VERSION ""

NS_ :

BS_:
BU_: Turbocharger OnBoardDataLogger OffBoardDiagnosticTool2 OffBoardDiagnosticTool1 FileServer ParkingBrakeController SeatControl2 FanDriveController SteeringColumnUnit CommunicationUnitRadio CommunicationUnitSatellite CommunicationUnitCellular PropulsionBatteryCharger ChassisController2 ChassisController1 EngineValveControl AuxiliaryHeater2 AuxiliaryHeater1 ClutchUnit RampControl InformationSystem1 SuspensionSystemController2 OilSensor VehicleDynamicStability ExhaustEmissionController TransmissionDisplay2 TransmissionDisplay1 ClimateControl2 WaterPumpController RearAxleSteeringController LightingOperatorControl SeatController1 IgnitionController2 IgnitionController1 TirePressureController CabController2 CabController1 PneumaticSystemController SuspensionSystemController1 HydraulicPumpController EnduranceBrakingSystem RetarderExhaustEngine2 OnBoardDiagnosticUnit HeadwayController RetarderExhaustEngine1 CabDisplay1 ManagementComputer VirtualTerminal OffVehicleGateway PowerTakeOffFront HitchControl AuxiliaryValveControl BodyController TractorTrailerBridge1 StarterSystem ElectricalSystem VehicleSecurity VehicleNavigation AerodynamicControl ElectricalChargingSystem ClimateControl1 TripRecorder InstrumentCluster SuspensionDriveAxle2 SuspensionDriveAxle1 SuspensionSteerAxle SteeringController FuelSystem CruiseControl RetarderDriveline RetarderEngine BrakesDriveAxle2 BrakesDriveAxle1 BrakesSystemController BrakesSteerAxle AxleDrive2 AxleDrive1 AxleSteering PowerTakeOff ShiftConsoleSecondary ShiftConsolePrimary Transmission2 Transmission1 Engine2 Engine1 Guidance Unnamed9933

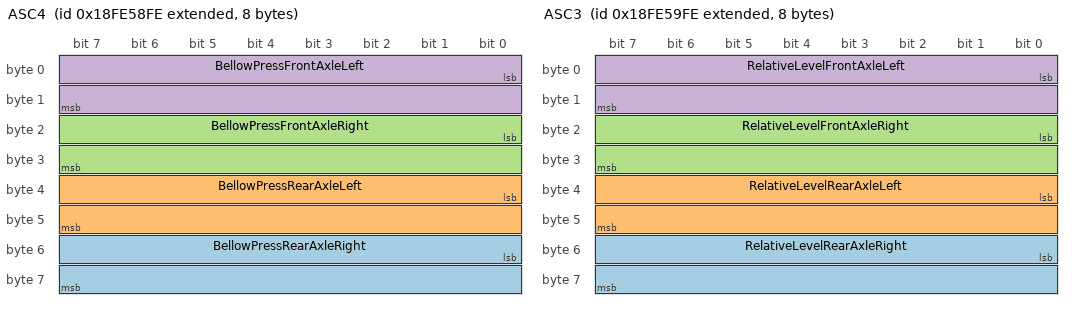
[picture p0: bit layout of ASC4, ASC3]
BO_ 2566805758 ASC4: 8 Vector__XXX
   SG_ BellowPressRearAxleRight : 48|16@1+ (0.1,0) [0|6425.5] "kPa" Vector__XXX
   SG_ BellowPressRearAxleLeft : 32|16@1+ (0.1,0) [0|6425.5] "kPa" Vector__XXX
   SG_ BellowPressFrontAxleRight : 16|16@1+ (0.1,0) [0|6425.5] "kPa" Vector__XXX
   SG_ BellowPressFrontAxleLeft : 0|16@1+ (0.1,0) [0|6425.5] "kPa" Vector__XXX

BO_ 2566806014 ASC3: 8 Vector__XXX
   SG_ RelativeLevelRearAxleRight : 48|16@1+ (0.1,-3200) [-3200|3225.5] "mm" Vector__XXX
   SG_ RelativeLevelRearAxleLeft : 32|16@1+ (0.1,-3200) [-3200|3225.5] "mm" Vector__XXX
   SG_ RelativeLevelFrontAxleRight : 16|16@1+ (0.1,-3200) [-3200|3225.5] "mm" Vector__XXX
   SG_ RelativeLevelFrontAxleLeft : 0|16@1+ (0.1,-3200) [-3200|3225.5] "mm" Vector__XXX

BO_ 2362638078 ASC2: 8 Vector__XXX
   SG_ SpeedDependentLevelCtrlRq : 56|2@1+ (1,0) [0|3] "" Vector__XXX
   SG_ PrhbtAutomaticAirSuspensionCtrl : 58|2@1+ (1,0) [0|3] "" Vector__XXX
   SG_ MemoryLevelRq : 60|4@1+ (1,0) [0|15] "" Vector__XXX
   SG_ AllowLevelCtrlDuringBrakingCmd : 54|2@1+ (1,0) [0|3] "" Vector__XXX
   SG_ ProhibitAirSuspensionCtrl : 52|2@1+ (1,0) [0|3] "" Vector__XXX
   SG_ KneelingCmdRearAxle : 50|2@1+ (1,0) [0|3] "" Vector__XXX
   SG_ KneelingCmdFrontAxle : 48|2@1+ (1,0) [0|3] "" Vector__XXX
   SG_ DamperStiffnessRqLift_TagAxle : 40|8@1+ (0.4,0) [0|100] "%" Vector__XXX
   SG_ DamperStiffnessRqRearAxle : 32|8@1+ (0.4,0) [0|100] "%" Vector__XXX
   SG_ DamperStiffnessRqFrontAxle : 24|8@1+ (0.4,0) [0|100] "%" Vector__XXX
   SG_ LevelCtrlModeRq : 16|4@1+ (1,0) [0|15] "" Vector__XXX
   SG_ NominalLevelRqRearAxle : 12|4@1+ (1,0) [0|15] "" Vector__XXX
   SG_ NominalLevelRqFrontAxle : 8|4@1+ (1,0) [0|15] "" Vector__XXX
   SG_ KneelingCtrlModeRq : 6|2@1+ (1,0) [0|3] "" Vector__XXX
   SG_ KneelingRqRightSide : 4|2@1+ (1,0) [0|3] "" Vector__XXX
   SG_ KneelingRqLeftSide : 2|2@1+ (1,0) [0|3] "" Vector__XXX
   SG_ AutomaticTractionHelp : 0|2@1+ (1,0) [0|3] "" Vector__XXX
   SG_ LiftAxle2PosCmd : 22|2@1+ (1,0) [0|3] "" Vector__XXX
   SG_ LiftAxle1PosCmd : 20|2@1+ (1,0) [0|3] "" Vector__XXX

BO_ 2365479678 ASC1: 8 Vector__XXX
   SG_ SpeedDependantLevelCtrlStatus : 54|2@1+ (1,0) [0|3] "" Vector__XXX
   SG_ MemoryLevel : 60|4@1+ (1,0) [0|15] "" Vector__XXX
   SG_ AllwLvelCtrlDuringBrakingStatus : 52|2@1+ (1,0) [0|3] "" Vector__XXX
   SG_ SspensionCtrlRefusalInformation : 56|4@1+ (1,0) [0|15] "" Vector__XXX
   SG_ SuspensionRemoteCtrl2 : 50|2@1+ (1,0) [0|3] "" Vector__XXX
   SG_ SuspensionRemoteCtrl1 : 48|2@1+ (1,0) [0|3] "" Vector__XXX
   SG_ RearAxleInBumperRange : 42|2@1+ (1,0) [0|3] "" Vector__XXX
   SG_ FrontAxleInBumperRange : 40|2@1+ (1,0) [0|3] "" Vector__XXX
   SG_ DoorRelease : 36|2@1+ (1,0) [0|3] "" Vector__XXX
   SG_ VehicleMotionInhibit : 34|2@1+ (1,0) [0|3] "" Vector__XXX
   SG_ SecurityDevice : 32|2@1+ (1,0) [0|3] "" Vector__XXX
   SG_ LevelCtrlMode : 28|4@1+ (1,0) [0|15] "" Vector__XXX
   SG_ KneelingInformation : 24|4@1+ (1,0) [0|15] "" Vector__XXX
   SG_ LiftingCtrlModeRearAxle : 22|2@1+ (1,0) [0|3] "" Vector__XXX
   SG_ LiftingCtrlModeFrontAxle : 20|2@1+ (1,0) [0|3] "" Vector__XXX
   SG_ LoweringCtrlModeRearAxle : 18|2@1+ (1,0) [0|3] "" Vector__XXX
   SG_ LoweringCtrlModeFrontAxle : 16|2@1+ (1,0) [0|3] "" Vector__XXX
   SG_ AboveNominalLevelRearAxle : 14|2@1+ (1,0) [0|3] "" Vector__XXX
   SG_ AboveNominalLevelFrontAxle : 12|2@1+ (1,0) [0|3] "" Vector__XXX
   SG_ BelowNominalLevelRearAxle : 10|2@1+ (1,0) [0|3] "" Vector__XXX
   SG_ BelowNominalLevelFrontAxle : 8|2@1+ (1,0) [0|3] "" Vector__XXX
   SG_ NominalLevelRearAxle : 4|4@1+ (1,0) [0|15] "" Vector__XXX
   SG_ NominalLevelFrontAxle : 0|4@1+ (1,0) [0|15] "" Vector__XXX
   SG_ LiftAxle2Pos : 46|2@1+ (1,0) [0|3] "" Vector__XXX
   SG_ LiftAxle1Pos : 38|2@1+ (1,0) [0|3] "" Vector__XXX

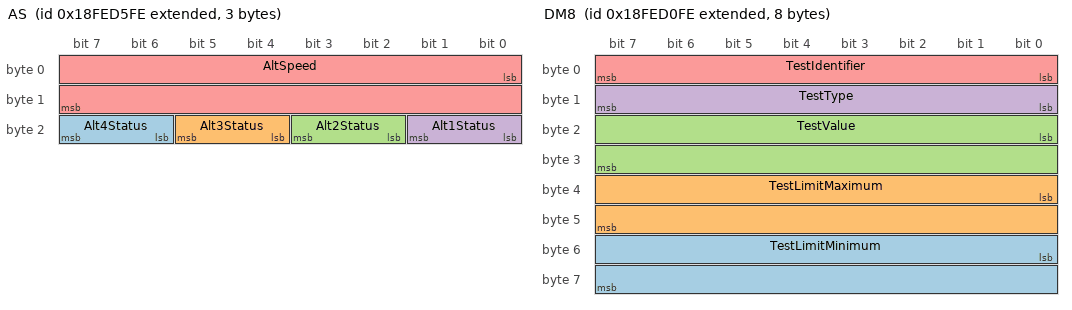
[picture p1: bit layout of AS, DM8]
BO_ 2566837758 AS: 3 Vector__XXX
   SG_ Alt4Status : 22|2@1+ (1,0) [0|3] "" Vector__XXX
   SG_ Alt3Status : 20|2@1+ (1,0) [0|3] "" Vector__XXX
   SG_ Alt2Status : 18|2@1+ (1,0) [0|3] "" Vector__XXX
   SG_ Alt1Status : 16|2@1+ (1,0) [0|3] "" Vector__XXX
   SG_ AltSpeed : 0|16@1+ (0.5,0) [0|32127.5] "rpm" Vector__XXX

BO_ 2633922558 AP: 8 Vector__XXX
   SG_ AuxAbsPressReading : 32|16@1+ (0.5,0) [0|32127.5] "kPa" Vector__XXX
   SG_ AuxGagePressReading1 : 16|16@1+ (0.5,0) [0|32127.5] "kPa" Vector__XXX
   SG_ AuxVacuumPressReading : 0|16@1+ (0.5,0) [0|32127.5] "kPa" Vector__XXX

BO_ 2566775038 AMB2: 8 Vector__XXX
   SG_ SpecificHumidity : 16|16@1+ (0.01,0) [0|642.55] "g/kg" Vector__XXX
   SG_ SolarSensorMax : 8|8@1+ (0.4,0) [0|100] "mW/cm/cm" Vector__XXX
   SG_ SolarIntensityPercent : 0|8@1+ (0.4,0) [0|100] "%" Vector__XXX

BO_ 2566836478 DM8: 8 Vector__XXX
   SG_ TestLimitMinimum : 48|16@1+ (1,0) [0|64255] "" Vector__XXX
   SG_ TestLimitMaximum : 32|16@1+ (1,0) [0|64255] "" Vector__XXX
   SG_ TestValue : 16|16@1+ (1,0) [0|64255] "" Vector__XXX
   SG_ TestType : 8|8@1+ (1,0) [1|64] "" Vector__XXX
   SG_ TestIdentifier : 0|8@1+ (1,0) [1|64] "" Vector__XXX

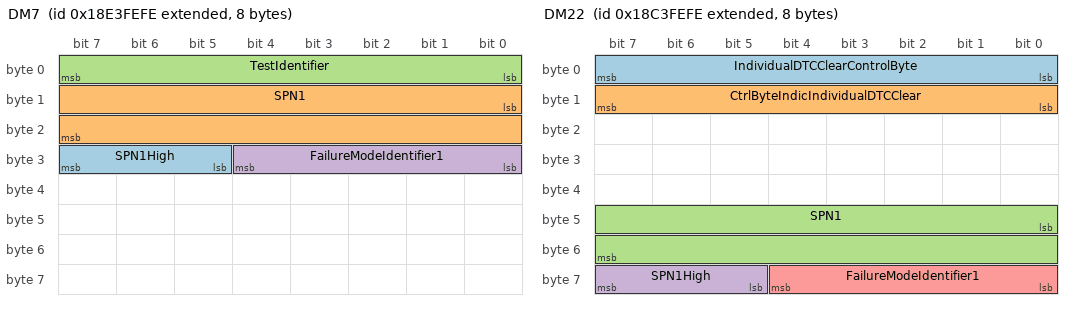
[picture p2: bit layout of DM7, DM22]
BO_ 2565078782 DM7: 8 Vector__XXX
   SG_ SPN1High : 29|3@1+ (1,0) [0|7] "" Vector__XXX
   SG_ SPN1 : 8|16@1+ (1,0) [0|65536] "" Vector__XXX
   SG_ TestIdentifier : 0|8@1+ (1,0) [1|64] "" Vector__XXX
   SG_ FailureModeIdentifier1 : 24|5@1+ (1,0) [0|0] "" Vector__XXX

BO_ 2566836222 DM6: 22 Vector__XXX
   SG_ FlashRedStopLamp : 12|2@1+ (1,0) [0|3] "" Vector__XXX
   SG_ FlashProtectLamp : 8|2@1+ (1,0) [0|3] "" Vector__XXX
   SG_ FlashMalfuncIndicatorLamp : 14|2@1+ (1,0) [0|3] "" Vector__XXX
   SG_ FlashAmberWarningLamp : 10|2@1+ (1,0) [0|3] "" Vector__XXX
   SG_ MalfunctionIndicatorLampStatus : 6|2@1+ (1,0) [0|3] "" Vector__XXX
   SG_ RedStopLampState : 4|2@1+ (1,0) [0|3] "" Vector__XXX
   SG_ AmberWarningLampStatus : 2|2@1+ (1,0) [0|3] "" Vector__XXX
   SG_ ProtectLampStatus : 0|2@1+ (1,0) [0|3] "" Vector__XXX
   SG_ DTC5 : 144|32@1+ (1,0) [0|4.29497e+09] "" Vector__XXX
   SG_ DTC4 : 112|32@1+ (1,0) [0|4.29497e+09] "" Vector__XXX
   SG_ DTC3 : 80|32@1+ (1,0) [0|4.29497e+09] "" Vector__XXX
   SG_ DTC2 : 48|32@1+ (1,0) [0|4.29497e+09] "" Vector__XXX
   SG_ DTC1 : 16|32@1+ (1,0) [0|4.29497e+09] "" Vector__XXX

BO_ 2566835966 DM5: 8 Vector__XXX
   SG_ BoostPressureControlSystemStatus : 57|1@1- (1,0) [0|0] "" Vector__XXX
   SG_ DieselParticulateFilterStatus : 58|1@1- (1,0) [0|0] "" Vector__XXX
   SG_ NOxConvertingCatalystAdsorberSta : 59|1@1- (1,0) [0|0] "" Vector__XXX
   SG_ NMHCConvertingCatalystStatus : 60|1@1- (1,0) [0|0] "" Vector__XXX
   SG_ BoostPressureControlSystemSuppor : 41|1@1- (1,0) [0|0] "" Vector__XXX
   SG_ DieselParticulateFilterSupport : 42|1@1- (1,0) [0|0] "" Vector__XXX
   SG_ NOxConvertingCatalystAdsorberSup : 43|1@1- (1,0) [0|0] "" Vector__XXX
   SG_ NMHCConvertingCatalystSupport : 44|1@1- (1,0) [0|0] "" Vector__XXX
   SG_ MisfireMonitoringSupport : 24|1@1+ (1,0) [0|0] "" Vector__XXX
   SG_ OBDCompliance : 16|8@1+ (1,0) [0|240] "" Vector__XXX
   SG_ PreviouslyActiveTroubleCodes : 8|8@1+ (1,0) [0|240] "" Vector__XXX
   SG_ ActiveTroubleCodes : 0|8@1+ (1,0) [0|240] "" Vector__XXX
   SG_ SecondAirSystemMonStatus : 51|1@1+ (1,0) [0|1] "" Vector__XXX
   SG_ EvaporativeSystemMonStatus : 50|1@1+ (1,0) [0|1] "" Vector__XXX
   SG_ ACSystemRefrigerantMonStatus : 52|1@1+ (1,0) [0|1] "" Vector__XXX
   SG_ OxygenSensorHeaterMonStatus : 54|1@1+ (1,0) [0|1] "" Vector__XXX
   SG_ OxygenSensorMonStatus : 53|1@1+ (1,0) [0|1] "" Vector__XXX
   SG_ EGRSystemMonitoringStatus : 55|1@1+ (1,0) [0|1] "" Vector__XXX
   SG_ CatalystMonStatus : 48|1@1+ (1,0) [0|1] "" Vector__XXX
   SG_ ColdStartAidSystemMonStatus : 56|1@1+ (1,0) [0|1] "" Vector__XXX
   SG_ HeatedCatalystMonStatus : 49|1@1+ (1,0) [0|0] "" Vector__XXX
   SG_ CatalystMonSupp : 32|1@1+ (1,0) [0|1] "" Vector__XXX
   SG_ ColdStartAidSystemMonSupp : 40|1@1+ (1,0) [0|1] "" Vector__XXX
   SG_ HeatedCatalystMonSupp : 33|1@1+ (1,0) [0|0] "" Vector__XXX
   SG_ EvaporativeSystemMonSupp : 34|1@1+ (1,0) [0|1] "" Vector__XXX
   SG_ SecondAirSystemMonSupp : 35|1@1+ (1,0) [0|1] "" Vector__XXX
   SG_ ACSystemRefrigerantMonSupp : 36|1@1+ (1,0) [0|1] "" Vector__XXX
   SG_ OxygenSensorMonSupp : 37|1@1+ (1,0) [0|1] "" Vector__XXX
   SG_ OxygenSensorHeaterMonSupp : 38|1@1+ (1,0) [0|1] "" Vector__XXX
   SG_ EGRSystemMonitoringSupp : 39|1@1+ (1,0) [0|1] "" Vector__XXX
   SG_ MisfireMonitoringStatus : 28|1@1+ (1,0) [0|0] "" Vector__XXX
   SG_ ComprehensiveCompMonStatus : 30|1@1+ (1,0) [0|1] "" Vector__XXX
   SG_ FuelSystemMonitoringStatus : 29|1@1+ (1,0) [0|1] "" Vector__XXX
   SG_ ComprehensiveComponentMonSupp : 26|1@1+ (1,0) [0|0] "" Vector__XXX
   SG_ FuelSystemMonitoringSupport : 25|1@1+ (1,0) [0|1] "" Vector__XXX

BO_ 2566835710 DM4: 13 Vector__XXX
   SG_ EngIntakeManifold1Press : 48|8@1+ (2,0) [0|500] "kPa" Vector__XXX
   SG_ FreezeFrameLength : 0|8@1+ (1,0) [0|255] "Byte" Vector__XXX
   SG_ EngSpeed : 56|16@1+ (0.125,0) [0|8031.88] "rpm" Vector__XXX
   SG_ EngTorqueMode : 40|4@1+ (1,0) [0|15] "" Vector__XXX
   SG_ WheelBasedVehicleSpeed : 88|16@1+ (0.00390625,0) [0|250.996] "km/h" Vector__XXX
   SG_ EngPercentLoadAtCurrentSpeed : 72|8@1+ (1,0) [0|250] "%" Vector__XXX
   SG_ EngineCoolantTemperature : 80|8@1+ (1,-40) [-40|210] "deg C" Vector__XXX
   SG_ DTC1 : 8|32@1+ (1,0) [0|4.29497e+09] "" Vector__XXX

BO_ 2566835454 DM3: 0 Vector__XXX

BO_ 2566764542 DM25: 13 Vector__XXX
   SG_ ExpandedFreezeFrameLength : 0|8@1+ (1,0) [0|255] "Byte" Vector__XXX
   SG_ DTC1 : 8|32@1+ (1,0) [0|4.29497e+09] "" Vector__XXX

BO_ 2566764286 DM24: 12 Vector__XXX
   SG_ SPNSupported1High : 21|3@1+ (1,0) [0|7] "" Vector__XXX
   SG_ SPNSupportTypeSTR3 : 82|1@1+ (1,0) [0|1] "" Vector__XXX
   SG_ SPNSupportTypeSTR2 : 81|1@1+ (1,0) [0|1] "" Vector__XXX
   SG_ SPNSupportTypeEFF3 : 80|1@1+ (1,0) [0|1] "" Vector__XXX
   SG_ SPNSupportTypeEFF2 : 48|1@1+ (1,0) [0|1] "" Vector__XXX
   SG_ SPNSupportTypeDS3 : 50|1@1+ (1,0) [0|1] "" Vector__XXX
   SG_ SPNSupportTypeDS2 : 49|1@1+ (1,0) [0|1] "" Vector__XXX
   SG_ SPNSupported3High : 85|3@1+ (1,0) [0|7] "" Vector__XXX
   SG_ SPNSupported2High : 53|3@1+ (1,0) [0|7] "" Vector__XXX
   SG_ SPNSupported3 : 64|16@1+ (1,0) [0|65535] "" Vector__XXX
   SG_ SPNSupported2 : 32|16@1+ (1,0) [0|65535] "" Vector__XXX
   SG_ SPNDataLength3 : 88|8@1+ (1,0) [0|240] "" Vector__XXX
   SG_ SPNSupportTypeSTR1 : 18|1@1+ (1,0) [0|1] "" Vector__XXX
   SG_ SPNSupportTypeDS1 : 17|1@1+ (1,0) [0|1] "" Vector__XXX
   SG_ SPNSupportTypeEFF1 : 16|1@1+ (1,0) [0|1] "" Vector__XXX
   SG_ SPNDataLength2 : 56|8@1+ (1,0) [0|240] "" Vector__XXX
   SG_ SPNDataLength1 : 24|8@1+ (1,0) [0|240] "" Vector__XXX
   SG_ SPNSupported1 : 0|16@1+ (1,0) [0|65535] "" Vector__XXX

BO_ 2566764030 DM23: 22 Vector__XXX
   SG_ FlashRedStopLamp : 12|2@1+ (1,0) [0|3] "" Vector__XXX
   SG_ FlashProtectLamp : 8|2@1+ (1,0) [0|3] "" Vector__XXX
   SG_ FlashMalfuncIndicatorLamp : 14|2@1+ (1,0) [0|3] "" Vector__XXX
   SG_ FlashAmberWarningLamp : 10|2@1+ (1,0) [0|3] "" Vector__XXX
   SG_ MalfunctionIndicatorLampStatus : 6|2@1+ (1,0) [0|3] "" Vector__XXX
   SG_ RedStopLampState : 4|2@1+ (1,0) [0|3] "" Vector__XXX
   SG_ AmberWarningLampStatus : 2|2@1+ (1,0) [0|3] "" Vector__XXX
   SG_ ProtectLampStatus : 0|2@1+ (1,0) [0|3] "" Vector__XXX
   SG_ DTC5 : 144|32@1+ (1,0) [0|4.29497e+09] "" Vector__XXX
   SG_ DTC4 : 112|32@1+ (1,0) [0|4.29497e+09] "" Vector__XXX
   SG_ DTC3 : 80|32@1+ (1,0) [0|4.29497e+09] "" Vector__XXX
   SG_ DTC2 : 48|32@1+ (1,0) [0|4.29497e+09] "" Vector__XXX
   SG_ DTC1 : 16|32@1+ (1,0) [0|4.29497e+09] "" Vector__XXX

BO_ 2562981630 DM22: 8 Vector__XXX
   SG_ IndividualDTCClearControlByte : 0|8@1+ (1,0) [0|255] "" Vector__XXX
   SG_ CtrlByteIndicIndividualDTCClear : 8|8@1+ (1,0) [0|255] "" Vector__XXX
   SG_ SPN1 : 40|16@1+ (1,0) [0|65536] "" Vector__XXX
   SG_ SPN1High : 61|3@1+ (1,0) [0|7] "" Vector__XXX
   SG_ FailureModeIdentifier1 : 56|5@1+ (1,0) [0|0] "" Vector__XXX

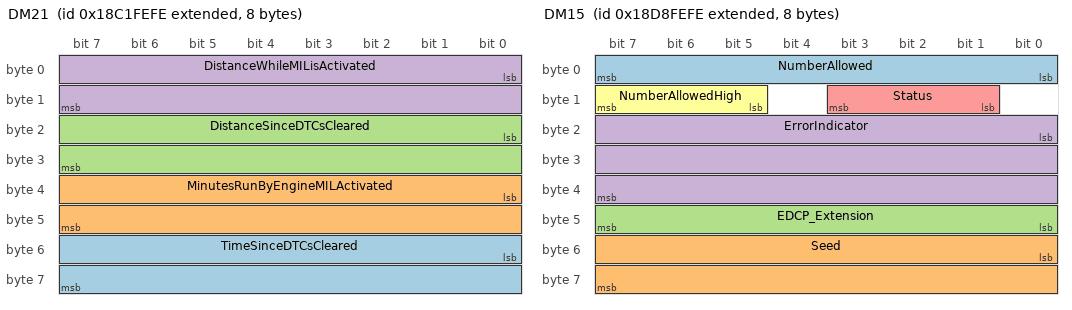
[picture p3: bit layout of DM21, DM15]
BO_ 2562850558 DM21: 8 Vector__XXX
   SG_ TimeSinceDTCsCleared : 48|16@1+ (1,0) [0|64255] "mins" Vector__XXX
   SG_ MinutesRunByEngineMILActivated : 32|16@1+ (1,0) [0|64255] "mins" Vector__XXX
   SG_ DistanceSinceDTCsCleared : 16|16@1+ (1,0) [0|64255] "km" Vector__XXX
   SG_ DistanceWhileMILisActivated : 0|16@1+ (1,0) [0|64255] "km" Vector__XXX

BO_ 2562916094 DM20: 11 Vector__XXX
   SG_ ApplSysMonitorDenominator : 72|16@1+ (1,0) [0|65535] "" Vector__XXX
   SG_ ApplSysMonitorNumerator : 56|16@1+ (1,0) [0|65535] "" Vector__XXX
   SG_ SPNofApplSysMonitor : 32|24@1+ (1,0) [0|524287] "" Vector__XXX
   SG_ OBDMonitoringCondEncountered : 16|16@1+ (1,0) [0|65535] "" Vector__XXX
   SG_ IgnitionCycleCounter : 0|16@1+ (1,0) [0|65535] "" Vector__XXX

BO_ 2566835198 DM2: 22 Vector__XXX
   SG_ MalfunctionIndicatorLampStatus : 6|2@1+ (1,0) [0|3] "" Vector__XXX
   SG_ RedStopLampState : 4|2@1+ (1,0) [0|3] "" Vector__XXX
   SG_ AmberWarningLampStatus : 2|2@1+ (1,0) [0|3] "" Vector__XXX
   SG_ ProtectLampStatus : 0|2@1+ (1,0) [0|3] "" Vector__XXX
   SG_ FlashRedStopLamp : 12|2@1+ (1,0) [0|3] "" Vector__XXX
   SG_ FlashProtectLamp : 8|2@1+ (1,0) [0|3] "" Vector__XXX
   SG_ FlashMalfuncIndicatorLamp : 14|2@1+ (1,0) [0|3] "" Vector__XXX
   SG_ FlashAmberWarningLamp : 10|2@1+ (1,0) [0|3] "" Vector__XXX
   SG_ DTC5 : 144|32@1+ (1,0) [0|4.29497e+09] "" Vector__XXX
   SG_ DTC4 : 112|32@1+ (1,0) [0|4.29497e+09] "" Vector__XXX
   SG_ DTC3 : 80|32@1+ (1,0) [0|4.29497e+09] "" Vector__XXX
   SG_ DTC2 : 48|32@1+ (1,0) [0|4.29497e+09] "" Vector__XXX
   SG_ DTC1 : 16|32@1+ (1,0) [0|4.29497e+09] "" Vector__XXX

BO_ 2564030206 DM19: 20 Vector__XXX
   SG_ CalibrationID4 : 128|32@1+ (1,0) [0|4.29497e+09] "" Vector__XXX
   SG_ CalibrationID3 : 96|32@1+ (1,0) [0|4.29497e+09] "" Vector__XXX
   SG_ CalibrationID2 : 64|32@1+ (1,0) [0|4.29497e+09] "" Vector__XXX
   SG_ CalibrationID1 : 32|32@1+ (1,0) [0|4.29497e+09] "" Vector__XXX
   SG_ CalibrationVerificationNumber : 0|32@1+ (1,0) [0|4.29497e+09] "" Vector__XXX

BO_ 2564226814 DM17: 1 Vector__XXX
   SG_ BootLoadData : 0|8@1- (1,0) [0|0] "" Vector__XXX

BO_ 2564292350 DM16: 2 Vector__XXX
   SG_ RawBinaryData : 8|8@1- (1,0) [0|0] "" Vector__XXX
   SG_ NumberOfOccurance : 0|8@1+ (1,0) [0|0] "" Vector__XXX

BO_ 2564357886 DM15: 8 Vector__XXX
   SG_ NumberAllowed : 0|8@1+ (1,0) [0|2047] "" Vector__XXX
   SG_ Seed : 48|16@1+ (1,0) [0|65535] "" Vector__XXX
   SG_ EDCP_Extension : 40|8@1+ (1,0) [0|255] "" Vector__XXX
   SG_ ErrorIndicator : 16|24@1+ (1,0) [0|1.67772e+07] "" Vector__XXX
   SG_ Status : 9|3@1+ (1,0) [0|7] "" Vector__XXX
   SG_ NumberAllowedHigh : 13|3@1+ (1,0) [0|7] "" Vector__XXX

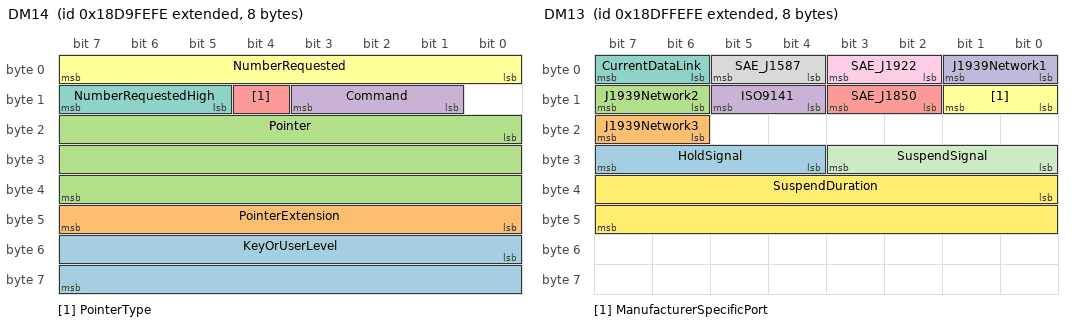
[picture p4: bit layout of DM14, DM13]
BO_ 2564423422 DM14: 8 Vector__XXX
   SG_ KeyOrUserLevel : 48|16@1+ (1,0) [0|65535] "" Vector__XXX
   SG_ PointerExtension : 40|8@1+ (1,0) [0|255] "" Vector__XXX
   SG_ Pointer : 16|24@1+ (1,0) [0|1.67772e+07] "" Vector__XXX
   SG_ Command : 9|3@1+ (1,0) [0|7] "" Vector__XXX
   SG_ PointerType : 12|1@1+ (1,0) [0|1] "" Vector__XXX
   SG_ NumberRequested : 0|8@1+ (1,0) [0|2047] "" Vector__XXX
   SG_ NumberRequestedHigh : 13|3@1+ (1,0) [0|7] "" Vector__XXX

BO_ 2564816638 DM13: 8 Vector__XXX
   SG_ HoldSignal : 28|4@1+ (1,0) [0|15] "" Vector__XXX
   SG_ J1939Network3 : 22|2@1+ (1,0) [0|3] "" Vector__XXX
   SG_ J1939Network2 : 14|2@1+ (1,0) [0|3] "" Vector__XXX
   SG_ ISO9141 : 12|2@1+ (1,0) [0|3] "" Vector__XXX
   SG_ SAE_J1850 : 10|2@1+ (1,0) [0|3] "" Vector__XXX
   SG_ ManufacturerSpecificPort : 8|2@1+ (1,0) [0|3] "" Vector__XXX
   SG_ CurrentDataLink : 6|2@1+ (1,0) [0|3] "" Vector__XXX
   SG_ SAE_J1587 : 4|2@1+ (1,0) [0|3] "" Vector__XXX
   SG_ SAE_J1922 : 2|2@1+ (1,0) [0|3] "" Vector__XXX
   SG_ J1939Network1 : 0|2@1+ (1,0) [0|3] "" Vector__XXX
   SG_ SuspendSignal : 24|4@1+ (1,0) [0|15] "" Vector__XXX
   SG_ SuspendDuration : 32|16@1+ (1,0) [0|64255] "sec" Vector__XXX

BO_ 2566837502 DM12: 22 Vector__XXX
   SG_ FlashRedStopLamp : 12|2@1+ (1,0) [0|3] "" Vector__XXX
   SG_ FlashProtectLamp : 8|2@1+ (1,0) [0|3] "" Vector__XXX
   SG_ MalfunctionIndicatorLampStatus : 6|2@1+ (1,0) [0|3] "" Vector__XXX
   SG_ RedStopLampState : 4|2@1+ (1,0) [0|3] "" Vector__XXX
   SG_ AmberWarningLampStatus : 2|2@1+ (1,0) [0|3] "" Vector__XXX
   SG_ ProtectLampStatus : 0|2@1+ (1,0) [0|3] "" Vector__XXX
   SG_ FlashMalfuncIndicatorLamp : 14|2@1+ (1,0) [0|3] "" Vector__XXX
   SG_ FlashAmberWarningLamp : 10|2@1+ (1,0) [0|3] "" Vector__XXX
   SG_ DTC5 : 144|32@1+ (1,0) [0|4.29497e+09] "" Vector__XXX
   SG_ DTC4 : 112|32@1+ (1,0) [0|4.29497e+09] "" Vector__XXX
   SG_ DTC3 : 80|32@1+ (1,0) [0|4.29497e+09] "" Vector__XXX
   SG_ DTC2 : 48|32@1+ (1,0) [0|4.29497e+09] "" Vector__XXX
   SG_ DTC1 : 16|32@1+ (1,0) [0|4.29497e+09] "" Vector__XXX

BO_ 2566837246 DM11: 0 Vector__XXX

BO_ 2566836990 DM10: 8 Vector__XXX
   SG_ TestIdentifierSupported : 0|64@1+ (1,0) [1|1.84467e+19] "" Vector__XXX

BO_ 2566834942 DM1: 22 Vector__XXX
   SG_ FlashRedStopLamp : 12|2@1+ (1,0) [0|3] "" Vector__XXX
   SG_ FlashProtectLamp : 8|2@1+ (1,0) [0|3] "" Vector__XXX
   SG_ FlashMalfuncIndicatorLamp : 14|2@1+ (1,0) [0|3] "" Vector__XXX
   SG_ FlashAmberWarningLamp : 10|2@1+ (1,0) [0|3] "" Vector__XXX
   SG_ MalfunctionIndicatorLampStatus : 6|2@1+ (1,0) [0|3] "" Vector__XXX
   SG_ AmberWarningLampStatus : 2|2@1+ (1,0) [0|3] "" Vector__XXX
   SG_ RedStopLampState : 4|2@1+ (1,0) [0|3] "" Vector__XXX
   SG_ ProtectLampStatus : 0|2@1+ (1,0) [0|3] "" Vector__XXX
   SG_ DTC5 : 144|32@1+ (1,0) [0|4.29497e+09] "" Vector__XXX
   SG_ DTC4 : 112|32@1+ (1,0) [0|4.29497e+09] "" Vector__XXX
   SG_ DTC3 : 80|32@1+ (1,0) [0|4.29497e+09] "" Vector__XXX
   SG_ DTC2 : 48|32@1+ (1,0) [0|4.29497e+09] "" Vector__XXX
   SG_ DTC1 : 16|32@1+ (1,0) [0|4.29497e+09] "" Vector__XXX

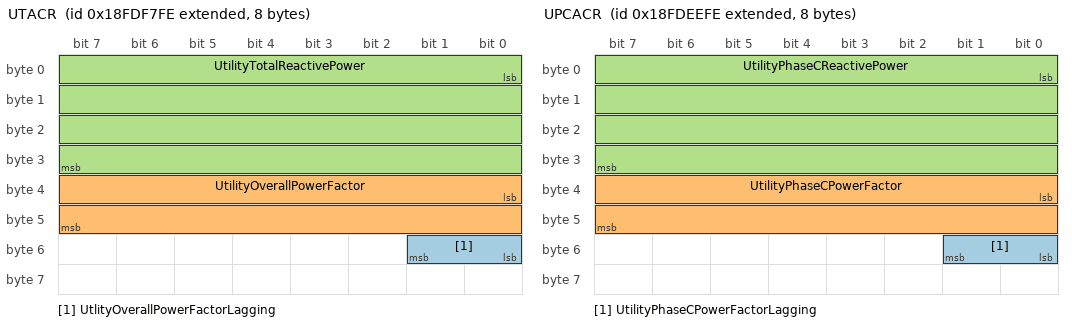
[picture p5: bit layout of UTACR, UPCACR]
BO_ 2566780926 UTACR: 8 Vector__XXX
   SG_ UtlityOverallPowerFactorLagging : 48|2@1+ (1,0) [0|3] "" Vector__XXX
   SG_ UtilityOverallPowerFactor : 32|16@1+ (1,-1) [-1|2.92181] "" Vector__XXX
   SG_ UtilityTotalReactivePower : 0|32@1+ (1,-2e+09) [-2e+09|2.21108e+09] "VAr" Vector__XXX

BO_ 2566781182 UTACP: 8 Vector__XXX
   SG_ UtilityTotalApparentPower : 32|32@1+ (1,-2e+09) [-2e+09|2.21108e+09] "VA" Vector__XXX
   SG_ UtilityTotalRealPower : 0|32@1+ (1,-2e+09) [-2e+09|2.21108e+09] "W" Vector__XXX

BO_ 2566778366 UTACE: 8 Vector__XXX
   SG_ UtilityTotalKWHoursImport : 32|32@1+ (1,0) [0|4.21108e+09] "kWh" Vector__XXX
   SG_ UtilityTotalKWHoursExport : 0|32@1+ (1,0) [0|4.21108e+09] "kWh" Vector__XXX

BO_ 2566778622 UPCACR: 8 Vector__XXX
   SG_ UtilityPhaseCPowerFactorLagging : 48|2@1+ (1,0) [0|3] "" Vector__XXX
   SG_ UtilityPhaseCPowerFactor : 32|16@1+ (1,-1) [-1|2.92181] "" Vector__XXX
   SG_ UtilityPhaseCReactivePower : 0|32@1+ (1,-2e+09) [-2e+09|2.21108e+09] "VAr" Vector__XXX

BO_ 2566778878 UPCACP: 8 Vector__XXX
   SG_ UtilityPhaseCApparentPower : 32|32@1+ (1,-2e+09) [-2e+09|2.21108e+09] "VA" Vector__XXX
   SG_ UtilityPhaseCRealPower : 0|32@1+ (1,-2e+09) [-2e+09|2.21108e+09] "W" Vector__XXX

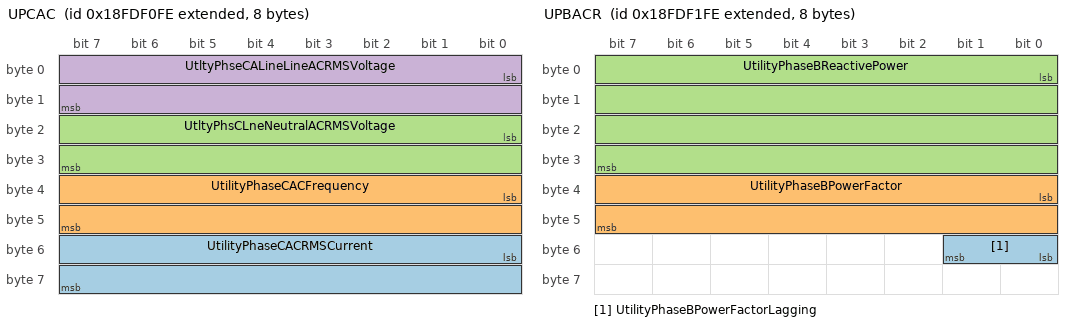
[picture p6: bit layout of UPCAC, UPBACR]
BO_ 2566779134 UPCAC: 8 Vector__XXX
   SG_ UtilityPhaseCACRMSCurrent : 48|16@1+ (1,0) [0|64255] "A" Vector__XXX
   SG_ UtilityPhaseCACFrequency : 32|16@1+ (1,0) [0|501.992] "Hz" Vector__XXX
   SG_ UtltyPhsCLneNeutralACRMSVoltage : 16|16@1+ (1,0) [0|64255] "V" Vector__XXX
   SG_ UtltyPhseCALineLineACRMSVoltage : 0|16@1+ (1,0) [0|64255] "V" Vector__XXX

BO_ 2566779390 UPBACR: 8 Vector__XXX
   SG_ UtilityPhaseBPowerFactorLagging : 48|2@1+ (1,0) [0|3] "" Vector__XXX
   SG_ UtilityPhaseBPowerFactor : 32|16@1+ (1,-1) [-1|2.92181] "" Vector__XXX
   SG_ UtilityPhaseBReactivePower : 0|32@1+ (1,-2e+09) [-2e+09|2.21108e+09] "VAr" Vector__XXX

BO_ 2566779646 UPBACP: 8 Vector__XXX
   SG_ UtilityPhaseBApparentPower : 32|32@1+ (1,-2e+09) [-2e+09|2.21108e+09] "VA" Vector__XXX
   SG_ UtilityPhaseBRealPower : 0|32@1+ (1,-2e+09) [-2e+09|2.21108e+09] "W" Vector__XXX

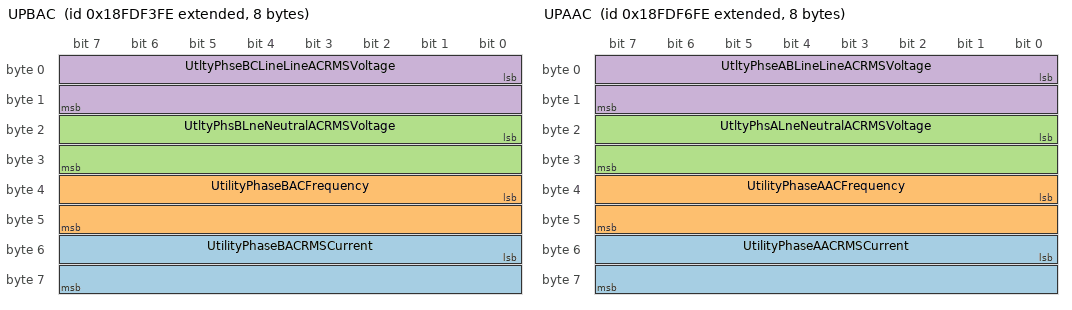
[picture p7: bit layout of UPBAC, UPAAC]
BO_ 2566779902 UPBAC: 8 Vector__XXX
   SG_ UtilityPhaseBACRMSCurrent : 48|16@1+ (1,0) [0|64255] "A" Vector__XXX
   SG_ UtilityPhaseBACFrequency : 32|16@1+ (1,0) [0|501.992] "Hz" Vector__XXX
   SG_ UtltyPhsBLneNeutralACRMSVoltage : 16|16@1+ (1,0) [0|64255] "V" Vector__XXX
   SG_ UtltyPhseBCLineLineACRMSVoltage : 0|16@1+ (1,0) [0|64255] "V" Vector__XXX

BO_ 2566780158 UPACCR: 8 Vector__XXX
   SG_ UtilityPhaseAPowerFactorLagging : 48|2@1+ (1,0) [0|3] "" Vector__XXX
   SG_ UtilityPhaseAPowerFactor : 32|16@1+ (1,-1) [-1|2.92181] "" Vector__XXX
   SG_ UtilityPhaseAReactivePower : 0|32@1+ (1,-2e+09) [-2e+09|2.21108e+09] "VAr" Vector__XXX

BO_ 2566780414 UPAACP: 8 Vector__XXX
   SG_ UtilityPhaseAApparentPower : 32|32@1+ (1,-2e+09) [-2e+09|2.21108e+09] "VA" Vector__XXX
   SG_ UtilityPhaseARealPower : 0|32@1+ (1,-2e+09) [-2e+09|2.21108e+09] "W" Vector__XXX

BO_ 2566780670 UPAAC: 8 Vector__XXX
   SG_ UtilityPhaseAACRMSCurrent : 48|16@1+ (1,0) [0|64255] "A" Vector__XXX
   SG_ UtilityPhaseAACFrequency : 32|16@1+ (1,0) [0|501.992] "Hz" Vector__XXX
   SG_ UtltyPhsALneNeutralACRMSVoltage : 16|16@1+ (1,0) [0|64255] "V" Vector__XXX
   SG_ UtltyPhseABLineLineACRMSVoltage : 0|16@1+ (1,0) [0|64255] "V" Vector__XXX

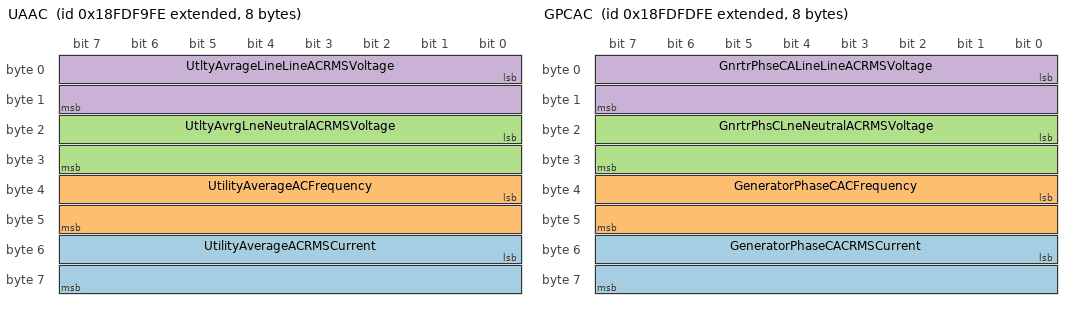
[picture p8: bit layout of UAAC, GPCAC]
BO_ 2566781438 UAAC: 8 Vector__XXX
   SG_ UtilityAverageACRMSCurrent : 48|16@1+ (1,0) [0|64255] "A" Vector__XXX
   SG_ UtilityAverageACFrequency : 32|16@1+ (1,0) [0|501.992] "Hz" Vector__XXX
   SG_ UtltyAvrgLneNeutralACRMSVoltage : 16|16@1+ (1,0) [0|64255] "V" Vector__XXX
   SG_ UtltyAvrageLineLineACRMSVoltage : 0|16@1+ (1,0) [0|64255] "V" Vector__XXX

BO_ 2566784254 GTACR: 8 Vector__XXX
   SG_ GnrtorOverallPowerFactorLagging : 48|2@1+ (1,0) [0|3] "" Vector__XXX
   SG_ GeneratorOverallPowerFactor : 32|16@1+ (1,-1) [-1|2.92181] "" Vector__XXX
   SG_ GeneratorTotalReactivePower : 0|32@1+ (1,-2e+09) [-2e+09|2.21108e+09] "VAr" Vector__XXX

BO_ 2566784510 GTACP: 8 Vector__XXX
   SG_ GeneratorTotalApparentPower : 32|32@1+ (1,-2e+09) [-2e+09|2.21108e+09] "VA" Vector__XXX
   SG_ GeneratorTotalRealPower : 0|32@1+ (1,-2e+09) [-2e+09|2.21108e+09] "W" Vector__XXX

BO_ 2566781694 GTACE: 8 Vector__XXX
   SG_ GeneratorTotalKWHoursImport : 32|32@1+ (1,0) [0|4.21108e+09] "kWh" Vector__XXX
   SG_ GeneratorTotalKWHoursExport : 0|32@1+ (1,0) [0|4.21108e+09] "kWh" Vector__XXX

BO_ 2566781950 GPCACR: 8 Vector__XXX
   SG_ GnratorPhaseCPowerFactorLagging : 48|2@1+ (1,0) [0|3] "" Vector__XXX
   SG_ GeneratorPhaseCPowerFactor : 32|16@1+ (1,-1) [-1|2.92181] "" Vector__XXX
   SG_ GeneratorPhaseCReactivePower : 0|32@1+ (1,-2e+09) [-2e+09|2.21108e+09] "VAr" Vector__XXX

BO_ 2566782206 GPCACP: 8 Vector__XXX
   SG_ GeneratorPhaseCApparentPower : 32|32@1+ (1,-2e+09) [-2e+09|2.21108e+09] "VA" Vector__XXX
   SG_ GeneratorPhaseCRealPower : 0|32@1+ (1,-2e+09) [-2e+09|2.21108e+09] "W" Vector__XXX

BO_ 2566782462 GPCAC: 8 Vector__XXX
   SG_ GeneratorPhaseCACRMSCurrent : 48|16@1+ (1,0) [0|64255] "A" Vector__XXX
   SG_ GeneratorPhaseCACFrequency : 32|16@1+ (1,0) [0|501.992] "Hz" Vector__XXX
   SG_ GnrtrPhsCLneNeutralACRMSVoltage : 16|16@1+ (1,0) [0|64255] "V" Vector__XXX
   SG_ GnrtrPhseCALineLineACRMSVoltage : 0|16@1+ (1,0) [0|64255] "V" Vector__XXX

BO_ 2566782718 GPBACRP: 8 Vector__XXX
   SG_ GnratorPhaseBPowerFactorLagging : 48|2@1+ (1,0) [0|3] "" Vector__XXX
   SG_ GeneratorPhaseBPowerFactor : 32|16@1+ (1,-1) [-1|2.92181] "" Vector__XXX
   SG_ GeneratorPhaseBReactivePower : 0|32@1+ (1,-2e+09) [-2e+09|2.21108e+09] "VAr" Vector__XXX

BO_ 2566782974 GPBACP: 8 Vector__XXX
   SG_ GeneratorPhaseBApparentPower : 32|32@1+ (1,-2e+09) [-2e+09|2.21108e+09] "VA" Vector__XXX
   SG_ GeneratorPhaseBRealPower : 0|32@1+ (1,-2e+09) [-2e+09|2.21108e+09] "W" Vector__XXX

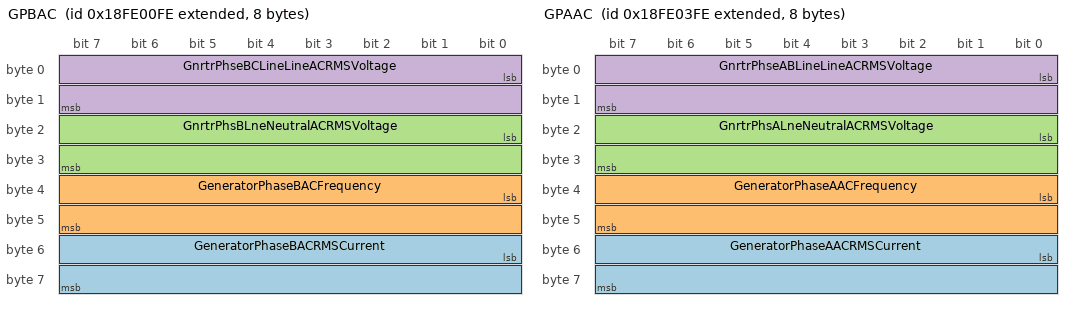
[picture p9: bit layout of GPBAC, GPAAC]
BO_ 2566783230 GPBAC: 8 Vector__XXX
   SG_ GeneratorPhaseBACRMSCurrent : 48|16@1+ (1,0) [0|64255] "A" Vector__XXX
   SG_ GeneratorPhaseBACFrequency : 32|16@1+ (1,0) [0|501.992] "Hz" Vector__XXX
   SG_ GnrtrPhsBLneNeutralACRMSVoltage : 16|16@1+ (1,0) [0|64255] "V" Vector__XXX
   SG_ GnrtrPhseBCLineLineACRMSVoltage : 0|16@1+ (1,0) [0|64255] "V" Vector__XXX

BO_ 2566783486 GPAACR: 8 Vector__XXX
   SG_ GnratorPhaseAPowerFactorLagging : 48|2@1+ (1,0) [0|3] "" Vector__XXX
   SG_ GeneratorPhaseAPowerFactor : 32|16@1+ (1,-1) [-1|2.92181] "" Vector__XXX
   SG_ GeneratorPhaseAReactivePower : 0|32@1+ (1,-2e+09) [-2e+09|2.21108e+09] "VAr" Vector__XXX

BO_ 2566783742 GPAACP: 8 Vector__XXX
   SG_ GeneratorPhaseAApparentPower : 32|32@1+ (1,-2e+09) [-2e+09|2.21108e+09] "VA" Vector__XXX
   SG_ GeneratorPhaseARealPower : 0|32@1+ (1,-2e+09) [-2e+09|2.21108e+09] "W" Vector__XXX

BO_ 2566783998 GPAAC: 8 Vector__XXX
   SG_ GeneratorPhaseAACRMSCurrent : 48|16@1+ (1,0) [0|64255] "A" Vector__XXX
   SG_ GeneratorPhaseAACFrequency : 32|16@1+ (1,0) [0|501.992] "Hz" Vector__XXX
   SG_ GnrtrPhsALneNeutralACRMSVoltage : 16|16@1+ (1,0) [0|64255] "V" Vector__XXX
   SG_ GnrtrPhseABLineLineACRMSVoltage : 0|16@1+ (1,0) [0|64255] "V" Vector__XXX

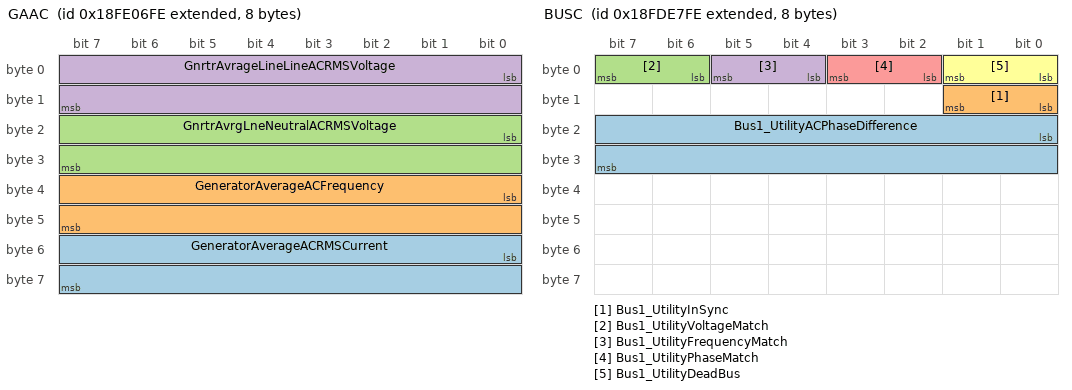
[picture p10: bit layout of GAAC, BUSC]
BO_ 2566784766 GAAC: 8 Vector__XXX
   SG_ GeneratorAverageACRMSCurrent : 48|16@1+ (1,0) [0|64255] "A" Vector__XXX
   SG_ GeneratorAverageACFrequency : 32|16@1+ (1,0) [0|501.992] "Hz" Vector__XXX
   SG_ GnrtrAvrgLneNeutralACRMSVoltage : 16|16@1+ (1,0) [0|64255] "V" Vector__XXX
   SG_ GnrtrAvrageLineLineACRMSVoltage : 0|16@1+ (1,0) [0|64255] "V" Vector__XXX

BO_ 2566776830 BUSC: 8 Vector__XXX
   SG_ Bus1_UtilityACPhaseDifference : 16|16@1+ (1,-200) [-200|301.99] "deg" Vector__XXX
   SG_ Bus1_UtilityInSync : 8|2@1+ (1,0) [0|3] "" Vector__XXX
   SG_ Bus1_UtilityVoltageMatch : 6|2@1+ (1,0) [0|3] "" Vector__XXX
   SG_ Bus1_UtilityFrequencyMatch : 4|2@1+ (1,0) [0|3] "" Vector__XXX
   SG_ Bus1_UtilityPhaseMatch : 2|2@1+ (1,0) [0|3] "" Vector__XXX
   SG_ Bus1_UtilityDeadBus : 0|2@1+ (1,0) [0|3] "" Vector__XXX

BO_ 2566777342 BPCAC: 8 Vector__XXX
   SG_ Bus1PhaseCACFrequency : 32|16@1+ (1,0) [0|501.992] "Hz" Vector__XXX
   SG_ Bs1PhseCLineNeutralACRMSVoltage : 16|16@1+ (1,0) [0|64255] "V" Vector__XXX
   SG_ Bus1PhaseCALineLineACRMSVoltage : 0|16@1+ (1,0) [0|64255] "V" Vector__XXX

BO_ 2566777598 BPBAC: 8 Vector__XXX
   SG_ Bus1PhaseBACFrequency : 32|16@1+ (1,0) [0|501.992] "Hz" Vector__XXX
   SG_ Bs1PhseBLineNeutralACRMSVoltage : 16|16@1+ (1,0) [0|64255] "V" Vector__XXX
   SG_ Bus1PhaseBCLineLineACRMSVoltage : 0|16@1+ (1,0) [0|64255] "V" Vector__XXX

BO_ 2566777854 BPAAC: 8 Vector__XXX
   SG_ Bus1PhaseAACFrequency : 32|16@1+ (1,0) [0|501.992] "Hz" Vector__XXX
   SG_ Bs1PhseALineNeutralACRMSVoltage : 16|16@1+ (1,0) [0|64255] "V" Vector__XXX
   SG_ Bus1PhaseABLineLineACRMSVoltage : 0|16@1+ (1,0) [0|64255] "V" Vector__XXX

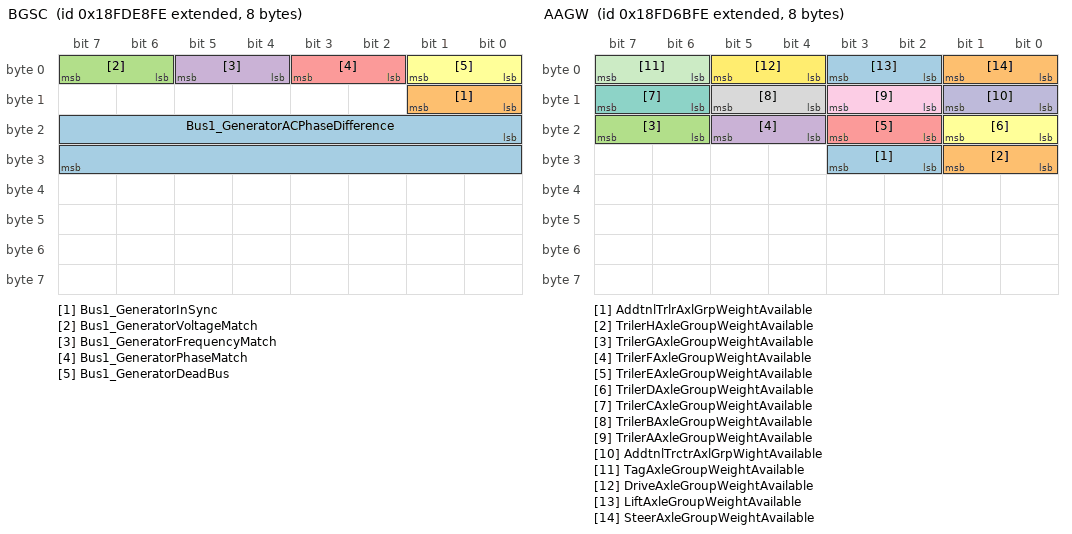
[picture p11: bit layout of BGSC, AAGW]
BO_ 2566777086 BGSC: 8 Vector__XXX
   SG_ Bus1_GeneratorACPhaseDifference : 16|16@1+ (1,-200) [-200|301.99] "deg" Vector__XXX
   SG_ Bus1_GeneratorInSync : 8|2@1+ (1,0) [0|3] "" Vector__XXX
   SG_ Bus1_GeneratorVoltageMatch : 6|2@1+ (1,0) [0|3] "" Vector__XXX
   SG_ Bus1_GeneratorFrequencyMatch : 4|2@1+ (1,0) [0|3] "" Vector__XXX
   SG_ Bus1_GeneratorPhaseMatch : 2|2@1+ (1,0) [0|3] "" Vector__XXX
   SG_ Bus1_GeneratorDeadBus : 0|2@1+ (1,0) [0|3] "" Vector__XXX

BO_ 2566778110 BAAC: 8 Vector__XXX
   SG_ Bus1AverageACFrequency : 32|16@1+ (1,0) [0|501.992] "Hz" Vector__XXX
   SG_ Bs1AvrgeLineNeutralACRMSVoltage : 16|16@1+ (1,0) [0|64255] "V" Vector__XXX
   SG_ Bus1AverageLineLineACRMSVoltage : 0|16@1+ (1,0) [0|64255] "V" Vector__XXX

BO_ 2633895422 WSMSTR: 8 Vector__XXX
   SG_ NumberOfMembers : 0|8@1+ (1,0) [0|0] "" Vector__XXX

BO_ 2566838526 CA: 9 Vector__XXX
   SG_ AddressAssignment : 64|8@1+ (1,0) [0|255] "" Vector__XXX
   SG_ ArbitraryAddressCapable : 63|1@1+ (1,0) [0|1] "" Vector__XXX
   SG_ IndustryGroup M : 60|3@1+ (1,0) [0|7] "" Vector__XXX
   SG_ VehicleSystemInstance : 56|4@1+ (1,0) [0|15] "" Vector__XXX
   SG_ Function : 40|8@1+ (1,0) [0|255] "" Vector__XXX
   SG_ VehicleSystem m0 : 49|7@1+ (1,0) [0|127] "" Vector__XXX
   SG_ FunctionInstance : 35|5@1+ (1,0) [0|31] "" Vector__XXX
   SG_ ECUInstance : 32|3@1+ (1,0) [0|7] "" Vector__XXX
   SG_ ManufacturerCode : 21|11@1+ (1,0) [0|2047] "" Vector__XXX
   SG_ IdentityNumber : 0|21@1+ (1,0) [0|2.09715e+06] "" Vector__XXX
   SG_ VehicleSystem5 m5 : 49|7@1+ (1,0) [0|127] "" Vector__XXX
   SG_ VehicleSystem4 m4 : 49|7@1+ (1,0) [0|127] "" Vector__XXX
   SG_ VehicleSystem3 m3 : 49|7@1+ (1,0) [0|127] "" Vector__XXX
   SG_ VehicleSystem2 m2 : 49|7@1+ (1,0) [0|127] "" Vector__XXX
   SG_ VehicleSystem1 m1 : 49|7@1+ (1,0) [0|127] "" Vector__XXX

BO_ 2565799678 ACL: 8 Vector__XXX
   SG_ ArbitraryAddressCapable : 63|1@1+ (1,0) [0|1] "" Vector__XXX
   SG_ IndustryGroup M : 60|3@1+ (1,0) [0|7] "" Vector__XXX
   SG_ VehicleSystemInstance : 56|4@1+ (1,0) [0|15] "" Vector__XXX
   SG_ Function : 40|8@1+ (1,0) [0|255] "" Vector__XXX
   SG_ FunctionInstance : 35|5@1+ (1,0) [0|31] "" Vector__XXX
   SG_ ECUInstance : 32|3@1+ (1,0) [0|7] "" Vector__XXX
   SG_ ManufacturerCode : 21|11@1+ (1,0) [0|2047] "" Vector__XXX
   SG_ IdentityNumber : 0|21@1+ (1,0) [0|2.09715e+06] "" Vector__XXX
   SG_ VehicleSystem m0 : 49|7@1+ (1,0) [0|127] "" Vector__XXX
   SG_ VehicleSystem5 m5 : 49|7@1+ (1,0) [0|127] "" Vector__XXX
   SG_ VehicleSystem4 m4 : 49|7@1+ (1,0) [0|127] "" Vector__XXX
   SG_ VehicleSystem3 m3 : 49|7@1+ (1,0) [0|127] "" Vector__XXX
   SG_ VehicleSystem2 m2 : 49|7@1+ (1,0) [0|127] "" Vector__XXX
   SG_ VehicleSystem1 m1 : 49|7@1+ (1,0) [0|127] "" Vector__XXX

BO_ 2563440382 XFER: 8 Vector__XXX
   SG_ ShrtNameOfActualReportingDevice : 32|32@1+ (1,0) [0|0] "(2^32 - 1)" Vector__XXX
   SG_ LengthOfDataForTheReportedPGN : 24|8@1+ (1,0) [0|255] "" Vector__XXX
   SG_ PGNofRequstedInformation : 0|24@1+ (1,0) [0|1.67772e+07] "" Vector__XXX

BO_ 2632711934 TPDT: 8 Vector__XXX
   SG_ SequenceNumber : 0|8@1+ (1,0) [0|255] "" Vector__XXX

BO_ 2632777470 TPCM: 8 Vector__XXX
   SG_ TotalNumberOfPacketsEoMA m19 : 24|8@1+ (1,0) [0|255] "" Vector__XXX
   SG_ TotalMessageSizeEoMA m19 : 8|16@1+ (1,0) [0|64255] "counts" Vector__XXX
   SG_ TotalMessageSizeBAM m32 : 8|16@1+ (1,0) [0|64255] "counts" Vector__XXX
   SG_ TotalNumberOfPacketsBAM m32 : 24|8@1+ (1,0) [0|255] "" Vector__XXX
   SG_ ConnectionAbortReason m255 : 8|8@1+ (1,0) [0|255] "" Vector__XXX
   SG_ NextPacketNumberToBeSent m17 : 16|8@1+ (1,0) [0|255] "" Vector__XXX
   SG_ NumberOfPacketsThatCanBeSent m17 : 8|8@1+ (1,0) [0|255] "" Vector__XXX
   SG_ PGNumber : 40|24@1+ (1,0) [0|1.67772e+07] "" Vector__XXX
   SG_ MaximumNumberOfPackets m16 : 32|8@1+ (1,0) [0|255] "" Vector__XXX
   SG_ TotalNumberOfPackets m16 : 24|8@1+ (1,0) [0|255] "" Vector__XXX
   SG_ TotalMessageSize m16 : 8|16@1+ (1,0) [0|64255] "counts" Vector__XXX
   SG_ ControlByte M : 0|8@1+ (1,0) [0|255] "" Vector__XXX

BO_ 2563374846 RQST2: 8 Vector__XXX
   SG_ UseTransferMode : 24|2@1+ (1,0) [0|3] "" Vector__XXX
   SG_ ParameterGroupNumber : 0|24@1+ (1,0) [0|1.67772e+07] "" Vector__XXX

BO_ 2565537534 RQST: 3 Vector__XXX
   SG_ ParameterGroupNumber : 0|24@1+ (1,0) [0|1.67772e+07] "" Vector__XXX

BO_ 2499635966 AGW: 8 Vector__XXX
   SG_ AxleGroupWeight : 8|16@1+ (2,0) [0|128510] "kg" Vector__XXX
   SG_ AxleGroupLocation : 0|4@1+ (1,0) [0|15] "" Vector__XXX

BO_ 2633853438 AGCW: 8 Vector__XXX
   SG_ AxleGroupLocation : 4|4@1+ (1,0) [0|15] "" Vector__XXX
   SG_ AxleGroupFullWeightCalib : 24|16@1+ (2,0) [0|128510] "kg" Vector__XXX
   SG_ AxleGroupEmptyWeightCalib : 8|16@1+ (2,0) [0|128510] "kg" Vector__XXX

BO_ 2432520702 ACCVC: 8 Vector__XXX
   SG_ DsrdAftrcoolerCoolantIntakeTemp : 8|8@1+ (1,-40) [-40|210] "deg C" Vector__XXX
   SG_ DsrdAftrclrClntThrmostatOpening : 16|8@1+ (0.4,0) [0|100] "%" Vector__XXX
   SG_ AftrcoolerCoolantThermostatMode : 0|2@1+ (1,0) [0|3] "" Vector__XXX

BO_ 2566745086 AAGW: 8 Vector__XXX
   SG_ AddtnlTrlrAxlGrpWeightAvailable : 26|2@1+ (1,0) [0|3] "" Vector__XXX
   SG_ TrilerHAxleGroupWeightAvailable : 24|2@1+ (1,0) [0|3] "" Vector__XXX
   SG_ TrilerGAxleGroupWeightAvailable : 22|2@1+ (1,0) [0|3] "" Vector__XXX
   SG_ TrilerFAxleGroupWeightAvailable : 20|2@1+ (1,0) [0|3] "" Vector__XXX
   SG_ TrilerEAxleGroupWeightAvailable : 18|2@1+ (1,0) [0|3] "" Vector__XXX
   SG_ TrilerDAxleGroupWeightAvailable : 16|2@1+ (1,0) [0|3] "" Vector__XXX
   SG_ TrilerCAxleGroupWeightAvailable : 14|2@1+ (1,0) [0|3] "" Vector__XXX
   SG_ TrilerBAxleGroupWeightAvailable : 12|2@1+ (1,0) [0|3] "" Vector__XXX
   SG_ TrilerAAxleGroupWeightAvailable : 10|2@1+ (1,0) [0|3] "" Vector__XXX
   SG_ AddtnlTrctrAxlGrpWightAvailable : 8|2@1+ (1,0) [0|3] "" Vector__XXX
   SG_ TagAxleGroupWeightAvailable : 6|2@1+ (1,0) [0|3] "" Vector__XXX
   SG_ DriveAxleGroupWeightAvailable : 4|2@1+ (1,0) [0|3] "" Vector__XXX
   SG_ LiftAxleGroupWeightAvailable : 2|2@1+ (1,0) [0|3] "" Vector__XXX
   SG_ SteerAxleGroupWeightAvailable : 0|2@1+ (1,0) [0|3] "" Vector__XXX

BO_ 2566739198 DM52: 22 Vector__XXX
   SG_ FlashRedStopLamp : 12|2@1+ (1,0) [0|3] "" Vector__XXX
   SG_ FlashProtectLamp : 8|2@1+ (1,0) [0|3] "" Vector__XXX
   SG_ FlashMalfuncIndicatorLamp : 14|2@1+ (1,0) [0|3] "" Vector__XXX
   SG_ FlashAmberWarningLamp : 10|2@1+ (1,0) [0|3] "" Vector__XXX
   SG_ MalfunctionIndicatorLampStatus : 6|2@1+ (1,0) [0|3] "" Vector__XXX
   SG_ AmberWarningLampStatus : 2|2@1+ (1,0) [0|3] "" Vector__XXX
   SG_ RedStopLampState : 4|2@1+ (1,0) [0|3] "" Vector__XXX
   SG_ ProtectLampStatus : 0|2@1+ (1,0) [0|3] "" Vector__XXX
   SG_ DTC5 : 144|32@1+ (1,0) [0|4.29497e+09] "" Vector__XXX
   SG_ DTC4 : 112|32@1+ (1,0) [0|4.29497e+09] "" Vector__XXX
   SG_ DTC3 : 80|32@1+ (1,0) [0|4.29497e+09] "" Vector__XXX
   SG_ DTC2 : 48|32@1+ (1,0) [0|4.29497e+09] "" Vector__XXX
   SG_ DTC1 : 16|32@1+ (1,0) [0|4.29497e+09] "" Vector__XXX

BO_ 2566739454 DM51: 22 Vector__XXX
   SG_ FlashRedStopLamp : 12|2@1+ (1,0) [0|3] "" Vector__XXX
   SG_ FlashProtectLamp : 8|2@1+ (1,0) [0|3] "" Vector__XXX
   SG_ FlashMalfuncIndicatorLamp : 14|2@1+ (1,0) [0|3] "" Vector__XXX
   SG_ FlashAmberWarningLamp : 10|2@1+ (1,0) [0|3] "" Vector__XXX
   SG_ MalfunctionIndicatorLampStatus : 6|2@1+ (1,0) [0|3] "" Vector__XXX
   SG_ AmberWarningLampStatus : 2|2@1+ (1,0) [0|3] "" Vector__XXX
   SG_ RedStopLampState : 4|2@1+ (1,0) [0|3] "" Vector__XXX
   SG_ ProtectLampStatus : 0|2@1+ (1,0) [0|3] "" Vector__XXX
   SG_ DTC5 : 144|32@1+ (1,0) [0|4.29497e+09] "" Vector__XXX
   SG_ DTC4 : 112|32@1+ (1,0) [0|4.29497e+09] "" Vector__XXX
   SG_ DTC3 : 80|32@1+ (1,0) [0|4.29497e+09] "" Vector__XXX
   SG_ DTC2 : 48|32@1+ (1,0) [0|4.29497e+09] "" Vector__XXX
   SG_ DTC1 : 16|32@1+ (1,0) [0|4.29497e+09] "" Vector__XXX

BO_ 2566739710 DM50: 22 Vector__XXX
   SG_ FlashRedStopLamp : 12|2@1+ (1,0) [0|3] "" Vector__XXX
   SG_ FlashProtectLamp : 8|2@1+ (1,0) [0|3] "" Vector__XXX
   SG_ FlashMalfuncIndicatorLamp : 14|2@1+ (1,0) [0|3] "" Vector__XXX
   SG_ FlashAmberWarningLamp : 10|2@1+ (1,0) [0|3] "" Vector__XXX
   SG_ MalfunctionIndicatorLampStatus : 6|2@1+ (1,0) [0|3] "" Vector__XXX
   SG_ AmberWarningLampStatus : 2|2@1+ (1,0) [0|3] "" Vector__XXX
   SG_ RedStopLampState : 4|2@1+ (1,0) [0|3] "" Vector__XXX
   SG_ ProtectLampStatus : 0|2@1+ (1,0) [0|3] "" Vector__XXX
   SG_ DTC5 : 144|32@1+ (1,0) [0|4.29497e+09] "" Vector__XXX
   SG_ DTC4 : 112|32@1+ (1,0) [0|4.29497e+09] "" Vector__XXX
   SG_ DTC3 : 80|32@1+ (1,0) [0|4.29497e+09] "" Vector__XXX
   SG_ DTC2 : 48|32@1+ (1,0) [0|4.29497e+09] "" Vector__XXX
   SG_ DTC1 : 16|32@1+ (1,0) [0|4.29497e+09] "" Vector__XXX

BO_ 2566739966 DM49: 22 Vector__XXX
   SG_ FlashRedStopLamp : 12|2@1+ (1,0) [0|3] "" Vector__XXX
   SG_ FlashProtectLamp : 8|2@1+ (1,0) [0|3] "" Vector__XXX
   SG_ FlashMalfuncIndicatorLamp : 14|2@1+ (1,0) [0|3] "" Vector__XXX
   SG_ FlashAmberWarningLamp : 10|2@1+ (1,0) [0|3] "" Vector__XXX
   SG_ MalfunctionIndicatorLampStatus : 6|2@1+ (1,0) [0|3] "" Vector__XXX
   SG_ AmberWarningLampStatus : 2|2@1+ (1,0) [0|3] "" Vector__XXX
   SG_ RedStopLampState : 4|2@1+ (1,0) [0|3] "" Vector__XXX
   SG_ ProtectLampStatus : 0|2@1+ (1,0) [0|3] "" Vector__XXX
   SG_ DTC5 : 144|32@1+ (1,0) [0|4.29497e+09] "" Vector__XXX
   SG_ DTC4 : 112|32@1+ (1,0) [0|4.29497e+09] "" Vector__XXX
   SG_ DTC3 : 80|32@1+ (1,0) [0|4.29497e+09] "" Vector__XXX
   SG_ DTC2 : 48|32@1+ (1,0) [0|4.29497e+09] "" Vector__XXX
   SG_ DTC1 : 16|32@1+ (1,0) [0|4.29497e+09] "" Vector__XXX

BO_ 2566740222 DM48: 22 Vector__XXX
   SG_ FlashRedStopLamp : 12|2@1+ (1,0) [0|3] "" Vector__XXX
   SG_ FlashProtectLamp : 8|2@1+ (1,0) [0|3] "" Vector__XXX
   SG_ FlashMalfuncIndicatorLamp : 14|2@1+ (1,0) [0|3] "" Vector__XXX
   SG_ FlashAmberWarningLamp : 10|2@1+ (1,0) [0|3] "" Vector__XXX
   SG_ MalfunctionIndicatorLampStatus : 6|2@1+ (1,0) [0|3] "" Vector__XXX
   SG_ AmberWarningLampStatus : 2|2@1+ (1,0) [0|3] "" Vector__XXX
   SG_ RedStopLampState : 4|2@1+ (1,0) [0|3] "" Vector__XXX
   SG_ ProtectLampStatus : 0|2@1+ (1,0) [0|3] "" Vector__XXX
   SG_ DTC5 : 144|32@1+ (1,0) [0|4.29497e+09] "" Vector__XXX
   SG_ DTC4 : 112|32@1+ (1,0) [0|4.29497e+09] "" Vector__XXX
   SG_ DTC3 : 80|32@1+ (1,0) [0|4.29497e+09] "" Vector__XXX
   SG_ DTC2 : 48|32@1+ (1,0) [0|4.29497e+09] "" Vector__XXX
   SG_ DTC1 : 16|32@1+ (1,0) [0|4.29497e+09] "" Vector__XXX

BO_ 2566740478 DM47: 22 Vector__XXX
   SG_ FlashRedStopLamp : 12|2@1+ (1,0) [0|3] "" Vector__XXX
   SG_ FlashProtectLamp : 8|2@1+ (1,0) [0|3] "" Vector__XXX
   SG_ FlashMalfuncIndicatorLamp : 14|2@1+ (1,0) [0|3] "" Vector__XXX
   SG_ FlashAmberWarningLamp : 10|2@1+ (1,0) [0|3] "" Vector__XXX
   SG_ MalfunctionIndicatorLampStatus : 6|2@1+ (1,0) [0|3] "" Vector__XXX
   SG_ AmberWarningLampStatus : 2|2@1+ (1,0) [0|3] "" Vector__XXX
   SG_ RedStopLampState : 4|2@1+ (1,0) [0|3] "" Vector__XXX
   SG_ ProtectLampStatus : 0|2@1+ (1,0) [0|3] "" Vector__XXX
   SG_ DTC5 : 144|32@1+ (1,0) [0|4.29497e+09] "" Vector__XXX
   SG_ DTC4 : 112|32@1+ (1,0) [0|4.29497e+09] "" Vector__XXX
   SG_ DTC3 : 80|32@1+ (1,0) [0|4.29497e+09] "" Vector__XXX
   SG_ DTC2 : 48|32@1+ (1,0) [0|4.29497e+09] "" Vector__XXX
   SG_ DTC1 : 16|32@1+ (1,0) [0|4.29497e+09] "" Vector__XXX

BO_ 2566740734 DM46: 22 Vector__XXX
   SG_ FlashRedStopLamp : 12|2@1+ (1,0) [0|3] "" Vector__XXX
   SG_ FlashProtectLamp : 8|2@1+ (1,0) [0|3] "" Vector__XXX
   SG_ FlashMalfuncIndicatorLamp : 14|2@1+ (1,0) [0|3] "" Vector__XXX
   SG_ FlashAmberWarningLamp : 10|2@1+ (1,0) [0|3] "" Vector__XXX
   SG_ MalfunctionIndicatorLampStatus : 6|2@1+ (1,0) [0|3] "" Vector__XXX
   SG_ AmberWarningLampStatus : 2|2@1+ (1,0) [0|3] "" Vector__XXX
   SG_ RedStopLampState : 4|2@1+ (1,0) [0|3] "" Vector__XXX
   SG_ ProtectLampStatus : 0|2@1+ (1,0) [0|3] "" Vector__XXX
   SG_ DTC5 : 144|32@1+ (1,0) [0|4.29497e+09] "" Vector__XXX
   SG_ DTC4 : 112|32@1+ (1,0) [0|4.29497e+09] "" Vector__XXX
   SG_ DTC3 : 80|32@1+ (1,0) [0|4.29497e+09] "" Vector__XXX
   SG_ DTC2 : 48|32@1+ (1,0) [0|4.29497e+09] "" Vector__XXX
   SG_ DTC1 : 16|32@1+ (1,0) [0|4.29497e+09] "" Vector__XXX

BO_ 2566740990 DM45: 22 Vector__XXX
   SG_ FlashRedStopLamp : 12|2@1+ (1,0) [0|3] "" Vector__XXX
   SG_ FlashProtectLamp : 8|2@1+ (1,0) [0|3] "" Vector__XXX
   SG_ FlashMalfuncIndicatorLamp : 14|2@1+ (1,0) [0|3] "" Vector__XXX
   SG_ FlashAmberWarningLamp : 10|2@1+ (1,0) [0|3] "" Vector__XXX
   SG_ MalfunctionIndicatorLampStatus : 6|2@1+ (1,0) [0|3] "" Vector__XXX
   SG_ AmberWarningLampStatus : 2|2@1+ (1,0) [0|3] "" Vector__XXX
   SG_ RedStopLampState : 4|2@1+ (1,0) [0|3] "" Vector__XXX
   SG_ ProtectLampStatus : 0|2@1+ (1,0) [0|3] "" Vector__XXX
   SG_ DTC5 : 144|32@1+ (1,0) [0|4.29497e+09] "" Vector__XXX
   SG_ DTC4 : 112|32@1+ (1,0) [0|4.29497e+09] "" Vector__XXX
   SG_ DTC3 : 80|32@1+ (1,0) [0|4.29497e+09] "" Vector__XXX
   SG_ DTC2 : 48|32@1+ (1,0) [0|4.29497e+09] "" Vector__XXX
   SG_ DTC1 : 16|32@1+ (1,0) [0|4.29497e+09] "" Vector__XXX

BO_ 2566741246 DM44: 22 Vector__XXX
   SG_ FlashRedStopLamp : 12|2@1+ (1,0) [0|3] "" Vector__XXX
   SG_ FlashProtectLamp : 8|2@1+ (1,0) [0|3] "" Vector__XXX
   SG_ FlashMalfuncIndicatorLamp : 14|2@1+ (1,0) [0|3] "" Vector__XXX
   SG_ FlashAmberWarningLamp : 10|2@1+ (1,0) [0|3] "" Vector__XXX
   SG_ MalfunctionIndicatorLampStatus : 6|2@1+ (1,0) [0|3] "" Vector__XXX
   SG_ AmberWarningLampStatus : 2|2@1+ (1,0) [0|3] "" Vector__XXX
   SG_ RedStopLampState : 4|2@1+ (1,0) [0|3] "" Vector__XXX
   SG_ ProtectLampStatus : 0|2@1+ (1,0) [0|3] "" Vector__XXX
   SG_ DTC5 : 144|32@1+ (1,0) [0|4.29497e+09] "" Vector__XXX
   SG_ DTC4 : 112|32@1+ (1,0) [0|4.29497e+09] "" Vector__XXX
   SG_ DTC3 : 80|32@1+ (1,0) [0|4.29497e+09] "" Vector__XXX
   SG_ DTC2 : 48|32@1+ (1,0) [0|4.29497e+09] "" Vector__XXX
   SG_ DTC1 : 16|32@1+ (1,0) [0|4.29497e+09] "" Vector__XXX

BO_ 2566741502 DM43: 22 Vector__XXX
   SG_ FlashRedStopLamp : 12|2@1+ (1,0) [0|3] "" Vector__XXX
   SG_ FlashProtectLamp : 8|2@1+ (1,0) [0|3] "" Vector__XXX
   SG_ FlashMalfuncIndicatorLamp : 14|2@1+ (1,0) [0|3] "" Vector__XXX
   SG_ FlashAmberWarningLamp : 10|2@1+ (1,0) [0|3] "" Vector__XXX
   SG_ MalfunctionIndicatorLampStatus : 6|2@1+ (1,0) [0|3] "" Vector__XXX
   SG_ AmberWarningLampStatus : 2|2@1+ (1,0) [0|3] "" Vector__XXX
   SG_ RedStopLampState : 4|2@1+ (1,0) [0|3] "" Vector__XXX
   SG_ ProtectLampStatus : 0|2@1+ (1,0) [0|3] "" Vector__XXX
   SG_ DTC5 : 144|32@1+ (1,0) [0|4.29497e+09] "" Vector__XXX
   SG_ DTC4 : 112|32@1+ (1,0) [0|4.29497e+09] "" Vector__XXX
   SG_ DTC3 : 80|32@1+ (1,0) [0|4.29497e+09] "" Vector__XXX
   SG_ DTC2 : 48|32@1+ (1,0) [0|4.29497e+09] "" Vector__XXX
   SG_ DTC1 : 16|32@1+ (1,0) [0|4.29497e+09] "" Vector__XXX

BO_ 2566741758 DM42: 22 Vector__XXX
   SG_ FlashRedStopLamp : 12|2@1+ (1,0) [0|3] "" Vector__XXX
   SG_ FlashProtectLamp : 8|2@1+ (1,0) [0|3] "" Vector__XXX
   SG_ FlashMalfuncIndicatorLamp : 14|2@1+ (1,0) [0|3] "" Vector__XXX
   SG_ FlashAmberWarningLamp : 10|2@1+ (1,0) [0|3] "" Vector__XXX
   SG_ MalfunctionIndicatorLampStatus : 6|2@1+ (1,0) [0|3] "" Vector__XXX
   SG_ AmberWarningLampStatus : 2|2@1+ (1,0) [0|3] "" Vector__XXX
   SG_ RedStopLampState : 4|2@1+ (1,0) [0|3] "" Vector__XXX
   SG_ ProtectLampStatus : 0|2@1+ (1,0) [0|3] "" Vector__XXX
   SG_ DTC5 : 144|32@1+ (1,0) [0|4.29497e+09] "" Vector__XXX
   SG_ DTC4 : 112|32@1+ (1,0) [0|4.29497e+09] "" Vector__XXX
   SG_ DTC3 : 80|32@1+ (1,0) [0|4.29497e+09] "" Vector__XXX
   SG_ DTC2 : 48|32@1+ (1,0) [0|4.29497e+09] "" Vector__XXX
   SG_ DTC1 : 16|32@1+ (1,0) [0|4.29497e+09] "" Vector__XXX

BO_ 2566742014 DM41: 22 Vector__XXX
   SG_ FlashRedStopLamp : 12|2@1+ (1,0) [0|3] "" Vector__XXX
   SG_ FlashProtectLamp : 8|2@1+ (1,0) [0|3] "" Vector__XXX
   SG_ FlashMalfuncIndicatorLamp : 14|2@1+ (1,0) [0|3] "" Vector__XXX
   SG_ FlashAmberWarningLamp : 10|2@1+ (1,0) [0|3] "" Vector__XXX
   SG_ MalfunctionIndicatorLampStatus : 6|2@1+ (1,0) [0|3] "" Vector__XXX
   SG_ AmberWarningLampStatus : 2|2@1+ (1,0) [0|3] "" Vector__XXX
   SG_ RedStopLampState : 4|2@1+ (1,0) [0|3] "" Vector__XXX
   SG_ ProtectLampStatus : 0|2@1+ (1,0) [0|3] "" Vector__XXX
   SG_ DTC5 : 144|32@1+ (1,0) [0|4.29497e+09] "" Vector__XXX
   SG_ DTC4 : 112|32@1+ (1,0) [0|4.29497e+09] "" Vector__XXX
   SG_ DTC3 : 80|32@1+ (1,0) [0|4.29497e+09] "" Vector__XXX
   SG_ DTC2 : 48|32@1+ (1,0) [0|4.29497e+09] "" Vector__XXX
   SG_ DTC1 : 16|32@1+ (1,0) [0|4.29497e+09] "" Vector__XXX

BO_ 2560622334 DM35: 22 Vector__XXX
   SG_ FlashRedStopLamp : 12|2@1+ (1,0) [0|3] "" Vector__XXX
   SG_ FlashProtectLamp : 8|2@1+ (1,0) [0|3] "" Vector__XXX
   SG_ FlashMalfuncIndicatorLamp : 14|2@1+ (1,0) [0|3] "" Vector__XXX
   SG_ FlashAmberWarningLamp : 10|2@1+ (1,0) [0|3] "" Vector__XXX
   SG_ MalfunctionIndicatorLampStatus : 6|2@1+ (1,0) [0|3] "" Vector__XXX
   SG_ AmberWarningLampStatus : 2|2@1+ (1,0) [0|3] "" Vector__XXX
   SG_ RedStopLampState : 4|2@1+ (1,0) [0|3] "" Vector__XXX
   SG_ ProtectLampStatus : 0|2@1+ (1,0) [0|3] "" Vector__XXX
   SG_ DTC5 : 144|32@1+ (1,0) [0|4.29497e+09] "" Vector__XXX
   SG_ DTC4 : 112|32@1+ (1,0) [0|4.29497e+09] "" Vector__XXX
   SG_ DTC3 : 80|32@1+ (1,0) [0|4.29497e+09] "" Vector__XXX
   SG_ DTC2 : 48|32@1+ (1,0) [0|4.29497e+09] "" Vector__XXX
   SG_ DTC1 : 16|32@1+ (1,0) [0|4.29497e+09] "" Vector__XXX

BO_ 2566744062 ZNVW: 8 Vector__XXX
   SG_ ZeroNetVehicleWeightChange : 0|2@1+ (1,0) [0|3] "" Vector__XXX

BO_ 2499630078 EAI: 8 Vector__XXX
   SG_ EngExhaustGasTempAverageBank2 : 32|16@1+ (0.03125,-273) [-273|1734.97] "deg C" Vector__XXX
   SG_ EngExhaustGasTempAverageBank1 : 16|16@1+ (0.03125,-273) [-273|1734.97] "deg C" Vector__XXX
   SG_ EngExhaustGasTempAverage : 0|16@1+ (0.03125,-273) [-273|1734.97] "deg C" Vector__XXX

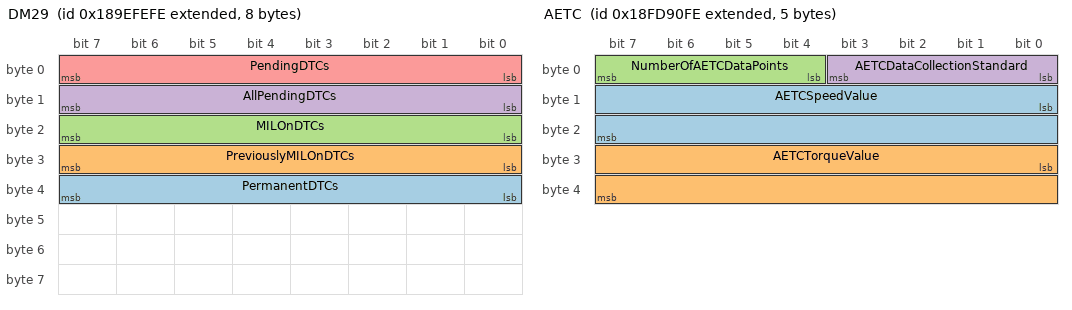
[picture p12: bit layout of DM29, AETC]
BO_ 2560556798 DM29: 8 Vector__XXX
   SG_ PermanentDTCs : 32|8@1+ (1,0) [0|255] "" Vector__XXX
   SG_ PreviouslyMILOnDTCs : 24|8@1+ (1,0) [0|255] "" Vector__XXX
   SG_ MILOnDTCs : 16|8@1+ (1,0) [0|255] "" Vector__XXX
   SG_ AllPendingDTCs : 8|8@1+ (1,0) [0|255] "" Vector__XXX
   SG_ PendingDTCs : 0|8@1+ (1,0) [0|255] "" Vector__XXX

BO_ 2566750462 DM28: 22 Vector__XXX
   SG_ FlashRedStopLamp : 12|2@1+ (1,0) [0|3] "" Vector__XXX
   SG_ FlashProtectLamp : 8|2@1+ (1,0) [0|3] "" Vector__XXX
   SG_ FlashMalfuncIndicatorLamp : 14|2@1+ (1,0) [0|3] "" Vector__XXX
   SG_ FlashAmberWarningLamp : 10|2@1+ (1,0) [0|3] "" Vector__XXX
   SG_ MalfunctionIndicatorLampStatus : 6|2@1+ (1,0) [0|3] "" Vector__XXX
   SG_ AmberWarningLampStatus : 2|2@1+ (1,0) [0|3] "" Vector__XXX
   SG_ RedStopLampState : 4|2@1+ (1,0) [0|3] "" Vector__XXX
   SG_ ProtectLampStatus : 0|2@1+ (1,0) [0|3] "" Vector__XXX
   SG_ DTC5 : 144|32@1+ (1,0) [0|4.29497e+09] "" Vector__XXX
   SG_ DTC4 : 112|32@1+ (1,0) [0|4.29497e+09] "" Vector__XXX
   SG_ DTC3 : 80|32@1+ (1,0) [0|4.29497e+09] "" Vector__XXX
   SG_ DTC2 : 48|32@1+ (1,0) [0|4.29497e+09] "" Vector__XXX
   SG_ DTC1 : 16|32@1+ (1,0) [0|4.29497e+09] "" Vector__XXX

BO_ 2566750974 DM27: 22 Vector__XXX
   SG_ FlashRedStopLamp : 12|2@1+ (1,0) [0|3] "" Vector__XXX
   SG_ FlashProtectLamp : 8|2@1+ (1,0) [0|3] "" Vector__XXX
   SG_ FlashMalfuncIndicatorLamp : 14|2@1+ (1,0) [0|3] "" Vector__XXX
   SG_ FlashAmberWarningLamp : 10|2@1+ (1,0) [0|3] "" Vector__XXX
   SG_ MalfunctionIndicatorLampStatus : 6|2@1+ (1,0) [0|3] "" Vector__XXX
   SG_ AmberWarningLampStatus : 2|2@1+ (1,0) [0|3] "" Vector__XXX
   SG_ RedStopLampState : 4|2@1+ (1,0) [0|3] "" Vector__XXX
   SG_ ProtectLampStatus : 0|2@1+ (1,0) [0|3] "" Vector__XXX
   SG_ DTC5 : 144|32@1+ (1,0) [0|4.29497e+09] "" Vector__XXX
   SG_ DTC4 : 112|32@1+ (1,0) [0|4.29497e+09] "" Vector__XXX
   SG_ DTC3 : 80|32@1+ (1,0) [0|4.29497e+09] "" Vector__XXX
   SG_ DTC2 : 48|32@1+ (1,0) [0|4.29497e+09] "" Vector__XXX
   SG_ DTC1 : 16|32@1+ (1,0) [0|4.29497e+09] "" Vector__XXX

BO_ 2566754558 AETC: 5 Vector__XXX
   SG_ AETCSpeedValue : 8|16@1- (1,0) [0|8031.88] "rpm" Vector__XXX
   SG_ AETCTorqueValue : 24|16@1+ (1,0) [0|64255] "Nm" Vector__XXX
   SG_ NumberOfAETCDataPoints : 4|4@1+ (1,0) [0|15] "" Vector__XXX
   SG_ AETCDataCollectionStandard : 0|4@1+ (1,0) [0|15] "" Vector__XXX

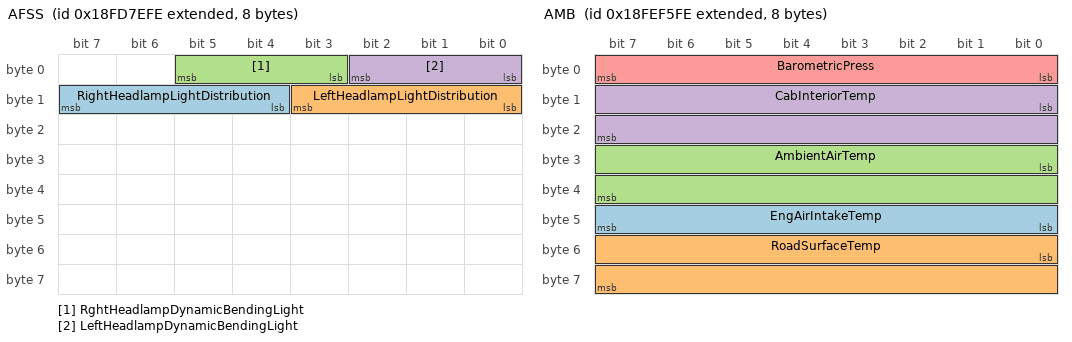
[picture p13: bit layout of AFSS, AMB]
BO_ 2566749950 AFSS: 8 Vector__XXX
   SG_ RightHeadlampLightDistribution : 12|4@1+ (1,0) [0|15] "" Vector__XXX
   SG_ LeftHeadlampLightDistribution : 8|4@1+ (1,0) [0|15] "" Vector__XXX
   SG_ RghtHeadlampDynamicBendingLight : 3|3@1+ (1,0) [0|7] "" Vector__XXX
   SG_ LeftHeadlampDynamicBendingLight : 0|3@1+ (1,0) [0|7] "" Vector__XXX

BO_ 2566838782 AUXIO1: 8 Vector__XXX
   SG_ AuxI_O16 : 24|2@1+ (1,0) [0|3] "" Vector__XXX
   SG_ AuxI_O15 : 26|2@1+ (1,0) [0|3] "" Vector__XXX
   SG_ AuxI_O14 : 28|2@1+ (1,0) [0|3] "" Vector__XXX
   SG_ AuxI_O13 : 30|2@1+ (1,0) [0|3] "" Vector__XXX
   SG_ AuxI_O12 : 16|2@1+ (1,0) [0|3] "" Vector__XXX
   SG_ AuxI_O11 : 18|2@1+ (1,0) [0|3] "" Vector__XXX
   SG_ AuxI_O10 : 20|2@1+ (1,0) [0|3] "" Vector__XXX
   SG_ AuxI_O09 : 22|2@1+ (1,0) [0|3] "" Vector__XXX
   SG_ AuxI_O08 : 8|2@1+ (1,0) [0|3] "" Vector__XXX
   SG_ AuxI_O07 : 10|2@1+ (1,0) [0|3] "" Vector__XXX
   SG_ AuxI_O06 : 12|2@1+ (1,0) [0|3] "" Vector__XXX
   SG_ AuxI_O05 : 14|2@1+ (1,0) [0|3] "" Vector__XXX
   SG_ AuxI_O04 : 0|2@1+ (1,0) [0|3] "" Vector__XXX
   SG_ AuxI_O03 : 2|2@1+ (1,0) [0|3] "" Vector__XXX
   SG_ AuxI_O02 : 4|2@1+ (1,0) [0|3] "" Vector__XXX
   SG_ AuxI_O01 : 6|2@1+ (1,0) [0|3] "" Vector__XXX
   SG_ AuxI_OChannel2 : 48|16@1+ (1,0) [0|64255] "counts" Vector__XXX
   SG_ AuxI_OChannel1 : 32|16@1+ (1,0) [0|64255] "counts" Vector__XXX

BO_ 2561146622 AUXIO2: 8 Vector__XXX
   SG_ AuxI_O45 : 62|2@1+ (1,0) [0|3] "" Vector__XXX
   SG_ AuxI_O46 : 60|2@1+ (1,0) [0|3] "" Vector__XXX
   SG_ AuxI_O47 : 58|2@1+ (1,0) [0|3] "" Vector__XXX
   SG_ AuxI_O48 : 56|2@1+ (1,0) [0|3] "" Vector__XXX
   SG_ AuxI_O41 : 54|2@1+ (1,0) [0|3] "" Vector__XXX
   SG_ AuxI_O42 : 52|2@1+ (1,0) [0|3] "" Vector__XXX
   SG_ AuxI_O43 : 50|2@1+ (1,0) [0|3] "" Vector__XXX
   SG_ AuxI_O44 : 48|2@1+ (1,0) [0|3] "" Vector__XXX
   SG_ AuxI_O37 : 46|2@1+ (1,0) [0|3] "" Vector__XXX
   SG_ AuxI_O38 : 44|2@1+ (1,0) [0|3] "" Vector__XXX
   SG_ AuxI_O39 : 42|2@1+ (1,0) [0|3] "" Vector__XXX
   SG_ AuxI_O40 : 40|2@1+ (1,0) [0|3] "" Vector__XXX
   SG_ AuxI_O33 : 38|2@1+ (1,0) [0|3] "" Vector__XXX
   SG_ AuxI_O34 : 36|2@1+ (1,0) [0|3] "" Vector__XXX
   SG_ AuxI_O35 : 34|2@1+ (1,0) [0|3] "" Vector__XXX
   SG_ AuxI_O36 : 32|2@1+ (1,0) [0|3] "" Vector__XXX
   SG_ AuxI_O29 : 30|2@1+ (1,0) [0|3] "" Vector__XXX
   SG_ AuxI_O30 : 28|2@1+ (1,0) [0|3] "" Vector__XXX
   SG_ AuxI_O31 : 26|2@1+ (1,0) [0|3] "" Vector__XXX
   SG_ AuxI_O32 : 24|2@1+ (1,0) [0|3] "" Vector__XXX
   SG_ AuxI_O25 : 22|2@1+ (1,0) [0|3] "" Vector__XXX
   SG_ AuxI_O26 : 20|2@1+ (1,0) [0|3] "" Vector__XXX
   SG_ AuxI_O27 : 18|2@1+ (1,0) [0|3] "" Vector__XXX
   SG_ AuxI_O28 : 16|2@1+ (1,0) [0|3] "" Vector__XXX
   SG_ AuxI_O21 : 14|2@1+ (1,0) [0|3] "" Vector__XXX
   SG_ AuxI_O22 : 12|2@1+ (1,0) [0|3] "" Vector__XXX
   SG_ AuxI_O23 : 10|2@1+ (1,0) [0|3] "" Vector__XXX
   SG_ AuxI_O24 : 8|2@1+ (1,0) [0|3] "" Vector__XXX
   SG_ AuxI_O17 : 6|2@1+ (1,0) [0|3] "" Vector__XXX
   SG_ AuxI_O18 : 4|2@1+ (1,0) [0|3] "" Vector__XXX
   SG_ AuxI_O19 : 2|2@1+ (1,0) [0|3] "" Vector__XXX
   SG_ AuxI_O20 : 0|2@1+ (1,0) [0|3] "" Vector__XXX

BO_ 2561081086 AUXIO3: 8 Vector__XXX
   SG_ AuxI_O77 : 62|2@1+ (1,0) [0|3] "" Vector__XXX
   SG_ AuxI_O78 : 60|2@1+ (1,0) [0|3] "" Vector__XXX
   SG_ AuxI_O79 : 58|2@1+ (1,0) [0|3] "" Vector__XXX
   SG_ AuxI_O80 : 56|2@1+ (1,0) [0|3] "" Vector__XXX
   SG_ AuxI_O73 : 54|2@1+ (1,0) [0|3] "" Vector__XXX
   SG_ AuxI_O74 : 52|2@1+ (1,0) [0|3] "" Vector__XXX
   SG_ AuxI_O75 : 50|2@1+ (1,0) [0|3] "" Vector__XXX
   SG_ AuxI_O76 : 48|2@1+ (1,0) [0|3] "" Vector__XXX
   SG_ AuxI_O69 : 46|2@1+ (1,0) [0|3] "" Vector__XXX
   SG_ AuxI_O70 : 44|2@1+ (1,0) [0|3] "" Vector__XXX
   SG_ AuxI_O71 : 42|2@1+ (1,0) [0|3] "" Vector__XXX
   SG_ AuxI_O72 : 40|2@1+ (1,0) [0|3] "" Vector__XXX
   SG_ AuxI_O65 : 38|2@1+ (1,0) [0|3] "" Vector__XXX
   SG_ AuxI_O66 : 36|2@1+ (1,0) [0|3] "" Vector__XXX
   SG_ AuxI_O67 : 34|2@1+ (1,0) [0|3] "" Vector__XXX
   SG_ AuxI_O68 : 32|2@1+ (1,0) [0|3] "" Vector__XXX
   SG_ AuxI_O61 : 30|2@1+ (1,0) [0|3] "" Vector__XXX
   SG_ AuxI_O62 : 28|2@1+ (1,0) [0|3] "" Vector__XXX
   SG_ AuxI_O63 : 26|2@1+ (1,0) [0|3] "" Vector__XXX
   SG_ AuxI_O64 : 24|2@1+ (1,0) [0|3] "" Vector__XXX
   SG_ AuxI_O57 : 22|2@1+ (1,0) [0|3] "" Vector__XXX
   SG_ AuxI_O58 : 20|2@1+ (1,0) [0|3] "" Vector__XXX
   SG_ AuxI_O59 : 18|2@1+ (1,0) [0|3] "" Vector__XXX
   SG_ AuxI_O60 : 16|2@1+ (1,0) [0|3] "" Vector__XXX
   SG_ AuxI_O53 : 14|2@1+ (1,0) [0|3] "" Vector__XXX
   SG_ AuxI_O54 : 12|2@1+ (1,0) [0|3] "" Vector__XXX
   SG_ AuxI_O55 : 10|2@1+ (1,0) [0|3] "" Vector__XXX
   SG_ AuxI_O56 : 8|2@1+ (1,0) [0|3] "" Vector__XXX
   SG_ AuxI_O49 : 6|2@1+ (1,0) [0|3] "" Vector__XXX
   SG_ AuxI_O50 : 4|2@1+ (1,0) [0|3] "" Vector__XXX
   SG_ AuxI_O51 : 2|2@1+ (1,0) [0|3] "" Vector__XXX
   SG_ AuxI_O52 : 0|2@1+ (1,0) [0|3] "" Vector__XXX

BO_ 2561015550 AUXIO4: 8 Vector__XXX
   SG_ AuxI_O92 : 16|2@1+ (1,0) [0|3] "" Vector__XXX
   SG_ AuxI_O85 : 14|2@1+ (1,0) [0|3] "" Vector__XXX
   SG_ AuxI_O86 : 12|2@1+ (1,0) [0|3] "" Vector__XXX
   SG_ AuxI_O87 : 10|2@1+ (1,0) [0|3] "" Vector__XXX
   SG_ AuxI_O88 : 8|2@1+ (1,0) [0|3] "" Vector__XXX
   SG_ AuxI_O81 : 6|2@1+ (1,0) [0|3] "" Vector__XXX
   SG_ AuxI_O82 : 4|2@1+ (1,0) [0|3] "" Vector__XXX
   SG_ AuxI_O83 : 2|2@1+ (1,0) [0|3] "" Vector__XXX
   SG_ AuxI_O84 : 0|2@1+ (1,0) [0|3] "" Vector__XXX
   SG_ AuxI_O109 : 62|2@1+ (1,0) [0|3] "" Vector__XXX
   SG_ AuxI_O110 : 60|2@1+ (1,0) [0|3] "" Vector__XXX
   SG_ AuxI_O111 : 58|2@1+ (1,0) [0|3] "" Vector__XXX
   SG_ AuxI_O112 : 56|2@1+ (1,0) [0|3] "" Vector__XXX
   SG_ AuxI_O105 : 54|2@1+ (1,0) [0|3] "" Vector__XXX
   SG_ AuxI_O106 : 52|2@1+ (1,0) [0|3] "" Vector__XXX
   SG_ AuxI_O107 : 50|2@1+ (1,0) [0|3] "" Vector__XXX
   SG_ AuxI_O108 : 48|2@1+ (1,0) [0|3] "" Vector__XXX
   SG_ AuxI_O101 : 46|2@1+ (1,0) [0|3] "" Vector__XXX
   SG_ AuxI_O102 : 44|2@1+ (1,0) [0|3] "" Vector__XXX
   SG_ AuxI_O103 : 42|2@1+ (1,0) [0|3] "" Vector__XXX
   SG_ AuxI_O104 : 40|2@1+ (1,0) [0|3] "" Vector__XXX
   SG_ AuxI_O97 : 38|2@1+ (1,0) [0|3] "" Vector__XXX
   SG_ AuxI_O98 : 36|2@1+ (1,0) [0|3] "" Vector__XXX
   SG_ AuxI_O99 : 34|2@1+ (1,0) [0|3] "" Vector__XXX
   SG_ AuxI_O100 : 32|2@1+ (1,0) [0|3] "" Vector__XXX
   SG_ AuxI_O93 : 30|2@1+ (1,0) [0|3] "" Vector__XXX
   SG_ AuxI_O94 : 28|2@1+ (1,0) [0|3] "" Vector__XXX
   SG_ AuxI_O95 : 26|2@1+ (1,0) [0|3] "" Vector__XXX
   SG_ AuxI_O96 : 24|2@1+ (1,0) [0|3] "" Vector__XXX
   SG_ AuxI_O89 : 22|2@1+ (1,0) [0|3] "" Vector__XXX
   SG_ AuxI_O90 : 20|2@1+ (1,0) [0|3] "" Vector__XXX
   SG_ AuxI_O91 : 18|2@1+ (1,0) [0|3] "" Vector__XXX

BO_ 2566746622 BSA: 8 Vector__XXX
   SG_ TrailerBrakeStrokeAxle5Right : 57|3@1+ (1,0) [0|7] "" Vector__XXX
   SG_ TrailerBrakeStrokeAxle5Left : 54|3@1+ (1,0) [0|7] "" Vector__XXX
   SG_ TrailerBrakeStrokeAxle4Right : 51|3@1+ (1,0) [0|7] "" Vector__XXX
   SG_ TrailerBrakeStrokeAxle4Left : 48|3@1+ (1,0) [0|7] "" Vector__XXX
   SG_ TrailerBrakeStrokeAxle3Right : 45|3@1+ (1,0) [0|7] "" Vector__XXX
   SG_ TrailerBrakeStrokeAxle3Left : 42|3@1+ (1,0) [0|7] "" Vector__XXX
   SG_ TrailerBrakeStrokeAxle2Right : 39|3@1+ (1,0) [0|7] "" Vector__XXX
   SG_ TrailerBrakeStrokeAxle2Left : 36|3@1+ (1,0) [0|7] "" Vector__XXX
   SG_ TrailerBrakeStrokeAxle1Right : 33|3@1+ (1,0) [0|7] "" Vector__XXX
   SG_ TrailerBrakeStrokeAxle1Left : 30|3@1+ (1,0) [0|7] "" Vector__XXX
   SG_ TractorBrakeStrokeAxle5Right : 27|3@1+ (1,0) [0|7] "" Vector__XXX
   SG_ TractorBrakeStrokeAxle5Left : 24|3@1+ (1,0) [0|7] "" Vector__XXX
   SG_ TractorBrakeStrokeAxle4Right : 21|3@1+ (1,0) [0|7] "" Vector__XXX
   SG_ TractorBrakeStrokeAxle4Left : 18|3@1+ (1,0) [0|7] "" Vector__XXX
   SG_ TractorBrakeStrokeAxle3Right : 15|3@1+ (1,0) [0|7] "" Vector__XXX
   SG_ TractorBrakeStrokeAxle3Left : 12|3@1+ (1,0) [0|7] "" Vector__XXX
   SG_ TractorBrakeStrokeAxle2Right : 9|3@1+ (1,0) [0|7] "" Vector__XXX
   SG_ TractorBrakeStrokeAxle2Left : 6|3@1+ (1,0) [0|7] "" Vector__XXX
   SG_ TractorBrakeStrokeAxle1Right : 3|3@1+ (1,0) [0|7] "" Vector__XXX
   SG_ TractorBrakeStrokeAxle1Left : 0|3@1+ (1,0) [0|7] "" Vector__XXX

BO_ 2566845950 AMB: 8 Vector__XXX
   SG_ EngAirIntakeTemp : 40|8@1+ (1,-40) [-40|210] "deg C" Vector__XXX
   SG_ RoadSurfaceTemp : 48|16@1+ (0.03125,-273) [-273|1734.97] "deg C" Vector__XXX
   SG_ AmbientAirTemp : 24|16@1+ (0.03125,-273) [-273|1734.97] "deg C" Vector__XXX
   SG_ CabInteriorTemp : 8|16@1+ (0.03125,-273) [-273|1734.97] "deg C" Vector__XXX
   SG_ BarometricPress : 0|8@1+ (0.5,0) [0|125] "kPa" Vector__XXX

BO_ 2566840062 AIR2: 8 Vector__XXX
   SG_ EngAirStartPress : 0|8@1+ (4,0) [0|1000] "kPa" Vector__XXX

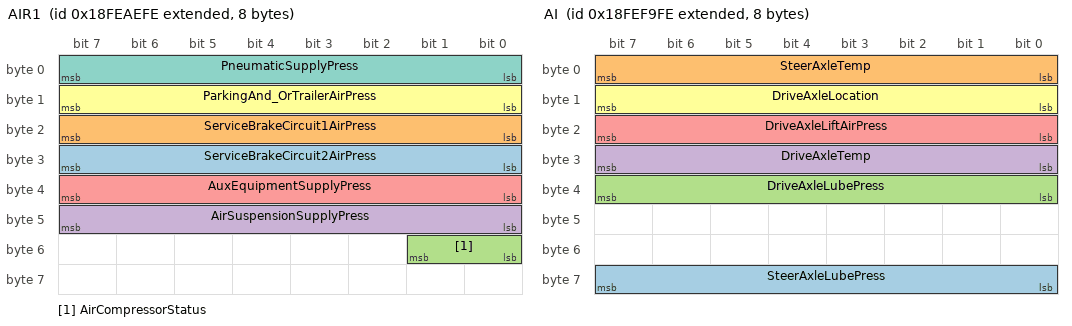
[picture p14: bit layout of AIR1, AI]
BO_ 2566827774 AIR1: 8 Vector__XXX
   SG_ ServiceBrakeCircuit2AirPress : 24|8@1+ (8,0) [0|2000] "kPa" Vector__XXX
   SG_ ServiceBrakeCircuit1AirPress : 16|8@1+ (8,0) [0|2000] "kPa" Vector__XXX
   SG_ AirCompressorStatus : 48|2@1+ (1,0) [0|3] "" Vector__XXX
   SG_ AirSuspensionSupplyPress : 40|8@1+ (8,0) [0|2000] "kPa" Vector__XXX
   SG_ AuxEquipmentSupplyPress : 32|8@1+ (8,0) [0|2000] "kPa" Vector__XXX
   SG_ ParkingAnd_OrTrailerAirPress : 8|8@1+ (8,0) [0|2000] "kPa" Vector__XXX
   SG_ PneumaticSupplyPress : 0|8@1+ (8,0) [0|2000] "kPa" Vector__XXX

BO_ 2566846974 AI: 8 Vector__XXX
   SG_ SteerAxleLubePress : 56|8@1+ (4,0) [0|1000] "kPa" Vector__XXX
   SG_ SteerAxleTemp : 0|8@1+ (1,-40) [-40|210] "deg C" Vector__XXX
   SG_ DriveAxleLubePress : 32|8@1+ (4,0) [0|1000] "kPa" Vector__XXX
   SG_ DriveAxleTemp : 24|8@1+ (1,-40) [-40|210] "deg C" Vector__XXX
   SG_ DriveAxleLiftAirPress : 16|8@1+ (4,0) [0|1000] "kPa" Vector__XXX
   SG_ DriveAxleLocation : 8|8@1+ (1,0) [0|255] "" Vector__XXX

BO_ 2633935614 AF2: 8 Vector__XXX
   SG_ EngTurboWastegateValvePos : 24|8@1+ (0.4,0) [0|100] "%" Vector__XXX
   SG_ EngGsMssFlwSnsrFelingCorrection : 32|8@1+ (1,-125) [-125|125] "%" Vector__XXX
   SG_ EngDsiredAbsIntakeManifoldPress : 8|16@1+ (0.1,0) [0|6425.5] "kPa" Vector__XXX
   SG_ EngGasFuelCorrectionFactor : 0|8@1+ (1,0) [0|250] "%" Vector__XXX

BO_ 2566803966 ACC2: 8 Vector__XXX
   SG_ ACCUsageDemand : 0|2@1+ (1,0) [0|3] "" Vector__XXX
   SG_ RqedACCDistanceMode : 5|3@1+ (1,0) [0|7] "" Vector__XXX

BO_ 2432593918 ACC1: 8 Vector__XXX
   SG_ ForwardCollisionWarning : 54|2@1+ (1,0) [0|3] "" Vector__XXX
   SG_ ACCDistanceAlertSignal : 52|2@1+ (1,0) [0|3] "" Vector__XXX
   SG_ ACCSystemShutoffWarning : 50|2@1+ (1,0) [0|3] "" Vector__XXX
   SG_ ACCTargetDetected : 48|2@1+ (1,0) [0|3] "" Vector__XXX
   SG_ RoadCurvature : 32|16@1+ (0.0078125,-250) [-250|251.992] "1/km" Vector__XXX
   SG_ AdptveCruiseCtrlSetDistanceMode : 27|3@1+ (1,0) [0|7] "" Vector__XXX
   SG_ AdaptiveCruiseCtrlMode : 24|3@1+ (1,0) [0|7] "" Vector__XXX
   SG_ AdaptiveCruiseCtrlSetSpeed : 16|8@1+ (1,0) [0|250] "km/h" Vector__XXX
   SG_ DistanceToForwardVehicle : 8|8@1+ (1,0) [0|250] "m" Vector__XXX
   SG_ SpeedOfForwardVehicle : 0|8@1+ (1,0) [0|250] "km/h" Vector__XXX

BO_ 2633935102 AC: 8 Vector__XXX
   SG_ ArticulationAngle : 0|8@1+ (1,-125) [-125|125] "deg" Vector__XXX

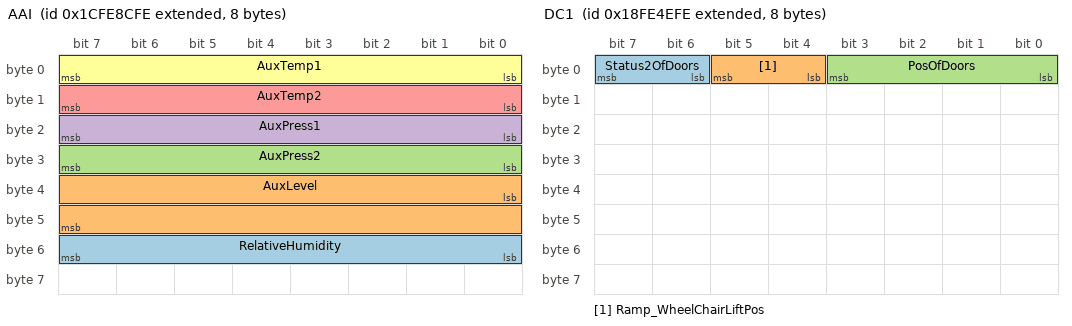
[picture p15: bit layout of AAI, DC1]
BO_ 2633927934 AAI: 8 Vector__XXX
   SG_ RelativeHumidity : 48|8@1+ (0.4,0) [0|100] "%" Vector__XXX
   SG_ AuxLevel : 32|16@1+ (0.1,0) [0|6425.5] "mm" Vector__XXX
   SG_ AuxPress2 : 24|8@1+ (16,0) [0|4000] "kPa" Vector__XXX
   SG_ AuxPress1 : 16|8@1+ (16,0) [0|4000] "kPa" Vector__XXX
   SG_ AuxTemp2 : 8|8@1+ (1,-40) [-40|210] "deg C" Vector__XXX
   SG_ AuxTemp1 : 0|8@1+ (1,-40) [-40|210] "deg C" Vector__XXX

BO_ 2566847998 A1: 8 Vector__XXX
   SG_ EngBlowerBypassValvePos : 0|8@1+ (0.4,0) [0|100] "%" Vector__XXX
   SG_ EngGasSupplyPress : 8|16@1+ (0.5,0) [0|32127.5] "kPa" Vector__XXX

BO_ 2565406462 ACKM: 8 Vector__XXX
   SG_ AddressBusy m3 : 32|8@1+ (1,0) [0|255] "" Vector__XXX
   SG_ ControlByte M : 0|8@1+ (1,0) [0|255] "" Vector__XXX
   SG_ ParameterGroupNumber : 40|24@1+ (1,0) [0|1.67772e+07] "" Vector__XXX
   SG_ GroupFunctionValue : 8|8@1+ (1,0) [0|255] "" Vector__XXX
   SG_ AddressAccessDenied m2 : 32|8@1+ (1,0) [0|255] "" Vector__XXX
   SG_ AddressNegativeAcknowledgement m1 : 32|8@1+ (1,0) [0|255] "" Vector__XXX
   SG_ AddressAcknowledged m0 : 32|8@1+ (1,0) [0|255] "" Vector__XXX

BO_ 2566803198 DC1: 8 Vector__XXX
   SG_ Status2OfDoors : 6|2@1+ (1,0) [0|3] "" Vector__XXX
   SG_ Ramp_WheelChairLiftPos : 4|2@1+ (1,0) [0|3] "" Vector__XXX
   SG_ PosOfDoors : 0|4@1+ (1,0) [0|15] "" Vector__XXX

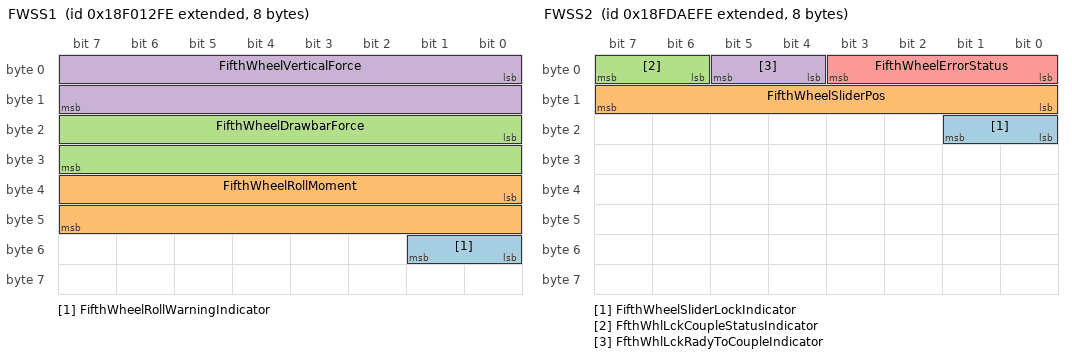
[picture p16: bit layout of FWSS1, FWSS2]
BO_ 2565870334 FWSS1: 8 Vector__XXX
   SG_ FifthWheelRollWarningIndicator : 48|2@1+ (1,0) [0|3] "" Vector__XXX
   SG_ FifthWheelRollMoment : 32|16@1+ (10,-320000) [-320000|322550] "N" Vector__XXX
   SG_ FifthWheelDrawbarForce : 16|16@1+ (10,-320000) [-320000|322550] "N" Vector__XXX
   SG_ FifthWheelVerticalForce : 0|16@1+ (5,0) [0|321275] "N" Vector__XXX

BO_ 2566762238 FWSS2: 8 Vector__XXX
   SG_ FifthWheelSliderLockIndicator : 16|2@1+ (1,0) [0|3] "" Vector__XXX
   SG_ FifthWheelSliderPos : 8|8@1+ (10,0) [0|2500] "mm" Vector__XXX
   SG_ FfthWhlLckCoupleStatusIndicator : 6|2@1+ (1,0) [0|3] "" Vector__XXX
   SG_ FfthWhlLckRadyToCoupleIndicator : 4|2@1+ (1,0) [0|3] "" Vector__XXX
   SG_ FifthWheelErrorStatus : 0|4@1+ (1,0) [0|15] "" Vector__XXX

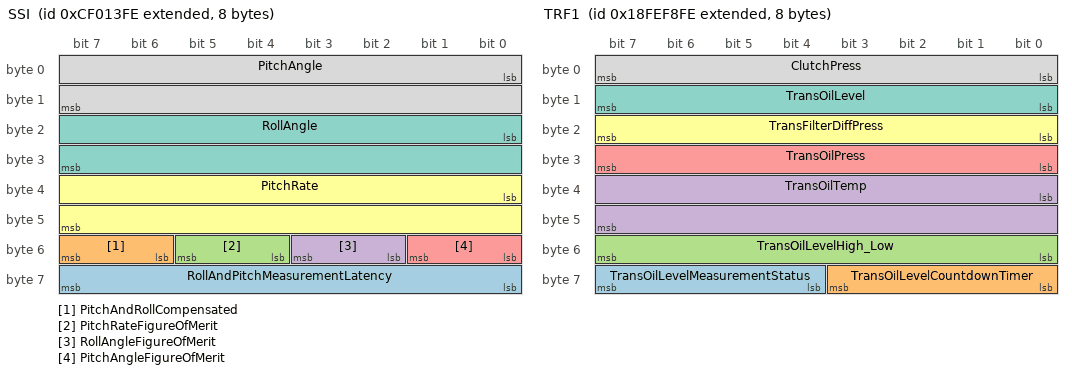
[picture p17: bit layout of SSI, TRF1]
BO_ 2364543998 SSI: 8 Vector__XXX
   SG_ RollAndPitchMeasurementLatency : 56|8@1+ (0.5,0) [0|125] "ms" Vector__XXX
   SG_ PitchAndRollCompensated : 54|2@1+ (1,0) [0|3] "" Vector__XXX
   SG_ PitchRateFigureOfMerit : 52|2@1+ (1,0) [0|3] "" Vector__XXX
   SG_ RollAngleFigureOfMerit : 50|2@1+ (1,0) [0|3] "" Vector__XXX
   SG_ PitchAngleFigureOfMerit : 48|2@1+ (1,0) [0|3] "" Vector__XXX
   SG_ PitchRate : 32|16@1+ (0.002,-64) [-64|64.51] "deg/sec" Vector__XXX
   SG_ RollAngle : 16|16@1+ (0.002,-64) [-64|64.51] "deg" Vector__XXX
   SG_ PitchAngle : 0|16@1+ (0.002,-64) [-64|64.51] "deg" Vector__XXX

BO_ 2566846718 TRF1: 8 Vector__XXX
   SG_ TransOilLevelMeasurementStatus : 60|4@1+ (1,0) [0|15] "" Vector__XXX
   SG_ TransOilLevelCountdownTimer : 56|4@1+ (1,0) [0|15] "" Vector__XXX
   SG_ TransOilLevelHigh_Low : 48|8@1+ (0.5,-62.5) [-62.5|62.5] "L" Vector__XXX
   SG_ TransOilTemp : 32|16@1+ (0.03125,-273) [-273|1734.97] "deg C" Vector__XXX
   SG_ TransOilPress : 24|8@1+ (16,0) [0|4000] "kPa" Vector__XXX
   SG_ TransFilterDiffPress : 16|8@1+ (2,0) [0|500] "kPa" Vector__XXX
   SG_ TransOilLevel : 8|8@1+ (0.4,0) [0|100] "%" Vector__XXX
   SG_ ClutchPress : 0|8@1+ (16,0) [0|4000] "kPa" Vector__XXX

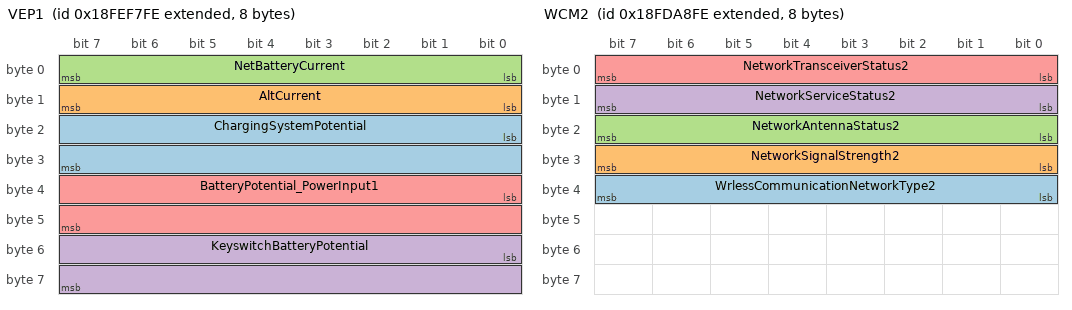
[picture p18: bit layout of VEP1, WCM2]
BO_ 2566846462 VEP1: 8 Vector__XXX
   SG_ ChargingSystemPotential : 16|16@1+ (0.05,0) [0|3212.75] "V" Vector__XXX
   SG_ AltCurrent : 8|8@1+ (1,0) [0|250] "A" Vector__XXX
   SG_ NetBatteryCurrent : 0|8@1+ (1,-125) [-125|125] "A" Vector__XXX
   SG_ KeyswitchBatteryPotential : 48|16@1+ (0.05,0) [0|3212.75] "V" Vector__XXX
   SG_ BatteryPotential_PowerInput1 : 32|16@1+ (0.05,0) [0|3212.75] "V" Vector__XXX

BO_ 2566760702 WCM2: 8 Vector__XXX
   SG_ WrlessCommunicationNetworkType2 : 32|8@1+ (1,0) [0|255] "" Vector__XXX
   SG_ NetworkSignalStrength2 : 24|8@1+ (0.4,0) [0|100] "%" Vector__XXX
   SG_ NetworkAntennaStatus2 : 16|8@1+ (1,0) [0|255] "" Vector__XXX
   SG_ NetworkServiceStatus2 : 8|8@1+ (1,0) [0|255] "" Vector__XXX
   SG_ NetworkTransceiverStatus2 : 0|8@1+ (1,0) [0|255] "" Vector__XXX

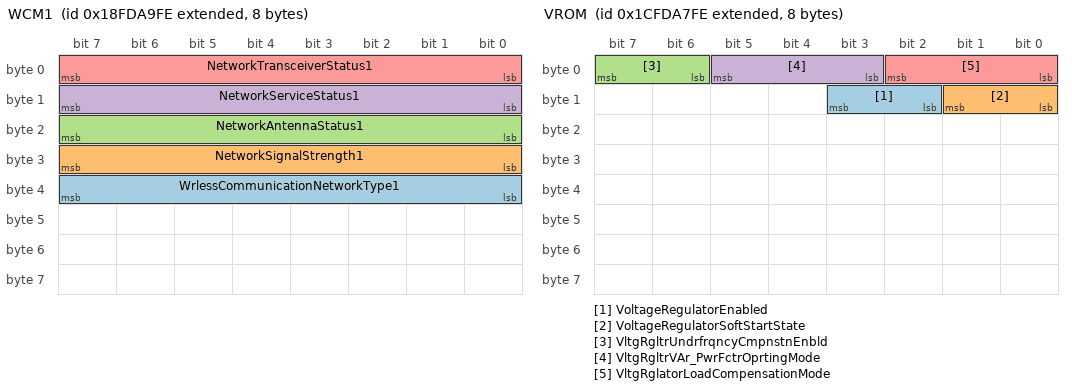
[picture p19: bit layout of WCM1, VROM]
BO_ 2566760958 WCM1: 8 Vector__XXX
   SG_ WrlessCommunicationNetworkType1 : 32|8@1+ (1,0) [0|255] "" Vector__XXX
   SG_ NetworkSignalStrength1 : 24|8@1+ (0.4,0) [0|100] "%" Vector__XXX
   SG_ NetworkAntennaStatus1 : 16|8@1+ (1,0) [0|255] "" Vector__XXX
   SG_ NetworkServiceStatus1 : 8|8@1+ (1,0) [0|255] "" Vector__XXX
   SG_ NetworkTransceiverStatus1 : 0|8@1+ (1,0) [0|255] "" Vector__XXX

BO_ 2633869310 VROM: 8 Vector__XXX
   SG_ VoltageRegulatorEnabled : 10|2@1+ (1,0) [0|3] "" Vector__XXX
   SG_ VoltageRegulatorSoftStartState : 8|2@1+ (1,0) [0|3] "" Vector__XXX
   SG_ VltgRgltrUndrfrqncyCmpnstnEnbld : 6|2@1+ (1,0) [0|3] "" Vector__XXX
   SG_ VltgRgltrVAr_PwrFctrOprtingMode : 3|3@1+ (1,0) [0|7] "" Vector__XXX
   SG_ VltgRglatorLoadCompensationMode : 0|3@1+ (1,0) [0|7] "" Vector__XXX

BO_ 2365433598 VREP: 8 Vector__XXX
   SG_ GnrtrOtputVoltageBiasPercentage : 32|16@1+ (0.1,-100) [-100|100] "%" Vector__XXX
   SG_ GeneratorExcitationFieldCurrent : 16|16@1+ (0.05,0) [0|3217.5] "A" Vector__XXX
   SG_ GeneratorExcitationFieldVoltage : 0|16@1+ (0.05,-1605.63) [-1605.63|1606.38] "V" Vector__XXX

BO_ 2566856106 Wheel_Angle: 0 Guidance
   SG_ Wheel_AngleSig : 0|16@1+ (1,0) [0|1] "" Vector__XXX

BO_ 2360125960 Guidance: 8 Guidance
   SG_ Wheel_Angle : 0|16@1+ (1,0) [0|1] "" Vector__XXX

BA_DEF_ SG_ "SigType" ENUM "Default","Range","RangeSigned","ASCII","Discrete","Control","ReferencePGN","DTC","StringDelimiter","StringLength","StringLengthControl";
BA_DEF_ SG_ "GenSigStartValue" INT 0 10000;
BA_DEF_ SG_ "GenSigSendType" ENUM "Default","Range","RangeSigned","ASCII","Discrete","Control","ReferencePGN","DTC","StringDelimiter","StringLength","StringLengthControl","Default","Range","RangeSigned","ASCII","Discrete","Control","ReferencePGN","DTC","StringDelimiter","StringLength","StringLengthControl","Cyclic","OnWrite","reserved","OnChange","reserved","reserved","reserved","NoSigSendType";
BA_DEF_ SG_ "GenSigILSupport" ENUM "Default","Range","RangeSigned","ASCII","Discrete","Control","ReferencePGN","DTC","StringDelimiter","StringLength","StringLengthControl","Default","Range","RangeSigned","ASCII","Discrete","Control","ReferencePGN","DTC","StringDelimiter","StringLength","StringLengthControl","Cyclic","OnWrite","reserved","OnChange","reserved","reserved","reserved","NoSigSendType","Default","Range","RangeSigned","ASCII","Discrete","Control","ReferencePGN","DTC","StringDelimiter","StringLength","StringLengthControl","Cyclic","OnWrite","reserved","OnChange","reserved","reserved","reserved","NoSigSendType","Yes","No";
BA_DEF_ SG_ "GenSigEVName" STRING ;
BA_DEF_ SG_ "SPN" INT 0 524287;
BA_DEF_ BO_ "GenMsgStartDelayTime" INT 0 100000;
BA_DEF_ BO_ "GenMsgILSupport" ENUM "Default","Range","RangeSigned","ASCII","Discrete","Control","ReferencePGN","DTC","StringDelimiter","StringLength","StringLengthControl","Default","Range","RangeSigned","ASCII","Discrete","Control","ReferencePGN","DTC","StringDelimiter","StringLength","StringLengthControl","Cyclic","OnWrite","reserved","OnChange","reserved","reserved","reserved","NoSigSendType","Default","Range","RangeSigned","ASCII","Discrete","Control","ReferencePGN","DTC","StringDelimiter","StringLength","StringLengthControl","Cyclic","OnWrite","reserved","OnChange","reserved","reserved","reserved","NoSigSendType","Yes","No","Default","Range","RangeSigned","ASCII","Discrete","Control","ReferencePGN","DTC","StringDelimiter","StringLength","StringLengthControl","Cyclic","OnWrite","reserved","OnChange","reserved","reserved","reserved","NoSigSendType","Yes","No","Yes","No";
BA_DEF_ BO_ "GenMsgRequestable" INT 0 1;
BA_DEF_ BO_ "GenMsgSendType" ENUM "Default","Range","RangeSigned","ASCII","Discrete","Control","ReferencePGN","DTC","StringDelimiter","StringLength","StringLengthControl","Default","Range","RangeSigned","ASCII","Discrete","Control","ReferencePGN","DTC","StringDelimiter","StringLength","StringLengthControl","Cyclic","OnWrite","reserved","OnChange","reserved","reserved","reserved","NoSigSendType","Default","Range","RangeSigned","ASCII","Discrete","Control","ReferencePGN","DTC","StringDelimiter","StringLength","StringLengthControl","Cyclic","OnWrite","reserved","OnChange","reserved","reserved","reserved","NoSigSendType","Yes","No","Default","Range","RangeSigned","ASCII","Discrete","Control","ReferencePGN","DTC","StringDelimiter","StringLength","StringLengthControl","Cyclic","OnWrite","reserved","OnChange","reserved","reserved","reserved","NoSigSendType","Yes","No","Yes","No","Default","Range","RangeSigned","ASCII","Discrete","Control","ReferencePGN","DTC","StringDelimiter","StringLength","StringLengthControl","Cyclic","OnWrite","reserved","OnChange","reserved","reserved","reserved","NoSigSendType","Yes","No","Yes","No","cyclic","reserved","cyclicIfActive","reserved","reserved","reserved","reserved","reserved","noMsgSendType";
BA_DEF_ BO_ "VFrameFormat" ENUM "Default","Range","RangeSigned","ASCII","Discrete","Control","ReferencePGN","DTC","StringDelimiter","StringLength","StringLengthControl","Default","Range","RangeSigned","ASCII","Discrete","Control","ReferencePGN","DTC","StringDelimiter","StringLength","StringLengthControl","Cyclic","OnWrite","reserved","OnChange","reserved","reserved","reserved","NoSigSendType","Default","Range","RangeSigned","ASCII","Discrete","Control","ReferencePGN","DTC","StringDelimiter","StringLength","StringLengthControl","Cyclic","OnWrite","reserved","OnChange","reserved","reserved","reserved","NoSigSendType","Yes","No","Default","Range","RangeSigned","ASCII","Discrete","Control","ReferencePGN","DTC","StringDelimiter","StringLength","StringLengthControl","Cyclic","OnWrite","reserved","OnChange","reserved","reserved","reserved","NoSigSendType","Yes","No","Yes","No","Default","Range","RangeSigned","ASCII","Discrete","Control","ReferencePGN","DTC","StringDelimiter","StringLength","StringLengthControl","Cyclic","OnWrite","reserved","OnChange","reserved","reserved","reserved","NoSigSendType","Yes","No","Yes","No","cyclic","reserved","cyclicIfActive","reserved","reserved","reserved","reserved","reserved","noMsgSendType","Default","Range","RangeSigned","ASCII","Discrete","Control","ReferencePGN","DTC","StringDelimiter","StringLength","StringLengthControl","Cyclic","OnWrite","reserved","OnChange","reserved","reserved","reserved","NoSigSendType","Yes","No","Yes","No","cyclic","reserved","cyclicIfActive","reserved","reserved","reserved","reserved","reserved","noMsgSendType","StandardCAN","ExtendedCAN","reserved","J1939PG";
BA_DEF_ BO_ "GenMsgCycleTime" INT 0 3;
BA_DEF_ SG_ "SystemSignalLongSymbol" STRING ;
BA_DEF_ BO_ "GenMsgBackgroundColor" STRING ;
BA_DEF_ BO_ "GenMsgForegroundColor" STRING ;
BA_DEF_ BO_ "matchingcriteria" INT 0 0;
BA_DEF_ BO_ "filterlabeling" INT 0 0;
BA_DEF_ BO_ "matchingcriteria" INT 0 0;
BA_DEF_ BO_ "filterlabeling" INT 0 0;
BA_DEF_DEF_ "SigType" "Default";
BA_DEF_DEF_ "GenSigStartValue" 0;
BA_DEF_DEF_ "GenSigSendType" "NoSigSendType";
BA_DEF_DEF_ "GenSigILSupport" "Yes";
BA_DEF_DEF_ "GenSigEVName" "Env";
BA_DEF_DEF_ "SPN" 0;
BA_DEF_DEF_ "GenMsgStartDelayTime" 0;
BA_DEF_DEF_ "GenMsgILSupport" "Yes";
BA_DEF_DEF_ "GenMsgRequestable" 1;
BA_DEF_DEF_ "GenMsgSendType" "noMsgSendType";
BA_DEF_DEF_ "VFrameFormat" "J1939PG";
BA_DEF_DEF_ "GenMsgCycleTime" 0;
BA_DEF_DEF_ "SystemSignalLongSymbol" "";
BA_DEF_DEF_ "GenMsgBackgroundColor" "#ffffff";
BA_DEF_DEF_ "GenMsgForegroundColor" "#000000";
BA_DEF_DEF_ "matchingcriteria" 1;
BA_DEF_DEF_ "filterlabeling" 0;
BA_DEF_DEF_ "matchingcriteria" 1;
BA_DEF_DEF_ "filterlabeling" 1;
BA_ "GenMsgCycleTime" BO_ 2566805758 100;
BA_ "GenMsgSendType" BO_ 2566805758 0;
BA_ "VFrameFormat" BO_ 2566805758 3;
BA_ "GenMsgCycleTime" BO_ 2566806014 100;
BA_ "GenMsgSendType" BO_ 2566806014 0;
BA_ "VFrameFormat" BO_ 2566806014 3;
BA_ "GenMsgCycleTime" BO_ 2362638078 100;
BA_ "GenMsgSendType" BO_ 2362638078 0;
BA_ "VFrameFormat" BO_ 2362638078 3;
BA_ "GenMsgCycleTime" BO_ 2365479678 100;
BA_ "GenMsgSendType" BO_ 2365479678 0;
BA_ "VFrameFormat" BO_ 2365479678 3;
BA_ "GenMsgCycleTime" BO_ 2566837758 1000;
BA_ "GenMsgSendType" BO_ 2566837758 0;
BA_ "VFrameFormat" BO_ 2566837758 3;
BA_ "GenMsgSendType" BO_ 2633922558 8;
BA_ "VFrameFormat" BO_ 2633922558 3;
BA_ "GenMsgCycleTime" BO_ 2566775038 1000;
BA_ "GenMsgSendType" BO_ 2566775038 0;
BA_ "VFrameFormat" BO_ 2566775038 3;
BA_ "GenMsgSendType" BO_ 2566836478 8;
BA_ "VFrameFormat" BO_ 2566836478 3;
BA_ "GenMsgSendType" BO_ 2565078782 8;
BA_ "VFrameFormat" BO_ 2565078782 3;
BA_ "GenMsgSendType" BO_ 2566836222 8;
BA_ "VFrameFormat" BO_ 2566836222 3;
BA_ "GenMsgSendType" BO_ 2566835966 8;
BA_ "VFrameFormat" BO_ 2566835966 3;
BA_ "SystemSignalLongSymbol" SG_ 2566835966 NOxConvertingCatalystAdsorberSta "NOxConvertingCatalystAdsorberSta";
BA_ "SystemSignalLongSymbol" SG_ 2566835966 BoostPressureControlSystemSuppor "BoostPressureControlSystemSuppor";
BA_ "SystemSignalLongSymbol" SG_ 2566835966 NOxConvertingCatalystAdsorberSup "NOxConvertingCatalystAdsorberSup";
BA_ "GenMsgSendType" BO_ 2566835710 8;
BA_ "VFrameFormat" BO_ 2566835710 3;
BA_ "GenMsgSendType" BO_ 2566835454 8;
BA_ "VFrameFormat" BO_ 2566835454 3;
BA_ "GenMsgSendType" BO_ 2566764542 8;
BA_ "VFrameFormat" BO_ 2566764542 3;
BA_ "GenMsgSendType" BO_ 2566764286 8;
BA_ "VFrameFormat" BO_ 2566764286 3;
BA_ "GenMsgSendType" BO_ 2566764030 8;
BA_ "VFrameFormat" BO_ 2566764030 3;
BA_ "GenMsgSendType" BO_ 2562981630 8;
BA_ "VFrameFormat" BO_ 2562981630 3;
BA_ "GenMsgSendType" BO_ 2562850558 8;
BA_ "VFrameFormat" BO_ 2562850558 3;
BA_ "GenMsgSendType" BO_ 2562916094 8;
BA_ "VFrameFormat" BO_ 2562916094 3;
BA_ "GenMsgSendType" BO_ 2566835198 8;
BA_ "VFrameFormat" BO_ 2566835198 3;
BA_ "GenMsgSendType" BO_ 2564030206 8;
BA_ "VFrameFormat" BO_ 2564030206 3;
BA_ "GenMsgSendType" BO_ 2564226814 8;
BA_ "VFrameFormat" BO_ 2564226814 3;
BA_ "GenMsgSendType" BO_ 2564292350 8;
BA_ "VFrameFormat" BO_ 2564292350 3;
BA_ "GenMsgSendType" BO_ 2564357886 8;
BA_ "VFrameFormat" BO_ 2564357886 3;
BA_ "GenMsgSendType" BO_ 2564423422 8;
BA_ "VFrameFormat" BO_ 2564423422 3;
BA_ "GenMsgSendType" BO_ 2564816638 8;
BA_ "VFrameFormat" BO_ 2564816638 3;
BA_ "GenMsgSendType" BO_ 2566837502 8;
BA_ "VFrameFormat" BO_ 2566837502 3;
BA_ "GenMsgSendType" BO_ 2566837246 8;
BA_ "VFrameFormat" BO_ 2566837246 3;
BA_ "GenMsgSendType" BO_ 2566836990 8;
BA_ "VFrameFormat" BO_ 2566836990 3;
BA_ "GenMsgSendType" BO_ 2566834942 8;
BA_ "VFrameFormat" BO_ 2566834942 3;
BA_ "GenMsgSendType" BO_ 2566780926 8;
BA_ "VFrameFormat" BO_ 2566780926 3;
BA_ "GenMsgSendType" BO_ 2566781182 8;
BA_ "VFrameFormat" BO_ 2566781182 3;
BA_ "GenMsgSendType" BO_ 2566778366 8;
BA_ "VFrameFormat" BO_ 2566778366 3;
BA_ "GenMsgSendType" BO_ 2566778622 8;
BA_ "VFrameFormat" BO_ 2566778622 3;
BA_ "GenMsgSendType" BO_ 2566778878 8;
BA_ "VFrameFormat" BO_ 2566778878 3;
BA_ "GenMsgSendType" BO_ 2566779134 8;
BA_ "VFrameFormat" BO_ 2566779134 3;
BA_ "GenMsgSendType" BO_ 2566779390 8;
BA_ "VFrameFormat" BO_ 2566779390 3;
BA_ "GenMsgSendType" BO_ 2566779646 8;
BA_ "VFrameFormat" BO_ 2566779646 3;
BA_ "GenMsgSendType" BO_ 2566779902 8;
BA_ "VFrameFormat" BO_ 2566779902 3;
BA_ "GenMsgSendType" BO_ 2566780158 8;
BA_ "VFrameFormat" BO_ 2566780158 3;
BA_ "GenMsgSendType" BO_ 2566780414 8;
BA_ "VFrameFormat" BO_ 2566780414 3;
BA_ "GenMsgSendType" BO_ 2566780670 8;
BA_ "VFrameFormat" BO_ 2566780670 3;
BA_ "GenMsgSendType" BO_ 2566781438 8;
BA_ "VFrameFormat" BO_ 2566781438 3;
BA_ "GenMsgSendType" BO_ 2566784254 8;
BA_ "VFrameFormat" BO_ 2566784254 3;
BA_ "GenMsgSendType" BO_ 2566784510 8;
BA_ "VFrameFormat" BO_ 2566784510 3;
BA_ "GenMsgSendType" BO_ 2566781694 8;
BA_ "VFrameFormat" BO_ 2566781694 3;
BA_ "GenMsgSendType" BO_ 2566781950 8;
BA_ "VFrameFormat" BO_ 2566781950 3;
BA_ "GenMsgSendType" BO_ 2566782206 8;
BA_ "VFrameFormat" BO_ 2566782206 3;
BA_ "GenMsgSendType" BO_ 2566782462 8;
BA_ "VFrameFormat" BO_ 2566782462 3;
BA_ "GenMsgSendType" BO_ 2566782718 8;
BA_ "VFrameFormat" BO_ 2566782718 3;
BA_ "GenMsgSendType" BO_ 2566782974 8;
BA_ "VFrameFormat" BO_ 2566782974 3;
BA_ "GenMsgSendType" BO_ 2566783230 8;
BA_ "VFrameFormat" BO_ 2566783230 3;
BA_ "GenMsgSendType" BO_ 2566783486 8;
BA_ "VFrameFormat" BO_ 2566783486 3;
BA_ "GenMsgSendType" BO_ 2566783742 8;
BA_ "VFrameFormat" BO_ 2566783742 3;
BA_ "GenMsgSendType" BO_ 2566783998 8;
BA_ "VFrameFormat" BO_ 2566783998 3;
BA_ "GenMsgSendType" BO_ 2566784766 8;
BA_ "VFrameFormat" BO_ 2566784766 3;
BA_ "GenMsgSendType" BO_ 2566776830 8;
BA_ "VFrameFormat" BO_ 2566776830 3;
BA_ "GenMsgSendType" BO_ 2566777342 8;
BA_ "VFrameFormat" BO_ 2566777342 3;
BA_ "GenMsgSendType" BO_ 2566777598 8;
BA_ "VFrameFormat" BO_ 2566777598 3;
BA_ "GenMsgSendType" BO_ 2566777854 8;
BA_ "VFrameFormat" BO_ 2566777854 3;
BA_ "GenMsgSendType" BO_ 2566777086 8;
BA_ "VFrameFormat" BO_ 2566777086 3;
BA_ "GenMsgSendType" BO_ 2566778110 8;
BA_ "VFrameFormat" BO_ 2566778110 3;
BA_ "GenMsgSendType" BO_ 2633895422 8;
BA_ "VFrameFormat" BO_ 2633895422 3;
BA_ "GenMsgSendType" BO_ 2566838526 8;
BA_ "VFrameFormat" BO_ 2566838526 3;
BA_ "GenMsgSendType" BO_ 2565799678 8;
BA_ "VFrameFormat" BO_ 2565799678 3;
BA_ "GenMsgSendType" BO_ 2563440382 8;
BA_ "VFrameFormat" BO_ 2563440382 3;
BA_ "GenMsgSendType" BO_ 2632711934 8;
BA_ "VFrameFormat" BO_ 2632711934 3;
BA_ "GenMsgSendType" BO_ 2632777470 8;
BA_ "VFrameFormat" BO_ 2632777470 3;
BA_ "GenMsgSendType" BO_ 2563374846 8;
BA_ "VFrameFormat" BO_ 2563374846 3;
BA_ "GenMsgSendType" BO_ 2565537534 8;
BA_ "VFrameFormat" BO_ 2565537534 3;
BA_ "VFrameFormat" BO_ 2499635966 3;
BA_ "VFrameFormat" BO_ 2633853438 3;
BA_ "GenMsgCycleTime" BO_ 2432520702 1000;
BA_ "GenMsgSendType" BO_ 2432520702 0;
BA_ "VFrameFormat" BO_ 2432520702 3;
BA_ "VFrameFormat" BO_ 2566745086 3;
BA_ "GenMsgSendType" BO_ 2566739198 8;
BA_ "VFrameFormat" BO_ 2566739198 3;
BA_ "GenMsgSendType" BO_ 2566739454 8;
BA_ "VFrameFormat" BO_ 2566739454 3;
BA_ "GenMsgSendType" BO_ 2566739710 8;
BA_ "VFrameFormat" BO_ 2566739710 3;
BA_ "GenMsgSendType" BO_ 2566739966 8;
BA_ "VFrameFormat" BO_ 2566739966 3;
BA_ "GenMsgSendType" BO_ 2566740222 8;
BA_ "VFrameFormat" BO_ 2566740222 3;
BA_ "GenMsgSendType" BO_ 2566740478 8;
BA_ "VFrameFormat" BO_ 2566740478 3;
BA_ "GenMsgSendType" BO_ 2566740734 8;
BA_ "VFrameFormat" BO_ 2566740734 3;
BA_ "GenMsgSendType" BO_ 2566740990 8;
BA_ "VFrameFormat" BO_ 2566740990 3;
BA_ "GenMsgSendType" BO_ 2566741246 8;
BA_ "VFrameFormat" BO_ 2566741246 3;
BA_ "GenMsgSendType" BO_ 2566741502 8;
BA_ "VFrameFormat" BO_ 2566741502 3;
BA_ "GenMsgSendType" BO_ 2566741758 8;
BA_ "VFrameFormat" BO_ 2566741758 3;
BA_ "GenMsgSendType" BO_ 2566742014 8;
BA_ "VFrameFormat" BO_ 2566742014 3;
BA_ "GenMsgSendType" BO_ 2560622334 8;
BA_ "VFrameFormat" BO_ 2560622334 3;
BA_ "VFrameFormat" BO_ 2566744062 3;
BA_ "GenMsgCycleTime" BO_ 2499630078 500;
BA_ "GenMsgSendType" BO_ 2499630078 0;
BA_ "VFrameFormat" BO_ 2499630078 3;
BA_ "VFrameFormat" BO_ 2560556798 3;
BA_ "GenMsgSendType" BO_ 2566750462 8;
BA_ "VFrameFormat" BO_ 2566750462 3;
BA_ "GenMsgSendType" BO_ 2566750974 8;
BA_ "VFrameFormat" BO_ 2566750974 3;
BA_ "VFrameFormat" BO_ 2566754558 3;
BA_ "VFrameFormat" BO_ 2566749950 3;
BA_ "VFrameFormat" BO_ 2566838782 3;
BA_ "VFrameFormat" BO_ 2561146622 3;
BA_ "VFrameFormat" BO_ 2561081086 3;
BA_ "VFrameFormat" BO_ 2561015550 3;
BA_ "GenMsgCycleTime" BO_ 2566746622 1000;
BA_ "GenMsgSendType" BO_ 2566746622 0;
BA_ "VFrameFormat" BO_ 2566746622 3;
BA_ "GenMsgCycleTime" BO_ 2566845950 1000;
BA_ "GenMsgSendType" BO_ 2566845950 0;
BA_ "VFrameFormat" BO_ 2566845950 3;
BA_ "GenMsgSendType" BO_ 2566840062 8;
BA_ "VFrameFormat" BO_ 2566840062 3;
BA_ "GenMsgCycleTime" BO_ 2566827774 1000;
BA_ "GenMsgSendType" BO_ 2566827774 0;
BA_ "VFrameFormat" BO_ 2566827774 3;
BA_ "GenMsgCycleTime" BO_ 2566846974 1000;
BA_ "GenMsgSendType" BO_ 2566846974 0;
BA_ "VFrameFormat" BO_ 2566846974 3;
BA_ "GenMsgSendType" BO_ 2633935614 8;
BA_ "VFrameFormat" BO_ 2633935614 3;
BA_ "GenMsgCycleTime" BO_ 2566803966 250;
BA_ "GenMsgSendType" BO_ 2566803966 0;
BA_ "VFrameFormat" BO_ 2566803966 3;
BA_ "GenMsgCycleTime" BO_ 2432593918 100;
BA_ "GenMsgSendType" BO_ 2432593918 0;
BA_ "VFrameFormat" BO_ 2432593918 3;
BA_ "GenMsgSendType" BO_ 2633935102 8;
BA_ "VFrameFormat" BO_ 2633935102 3;
BA_ "GenMsgSendType" BO_ 2633927934 8;
BA_ "VFrameFormat" BO_ 2633927934 3;
BA_ "GenMsgCycleTime" BO_ 2566847998 500;
BA_ "GenMsgSendType" BO_ 2566847998 0;
BA_ "VFrameFormat" BO_ 2566847998 3;
BA_ "GenMsgSendType" BO_ 2565406462 8;
BA_ "VFrameFormat" BO_ 2565406462 3;
BA_ "GenMsgCycleTime" BO_ 2566803198 100;
BA_ "GenMsgSendType" BO_ 2566803198 0;
BA_ "VFrameFormat" BO_ 2566803198 3;
BA_ "GenMsgCycleTime" BO_ 2565870334 50;
BA_ "GenMsgSendType" BO_ 2565870334 0;
BA_ "VFrameFormat" BO_ 2565870334 3;
BA_ "VFrameFormat" BO_ 2566762238 3;
BA_ "GenMsgCycleTime" BO_ 2364543998 10;
BA_ "GenMsgSendType" BO_ 2364543998 0;
BA_ "VFrameFormat" BO_ 2364543998 3;
BA_ "GenMsgCycleTime" BO_ 2566846718 1000;
BA_ "GenMsgSendType" BO_ 2566846718 0;
BA_ "VFrameFormat" BO_ 2566846718 3;
BA_ "GenMsgCycleTime" BO_ 2566846462 1000;
BA_ "GenMsgSendType" BO_ 2566846462 0;
BA_ "VFrameFormat" BO_ 2566846462 3;
BA_ "GenMsgSendType" BO_ 2566760702 8;
BA_ "VFrameFormat" BO_ 2566760702 3;
BA_ "GenMsgSendType" BO_ 2566760958 8;
BA_ "VFrameFormat" BO_ 2566760958 3;
BA_ "GenMsgCycleTime" BO_ 2633869310 1000;
BA_ "GenMsgSendType" BO_ 2633869310 0;
BA_ "VFrameFormat" BO_ 2633869310 3;
BA_ "GenMsgCycleTime" BO_ 2365433598 100;
BA_ "GenMsgSendType" BO_ 2365433598 0;
BA_ "VFrameFormat" BO_ 2365433598 3;
VAL_ 2362638078 SpeedDependentLevelCtrlRq 3 "DonTCare_TakeNoAction" 2 "Reserved" 1 "Activate" 0 "Deactivate";
VAL_ 2362638078 PrhbtAutomaticAirSuspensionCtrl 3 "NotAvailable" 2 "ErrorIndicator" 1 "RqPrhbtAtmaticAirSuspensionCtrl" 0 "NRq01RqstPrhbtdAtmtcArSspnsnCtr";
VAL_ 2362638078 MemoryLevelRq 15 "DontCare" 13 "StoreMemoryLevel5" 12 "StoreMemoryLevel4" 11 "StoreMemoryLevel3" 10 "StoreMemoryLevel2" 9 "StoreMemoryLevel1" 14 "Reserved" 5 "MemoryLevel5Rq" 4 "MemoryLevel4Rq" 3 "MemoryLevel3Rq" 2 "MemoryLevel2Rq" 1 "MemoryLevel1Rq" 0 "NoMemoryLevelRq";
VAL_ 2362638078 AllowLevelCtrlDuringBrakingCmd 3 "DonTCare_TakeNoAction" 2 "Reserved" 1 "AllowLevelCtrlDuringBraking" 0 "DisallowLevelCtrlDuringBraking";
VAL_ 2362638078 ProhibitAirSuspensionCtrl 3 "NotAvailable" 2 "ErrorIndicator" 1 "RqProhibitAirSuspensionCtrl" 0 "NoRq";
VAL_ 2362638078 KneelingCmdRearAxle 3 "DontCare_TakeNoAction" 2 "Reserved" 1 "ActivateKneeling" 0 "DeactivateKneeling";
VAL_ 2362638078 KneelingCmdFrontAxle 3 "DontCare_TakeNoAction" 2 "Reserved" 1 "ActivateKneeling" 0 "DeactivateKneeling";
VAL_ 2362638078 LevelCtrlModeRq 15 "DontCare_TakeNoAction" 14 "Reserved" 9 "1101NotDefined" 8 "ExhaustBellows" 7 "TractionHelpLoadReduce" 6 "OptmmTrctn2IPrssAtThDrvnAxlIsCt" 5 "OptmmTrctn1IPrssAtThDrvnAxlIsCt" 4 "PrssRt2IRtBtwnThPrssrsAtThDrvnA" 3 "PrssRt1IRtBtwnThPrssrsAtThDrvnA" 2 "LdFxngIDrvnAxlIsLddTAVlDfndByTh" 1 "TrctnHlpIDrvnAxlIsLddTAMxVlGvnB" 0 "NrmlOprtnISystmPrfrmsAPrCtrlOfT";
VAL_ 2362638078 NominalLevelRqRearAxle 11 "1101NotDefined" 10 "LowerRq" 15 "DontCare_TakeNoAction" 14 "Reserved" 9 "RaiseRq" 8 "StopLevelChange" 7 "LowerLevel" 6 "UpperLevel" 5 "CustomerLevel" 4 "PresetLevel" 3 "NormalLevel3" 2 "NormalLevel2" 1 "NormalLevel1" 0 "NoLevelRq";
VAL_ 2362638078 NominalLevelRqFrontAxle 11 "1101NotDefined" 10 "LowerRq" 15 "DontCare_TakeNoAction" 14 "Reserved" 9 "RaiseRq" 8 "StopLevelChange" 7 "LowerLevel" 6 "UpperLevel" 5 "CustomerLevel" 4 "PresetLevel" 3 "NormalLevel3" 2 "NormalLevel2" 1 "NormalLevel1" 0 "NoLevelRq";
VAL_ 2362638078 KneelingCtrlModeRq 3 "DontCare_TakeNoAction" 2 "Reserved" 1 "ManuallyActuated" 0 "AutomaticallyActuated";
VAL_ 2362638078 KneelingRqRightSide 3 "DontCare_TakeNoAction" 2 "Reserved" 1 "KneelingRq" 0 "NoKneelingRq";
VAL_ 2362638078 KneelingRqLeftSide 3 "DontCare_TakeNoAction" 2 "Reserved" 1 "KneelingRq" 0 "NoKneelingRq";
VAL_ 2362638078 AutomaticTractionHelp 3 "DontCare" 2 "Reserved" 1 "EnableAutomaticTractionHelp" 0 "DisableAutomaticTractionHelp";
VAL_ 2362638078 LiftAxle2PosCmd 3 "DontCare_TakeNoAction" 2 "Reserved" 1 "LiftAxlePosUp_TagAxleUnladen" 0 "LiftAxlePosDown_TagAxleLaden";
VAL_ 2362638078 LiftAxle1PosCmd 3 "DontCare_TakeNoAction" 2 "Reserved" 1 "LiftAxlePosUp_TagAxleUnladen" 0 "LiftAxlePosDown_TagAxleLaden";
VAL_ 2365479678 SpeedDependantLevelCtrlStatus 3 "DonTCare_TakeNoAction" 2 "Reserved" 1 "Active" 0 "Inactive";
VAL_ 2365479678 MemoryLevel 15 "NotAvailable" 14 "ErrorIndicator" 13 "MemoryLevel5Stored" 12 "MemoryLevel4Stored" 11 "MemoryLevel3Stored" 10 "MemoryLevel2Stored" 9 "MemoryLevel1Stored" 8 "Reserved" 5 "MemoryLevel5Selected" 4 "MemoryLevel4Selected" 3 "MemoryLevel3Selected" 2 "MemoryLevel2Selected" 1 "MemoryLevel1Selected" 0 "NoMemoryLevel";
VAL_ 2365479678 AllwLvelCtrlDuringBrakingStatus 3 "DonTCare_TakeNoAction" 2 "Reserved" 1 "Activate" 0 "Deactivate";
VAL_ 2365479678 SspensionCtrlRefusalInformation 15 "NotAvailable" 14 "Error" 8 "1101NotDefined" 7 "RqedLevelNotAvailable" 6 "GnrlRjctINSpcifiedReasonApplies" 5 "BelowSpeedLimit" 4 "AboveSpeedLimit" 3 "BogieDiffNotLocked" 2 "WouldExceedAxleLoadLimit" 1 "AxleLoadLimitReached" 0 "ActualRqNotRefused";
VAL_ 2365479678 SuspensionRemoteCtrl2 3 "NotAvailable" 2 "Error" 1 "Active" 0 "NotActive";
VAL_ 2365479678 SuspensionRemoteCtrl1 3 "NotAvailable" 2 "Error" 1 "Active" 0 "NotActive";
VAL_ 2365479678 RearAxleInBumperRange 3 "NotAvailable" 2 "Error" 1 "ActualLevelWithinBumperRange" 0 "ActualLevelOutOfBumperRange";
VAL_ 2365479678 FrontAxleInBumperRange 3 "NotAvailable" 2 "Error" 1 "ActualLevelWithinBumperRange" 0 "ActualLevelOutOfBumperRange";
VAL_ 2365479678 DoorRelease 3 "NotAvailable" 2 "Error" 1 "DoorsMayBeOpened" 0 "DoorsMayNotBeOpened";
VAL_ 2365479678 VehicleMotionInhibit 3 "NotAvailable" 2 "Error" 1 "VehicleMotionIsInhibited" 0 "VehicleMayBeMoved";
VAL_ 2365479678 SecurityDevice 3 "NotAvailable" 2 "Error" 1 "Active" 0 "NotActive";
VAL_ 2365479678 LevelCtrlMode 11 "1101NotDefined" 10 "AtmtcArSuspensionCtrlProhibited" 15 "NotAvailable" 14 "Error" 9 "AirSuspensionCtrlProhibited" 8 "ExhstngBllwFnctnIBllwsArExhstdT" 7 "TractionHelpLoadReduce" 6 "OptmmTrctn2IPrssAtThDrvnAxlIsCt" 5 "OptmmTrctn1IPrssAtThDrvnAxlIsCt" 4 "PrssRt2IRtBtwnThPrssrsAtThDrvnA" 3 "PrssRt1IRtBtwnThPrssrsAtThDrvnA" 2 "LdFxngIDrvnAxlnIsLddTAVlDfndByT" 1 "TrctnHlpIDrvnAxlIsLddTAMxVlGvnB" 0 "NrmlOprtnISystmPrfrmsAPrCtrlOfT";
VAL_ 2365479678 KneelingInformation 15 "NotAvailable" 14 "Error" 5 "1101NotDefined" 4 "KneelingAborted" 3 "LiftingActive" 2 "KneelingLevelReached" 0 "NotActive";
VAL_ 2365479678 LiftingCtrlModeRearAxle 3 "NotAvailable" 2 "Error" 1 "LiftingActive" 0 "LiftingNotActive";
VAL_ 2365479678 LiftingCtrlModeFrontAxle 3 "NotAvailable" 2 "Error" 1 "LiftingActive" 0 "LiftingNotActive";
VAL_ 2365479678 LoweringCtrlModeRearAxle 3 "NotAvailable" 2 "Error" 1 "LoweringActive" 0 "LoweringNotActive";
VAL_ 2365479678 LoweringCtrlModeFrontAxle 3 "NotAvailable" 2 "Error" 1 "LoweringActive" 0 "LoweringNotActive";
VAL_ 2365479678 AboveNominalLevelRearAxle 3 "NotAvailable" 2 "Error" 1 "Above" 0 "NotAbove";
VAL_ 2365479678 AboveNominalLevelFrontAxle 3 "NotAvailable" 2 "Error" 1 "Above" 0 "NotAbove";
VAL_ 2365479678 BelowNominalLevelRearAxle 3 "NotAvailable" 2 "Error" 1 "Below" 0 "NotBelow";
VAL_ 2365479678 BelowNominalLevelFrontAxle 3 "NotAvailable" 2 "Error" 1 "Below" 0 "NotBelow";
VAL_ 2365479678 NominalLevelRearAxle 9 "Raising" 11 "1101NotDefined" 10 "Lowering" 15 "NotAvailable" 14 "Error" 8 "NotDefined" 7 "LowerLevel" 6 "UpperLevel" 5 "CustomerLevel" 4 "PresetLevel" 3 "NormalLevel3" 2 "NormalLevel2" 1 "NormalLevel1" 0 "LevelNotSpecified";
VAL_ 2365479678 NominalLevelFrontAxle 9 "Raising" 11 "1101NotDefined" 10 "Lowering" 15 "NotAvailable" 14 "Error" 8 "NotDefined" 7 "LowerLevel" 6 "UpperLevel" 5 "CustomerLevel" 4 "PresetLevel" 3 "NormalLevel3" 2 "NormalLevel2" 1 "NormalLevel1" 0 "LevelNotSpecified";
VAL_ 2365479678 LiftAxle2Pos 3 "NotAvailable" 2 "Error" 1 "LiftAxlePosUp_TagAxleUnladen" 0 "LiftAxlePosDown_TagAxleLaden";
VAL_ 2365479678 LiftAxle1Pos 3 "NotAvailable" 2 "Error" 1 "LiftAxlePosUp_TagAxleUnladen" 0 "LiftAxlePosDown_TagAxleLaden";
VAL_ 2566837758 Alt4Status 3 "notAvailable" 2 "error" 1 "Alt4Charging" 0 "Alt4NotCharging";
VAL_ 2566837758 Alt3Status 3 "notAvailable" 2 "error" 1 "Alt3Charging" 0 "Alt3NotCharging";
VAL_ 2566837758 Alt2Status 3 "notAvailable" 2 "error" 1 "Alt2Charging" 0 "Alt2NotCharging";
VAL_ 2566837758 Alt1Status 3 "notAvailable" 2 "error" 1 "Alt1Charging" 0 "Alt1NotCharging";
VAL_ 2566836478 TestIdentifier 250 "Last Measured Scaled Results" 249 "Command Standard Test" 247 "All scaled test results";
VAL_ 2565078782 TestIdentifier 250 "Last Measured Scaled Results" 249 "Command Standard Test" 247 "All scaled test results";
VAL_ 2565078782 FailureModeIdentifier1 31 "Not available" 19 "Received network data in error" 18 "Below normal (moderately severe)" 17 "Below normal (least severe)" 16 "Above normal (moderately severe)" 15 "Above normal (least severe)" 14 "Special intstructions" 13 "Out of calibration" 12 "Bad intelligent device" 11 "Root cause not known" 10 "Abnormal rate of change" 9 "Abnormal update rate" 8 "Abnormal frequency" 7 "Mechanical system not responding" 6 "Current above normal" 5 "Current below normal" 4 "Voltage below normal" 3 "Voltage above normal" 2 "Data erratic" 1 "Below normal (most severe)" 0 "Above normal (most severe)";
VAL_ 2566836222 FlashRedStopLamp 3 "Unavailable / Do Not Flash" 2 "Reserved" 1 "Fast Flash" 0 "Slow Flash";
VAL_ 2566836222 FlashProtectLamp 3 "Unavailable / Do Not Flash" 2 "Reserved" 1 "Fast Flash" 0 "Slow Flash";
VAL_ 2566836222 FlashMalfuncIndicatorLamp 3 "Unavailable / Do Not Flash" 2 "Reserved" 1 "Fast Flash" 0 "Slow Flash";
VAL_ 2566836222 FlashAmberWarningLamp 3 "Unavailable / Do Not Flash" 2 "Reserved" 1 "Fast Flash" 0 "Slow Flash";
VAL_ 2566836222 MalfunctionIndicatorLampStatus 3 "Not available" 2 "Reserved" 1 "Lamp on" 0 "Lamp off";
VAL_ 2566836222 RedStopLampState 3 "Not available" 2 "Reserved" 1 "Lamp on" 0 "Lamp off";
VAL_ 2566836222 AmberWarningLampStatus 3 "Not available" 2 "Reserved" 1 "Lamp on" 0 "Lamp off";
VAL_ 2566836222 ProtectLampStatus 3 "Not available" 2 "Reserved" 1 "Lamp on" 0 "Lamp off";
VAL_ 2566835966 MisfireMonitoringSupport 3 "Not available" 2 "Reserved" 1 "test supported" 0 "test not supported";
VAL_ 2566835966 OBDCompliance 25 "OBD-M (SI-SD/I)" 23 "HD EOBD" 22 "OBD II (California, ARB 07/08)" 21 "WWH OBD" 20 "HD OBD" 19 "HD OBD P" 18 "EMD+" 17 "EMD" 16 "Heavy Duty Vehicles (EURO EEC) C" 15 "Heavy Duty Vehicles (EURO V) B2" 14 "Heavy Duty Vehicles (EURO IV) B1" 13 "JOBD, EOBD and OBD II" 12 "JOBD and EOBD" 11 "JOBD and OBD II" 10 "JOBD" 9 "EOBD, OBD and OBD II" 8 "EOBD and OBD" 7 "EOBD and OBD II" 6 "EOBD" 5 "Not intended to meet OBD II req." 4 "OBD I" 3 "OBD and OBD II" 2 "OBD (Federal, EPA)" 1 "OBD II (California, ARB)" 0 "Reserver for assignment by SAE";
VAL_ 2566835966 SecondAirSystemMonStatus 1 "TestNotComplete" 0 "TestComplete";
VAL_ 2566835966 EvaporativeSystemMonStatus 1 "TestNotComplete" 0 "TestComplete";
VAL_ 2566835966 ACSystemRefrigerantMonStatus 1 "TestNotComplete" 0 "TestComplete";
VAL_ 2566835966 OxygenSensorHeaterMonStatus 1 "TestNotComplete" 0 "TestComplete";
VAL_ 2566835966 OxygenSensorMonStatus 1 "test not complete" 0 "test complete";
VAL_ 2566835966 EGRSystemMonitoringStatus 1 "TestNotComplete" 0 "TestComplete";
VAL_ 2566835966 CatalystMonStatus 0 "TestComplete" 1 "TestNotComplete";
VAL_ 2566835966 ColdStartAidSystemMonStatus 1 "TestNotComplete" 0 "TestComplete";
VAL_ 2566835966 HeatedCatalystMonStatus 1 "TestNotComplete" 0 "TestComplete";
VAL_ 2566835966 CatalystMonSupp 1 "TestSupported" 0 "TestNotSupported";
VAL_ 2566835966 ColdStartAidSystemMonSupp 1 "TestSupported" 0 "TestNotSupported";
VAL_ 2566835966 HeatedCatalystMonSupp 1 "TestSupported" 0 "TestNotSupported";
VAL_ 2566835966 EvaporativeSystemMonSupp 1 "TestSupported" 0 "TestNotSupported";
VAL_ 2566835966 SecondAirSystemMonSupp 1 "TestSupported" 0 "TestNotSupported";
VAL_ 2566835966 ACSystemRefrigerantMonSupp 1 "TestSupported" 0 "TestNotSupported";
VAL_ 2566835966 OxygenSensorMonSupp 1 "TestSupported" 0 "TestNotSupported";
VAL_ 2566835966 OxygenSensorHeaterMonSupp 1 "TestSupported" 0 "TestNotSupported";
VAL_ 2566835966 EGRSystemMonitoringSupp 1 "TestSupported" 0 "TestNotSupported";
VAL_ 2566835966 MisfireMonitoringStatus 1 "test not complete" 0 "test complete";
VAL_ 2566835966 ComprehensiveCompMonStatus 1 "test not complete" 0 "test complete";
VAL_ 2566835966 FuelSystemMonitoringStatus 1 "test not complete" 0 "test complete";
VAL_ 2566835966 ComprehensiveComponentMonSupp 3 "Not available" 2 "Reserved" 1 "test supported" 0 "test not supported";
VAL_ 2566835966 FuelSystemMonitoringSupport 1 "test supported" 0 "test not supported";
VAL_ 2566835710 EngTorqueMode 15 "Not available" 11 "Remote accelerator" 10 "Braking system" 9 "High speed governor" 8 "Torque limiting" 7 "ABS control" 6 "Transmission control" 5 "ASR control" 4 "Road speed governor" 3 "PTO governor" 2 "Cruise control" 1 "Accelerator pedal/operator selec" 0 "Low idle governor/no request (de";
VAL_ 2566764286 SPNSupportTypeSTR3 1 "SupportedInScaledTestResults" 0 "NotSupportedInScaledTestResults";
VAL_ 2566764286 SPNSupportTypeSTR2 1 "SupportedInScaledTestResults" 0 "NotSupportedInScaledTestResults";
VAL_ 2566764286 SPNSupportTypeEFF3 1 "SupportedInExFreezeFrame" 0 "NotSupportedInExFreezeFrame";
VAL_ 2566764286 SPNSupportTypeEFF2 1 "SupportedInExFreezeFrame" 0 "NotSupportedInExFreezeFrame";
VAL_ 2566764286 SPNSupportTypeDS3 1 "SupportedInDataStream" 0 "NotSupportedInDataStream";
VAL_ 2566764286 SPNSupportTypeDS2 1 "SupportedInDataStream" 0 "NotSupportedInDataStream";
VAL_ 2566764286 SPNSupportTypeSTR1 1 "SupportedInScaledTestResults" 0 "NotSupportedInScaledTestResults";
VAL_ 2566764286 SPNSupportTypeDS1 1 "SupportedInDataStream" 0 "NotSupportedInDataStream";
VAL_ 2566764286 SPNSupportTypeEFF1 1 "SupportedInExFreezeFrame" 0 "NotSupportedInExFreezeFrame";
VAL_ 2566764030 FlashRedStopLamp 3 "Unavailable / Do Not Flash" 2 "Reserved" 1 "Fast Flash" 0 "Slow Flash";
VAL_ 2566764030 FlashProtectLamp 3 "Unavailable / Do Not Flash" 2 "Reserved" 1 "Fast Flash" 0 "Slow Flash";
VAL_ 2566764030 FlashMalfuncIndicatorLamp 3 "Unavailable / Do Not Flash" 2 "Reserved" 1 "Fast Flash" 0 "Slow Flash";
VAL_ 2566764030 FlashAmberWarningLamp 3 "Unavailable / Do Not Flash" 2 "Reserved" 1 "Fast Flash" 0 "Slow Flash";
VAL_ 2566764030 MalfunctionIndicatorLampStatus 3 "Not available" 2 "Reserved" 1 "Lamp on" 0 "Lamp off";
VAL_ 2566764030 RedStopLampState 3 "Not available" 2 "Reserved" 1 "Lamp on" 0 "Lamp off";
VAL_ 2566764030 AmberWarningLampStatus 3 "Not available" 2 "Reserved" 1 "Lamp on" 0 "Lamp off";
VAL_ 2566764030 ProtectLampStatus 3 "Not available" 2 "Reserved" 1 "Lamp on" 0 "Lamp off";
VAL_ 2562981630 FailureModeIdentifier1 31 "Not available" 19 "Received network data in error" 18 "Below normal (moderately severe)" 17 "Below normal (least severe)" 16 "Above normal (moderately severe)" 15 "Above normal (least severe)" 14 "Special intstructions" 13 "Out of calibration" 12 "Bad intelligent device" 11 "Root cause not known" 10 "Abnormal rate of change" 9 "Abnormal update rate" 8 "Abnormal frequency" 7 "Mechanical system not responding" 6 "Current above normal" 5 "Current below normal" 4 "Voltage below normal" 3 "Voltage above normal" 2 "Data erratic" 1 "Below normal (most severe)" 0 "Above normal (most severe)";
VAL_ 2566835198 MalfunctionIndicatorLampStatus 3 "Not available" 2 "Reserved" 1 "Lamp on" 0 "Lamp off";
VAL_ 2566835198 RedStopLampState 3 "Not available" 2 "Reserved" 1 "Lamp on" 0 "Lamp off";
VAL_ 2566835198 AmberWarningLampStatus 3 "Not available" 2 "Reserved" 1 "Lamp on" 0 "Lamp off";
VAL_ 2566835198 ProtectLampStatus 3 "Not available" 2 "Reserved" 1 "Lamp on" 0 "Lamp off";
VAL_ 2566835198 FlashRedStopLamp 3 "Unavailable / Do Not Flash" 2 "Reserved" 1 "Fast Flash" 0 "Slow Flash";
VAL_ 2566835198 FlashProtectLamp 3 "Unavailable / Do Not Flash" 2 "Reserved" 1 "Fast Flash" 0 "Slow Flash";
VAL_ 2566835198 FlashMalfuncIndicatorLamp 3 "Unavailable / Do Not Flash" 2 "Reserved" 1 "Fast Flash" 0 "Slow Flash";
VAL_ 2566835198 FlashAmberWarningLamp 3 "Unavailable / Do Not Flash" 2 "Reserved" 1 "Fast Flash" 0 "Slow Flash";
VAL_ 2564357886 Seed 255 "NoFurtherKeyRequiredOfTool" 1 "UseLongSeedOrKeyFromDataSecMsg" 0 "SeedCompleted_BeginSendingKey";
VAL_ 2564357886 EDCP_Extension 9 "DataInErrIndAndDataInSeedIsTime" 6 "DataInErrorIndicator" 3 "ConcatenateDataAsLowerEDCParam" 2 "ConcatenateDataAsHigherEDCParam" 0 "Completed" 255 "NoErrIndicator/EDCParamAvailable";
VAL_ 2564357886 ErrorIndicator 16777215 "NoErrorIndicatorAvailable" 65540 "TransprtNotComplWithinTimeAllowd" 65539 "TransportNotInitWithinTimeAllowd" 65538 "NoResponseInTheTimeAllowed" 65537 "ModuleExceedingNumberOfRetries" 65536 "AbortFromExtToNormalSoftwareProc" 4103 "VehicleNotInParkOrNotStationary" 4102 "EngineRunning" 4101 "NotInEngineeringOrDevelopmentMode" 4100 "NotInDiagnosticMode" 4099 "InvalidKey" 4098 "InvalidUserLevel" 4097 "InvalidPassword" 4096 "SecurityErrorGeneral" 266 "NameDoesNotConformToExpectdValue" 265 "DataDoesNotConformToValueRanges" 264 "AddrForBootLoadExeInvalidBoundary" 263 "AddrForBootLoadExeOutsideExeMem" 262 "OpReqExeTransfAndEraseOfProgMem" 261 "OpRequiresPriorEraseOfProgramMem" 260 "OpRequiresPriorEraseOfDataMem" 259 "ReqMemoryExceededAvailableMemory" 258 "LengthNotValidForMemStructAndOp" 257 "AddressNotOnValidBoundary" 256 "AddressingOrDataGeneralError" 36 "InternalFailurePreventingReq" 35 "PROMDidNotVerifyOnWrite" 34 "FLASHDidNotVerifyOnWrite" 33 "RAMDidNotVerifyOnWrite" 32 "EDCParaNotCorrectForDataStream" 31 "ProcessUnspecReqFromThisAddress" 23 "ProcessingEDCPGenerationReq" 22 "ProcessingBootLoadReq" 19 "ProcessingStatusReq" 18 "ProcessingWriteReq" 17 "ProcessingReadReq" 16 "ProcessingEraseReq" 2 "ProcessingForSomeoneElse" 1 "ErrorNotIdentified" 0 "NoError";
VAL_ 2564357886 Status 7 "Reserved" 6 "Reserved" 5 "OperationFailed" 4 "OperationCompleted" 3 "Reserved" 2 "Reserved" 1 "Busy" 0 "Proceed";
VAL_ 2564423422 KeyOrUserLevel 65535 "NoKeyAvailable" 0 "UseLongSeedOrKey";
VAL_ 2564423422 PointerExtension 0 "SPN_SPACE";
VAL_ 2564423422 Command 7 "EDCP_Generation" 6 "BootLoad" 5 "OperationFailed" 4 "OperationCompleted" 3 "StatusRequest" 2 "Write" 1 "Read" 0 "Erase";
VAL_ 2564423422 PointerType 1 "DirectedSpatialAddressing" 0 "DirectMemoryAddressing";
VAL_ 2564816638 HoldSignal 15 "Not available" 1 "Devices whose broadcast state ha" 0 "All devices";
VAL_ 2564816638 J1939Network3 3 "Don't care" 2 "Reserved" 1 "Start broadcast" 0 "Stop broadcast";
VAL_ 2564816638 J1939Network2 3 "Don't care" 2 "Reserved" 1 "Start broadcast" 0 "Stop broadcast";
VAL_ 2564816638 ISO9141 3 "Don't care" 2 "Reserved" 1 "Start broadcast" 0 "Stop broadcast";
VAL_ 2564816638 SAE_J1850 3 "Don't care" 2 "Reserved" 1 "Start broadcast" 0 "Stop broadcast";
VAL_ 2564816638 ManufacturerSpecificPort 3 "Don't care" 2 "Reserved" 1 "Start broadcast" 0 "Stop broadcast";
VAL_ 2564816638 CurrentDataLink 3 "Don't care" 2 "Reserved" 1 "Start broadcast" 0 "Stop broadcast";
VAL_ 2564816638 SAE_J1587 3 "Don't care" 2 "Reserved" 1 "Start broadcast" 0 "Stop broadcast";
VAL_ 2564816638 SAE_J1922 3 "Don't care" 2 "Reserved" 1 "Start broadcast" 0 "Stop broadcast";
VAL_ 2564816638 J1939Network1 3 "Don't care" 2 "Reserved" 1 "Start broadcast" 0 "Stop broadcast";
VAL_ 2564816638 SuspendSignal 15 "NotAvailable" 14 "ResumingNormalBroadcastPattern" 3 "TemporarySuspensionOfSomeMessages" 2 "TemporarySuspensionOfAllBroadcasts" 1 "IndefiniteSuspensionOfSomeMessages" 0 "IndefiniteSuspensionOfAllBroadcasts";
VAL_ 2566837502 FlashRedStopLamp 3 "Unavailable / Do Not Flash" 2 "Reserved" 1 "Fast Flash" 0 "Slow Flash";
VAL_ 2566837502 FlashProtectLamp 3 "Unavailable / Do Not Flash" 2 "Reserved" 1 "Fast Flash" 0 "Slow Flash";
VAL_ 2566837502 MalfunctionIndicatorLampStatus 3 "Not available" 2 "Reserved" 1 "Lamp on" 0 "Lamp off";
VAL_ 2566837502 RedStopLampState 3 "Not available" 2 "Reserved" 1 "Lamp on" 0 "Lamp off";
VAL_ 2566837502 AmberWarningLampStatus 3 "Not available" 2 "Reserved" 1 "Lamp on" 0 "Lamp off";
VAL_ 2566837502 ProtectLampStatus 3 "Not available" 2 "Reserved" 1 "Lamp on" 0 "Lamp off";
VAL_ 2566837502 FlashMalfuncIndicatorLamp 3 "Unavailable / Do Not Flash" 2 "Reserved" 1 "Fast Flash" 0 "Slow Flash";
VAL_ 2566837502 FlashAmberWarningLamp 3 "Unavailable / Do Not Flash" 2 "Reserved" 1 "Fast Flash" 0 "Slow Flash";
VAL_ 2566834942 FlashRedStopLamp 3 "Unavailable / Do Not Flash" 2 "Reserved" 1 "Fast Flash" 0 "Slow Flash";
VAL_ 2566834942 FlashProtectLamp 3 "Unavailable / Do Not Flash" 2 "Reserved" 1 "Fast Flash" 0 "Slow Flash";
VAL_ 2566834942 FlashMalfuncIndicatorLamp 3 "Unavailable / Do Not Flash" 2 "Reserved" 1 "Fast Flash" 0 "Slow Flash";
VAL_ 2566834942 FlashAmberWarningLamp 3 "Unavailable / Do Not Flash" 2 "Reserved" 1 "Fast Flash" 0 "Slow Flash";
VAL_ 2566834942 MalfunctionIndicatorLampStatus 3 "Not available" 2 "Reserved" 1 "Lamp on" 0 "Lamp off";
VAL_ 2566834942 AmberWarningLampStatus 3 "Not available" 2 "Reserved" 1 "Lamp on" 0 "Lamp off";
VAL_ 2566834942 RedStopLampState 3 "Not available" 2 "Reserved" 1 "Lamp on" 0 "Lamp off";
VAL_ 2566834942 ProtectLampStatus 3 "Not available" 2 "Reserved" 1 "Lamp on" 0 "Lamp off";
VAL_ 2566784254 GnrtorOverallPowerFactorLagging 3 "NotAvailable_NotInstalled" 2 "Error" 1 "Lagging" 0 "Leading";
VAL_ 2566781950 GnratorPhaseCPowerFactorLagging 3 "NotAvailable_NotInstalled" 2 "Error" 1 "Lagging" 0 "Leading";
VAL_ 2566782718 GnratorPhaseBPowerFactorLagging 3 "NotAvailable_NotInstalled" 2 "Error" 1 "Lagging" 0 "Leading";
VAL_ 2566783486 GnratorPhaseAPowerFactorLagging 3 "NotAvailable_NotInstalled" 2 "Error" 1 "Lagging" 0 "Leading";
VAL_ 2566776830 Bus1_UtilityInSync 3 "NotAvailable" 2 "Error" 1 "Sycnchronized" 0 "NotSynchronized";
VAL_ 2566776830 Bus1_UtilityVoltageMatch 3 "NotAvailable" 2 "Error" 1 "VoltagesMatch" 0 "VolatagesDoNotMatch";
VAL_ 2566776830 Bus1_UtilityFrequencyMatch 3 "NotAvailable" 2 "Error" 1 "FrequenciesMatch" 0 "FrequenciesDoNotMatch";
VAL_ 2566776830 Bus1_UtilityPhaseMatch 3 "NotAvailable" 2 "Error" 1 "PhasesMatch" 0 "PhasesDoNotMatch";
VAL_ 2566776830 Bus1_UtilityDeadBus 3 "NotAvailable" 2 "Error" 1 "BusIsDead" 0 "BusIsNotDead";
VAL_ 2566777086 Bus1_GeneratorInSync 3 "NotAvailable" 2 "Error" 1 "Sycnchronized" 0 "NotSynchronized";
VAL_ 2566777086 Bus1_GeneratorVoltageMatch 3 "NotAvailable" 2 "Error" 1 "VoltagesMatch" 0 "VolatagesDoNotMatch";
VAL_ 2566777086 Bus1_GeneratorFrequencyMatch 3 "NotAvailable" 2 "Error" 1 "FrequenciesMatch" 0 "FrequenciesDoNotMatch";
VAL_ 2566777086 Bus1_GeneratorPhaseMatch 3 "NotAvailable" 2 "Error" 1 "PhasesMatch" 0 "PhasesDoNotMatch";
VAL_ 2566777086 Bus1_GeneratorDeadBus 3 "NotAvailable" 2 "Error" 1 "BusIsDead" 0 "BusIsNotDead";
VAL_ 2566838526 IndustryGroup 6 "Reserved for SAE" 7 "Reserved for SAE" 5 "IndustrialProcessCtrlStationary" 4 "Marine" 3 "Construction" 2 "Agricultural and Forestry" 1 "On-Highway" 0 "Global";
VAL_ 2566838526 Function 127 "Reserved" 126 "Reserved" 125 "Reserved" 124 "Reserved" 123 "Reserved" 122 "Reserved" 121 "Reserved" 120 "Reserved" 119 "Reserved" 118 "Reserved" 117 "Reserved" 116 "Reserved" 115 "Reserved" 114 "Reserved" 113 "Reserved" 112 "Reserved" 111 "Reserved" 110 "Reserved" 109 "Reserved" 108 "Reserved" 107 "Reserved" 106 "Reserved" 105 "Reserved" 104 "Reserved" 103 "Reserved" 102 "Reserved" 101 "Reserved" 42 "Water Pump Control" 41 "Lighting - Operator Controls" 40 "Seat Control" 39 "Ignition Control Module" 38 "Tire Pressure Control" 37 "Cab Controller" 36 "Pneumatic - System Controller" 35 "Suspension - System Controller" 34 "Hydraulic Pump Controller" 33 "System Monitor" 32 "Headway Controller" 31 "Propulsion Battery Charger" 30 "Management Computer" 29 "Virtual Terminal (In Cab)" 28 "Off Vehicle Gateway" 27 "Power TakeOff (Secondary or Front)" 26 "Body Controller" 25 "Network Interconnect ECU" 24 "Vehicle Security" 23 "Vehicle Navigation" 22 "Aerodynamic Control" 21 "Cab Climate Control" 20 "Trip Recorder" 19 "Instrument Cluster" 18 "Suspension - Drive Axle" 17 "Suspension - Steer Axle" 16 "Steering Controller" 15 "Fuel System" 14 "Cruise Control" 13 "Retarder - Driveline" 12 "Retarder - Engine" 11 "Brakes - Drive Axle" 10 "Brakes - Steer Axle" 9 "Brakes - System Controller" 8 "Axle - Drive" 7 "Axle - Steering" 6 "Power TakeOff - (Main or Rear)" 5 "Shift Control/Console" 4 "Battery Pack Monitor" 3 "Transmission" 2 "Electric Propulsion Control" 1 "Auxiliary Power Unit (APU)" 0 "Engine" 100 "Reserved" 99 "Reserved" 98 "Reserved" 97 "Reserved" 96 "Reserved" 95 "Reserved" 94 "Reserved" 93 "Reserved" 92 "Reserved" 91 "Reserved" 90 "Reserved" 89 "Reserved" 88 "Reserved" 87 "Reserved" 86 "Reserved" 85 "Reserved" 84 "Reserved" 83 "Reserved" 82 "Reserved" 81 "Reserved" 80 "Reserved" 79 "Reserved" 78 "Reserved" 77 "Reserved" 76 "Reserved" 75 "Reserved" 74 "Reserved" 73 "Reserved" 72 "Coolant Valve Controller" 71 "Transfer Case Control" 70 "Auxiliary Regeneration Device" 69 "Engine Emission Aftertreatement System" 68 "Aftertreatment system gas measurement" 67 "Electrical System Controller" 66 "I/O Controller" 65 "Gas Flow Measurement" 64 "Endurance Braking" 63 "Engine Valve Controller" 62 "On-Board Diagnostic Unit" 61 "File Server/Printer" 60 "Cab Display" 59 "Starter" 58 "Fan Drive Control" 57 "Steering Column Unit" 56 "Communications Unit, Radio" 55 "Communications Unit, Satellite" 54 "Communications Unit, Cellular" 53 "Alternator/Charging System" 52 "Chassis Controller" 51 "Forward-Looking Collision Warning System" 50 "Auxiliary Heater" 49 "Clutch/Converter Control" 48 "Ramp Control" 47 "Information System Controller" 46 "Oil Sensor Unit" 45 "Vehicle Dynamic Stability Control" 44 "Exhaust Emission Control" 43 "Transmission Display";
VAL_ 2566838526 VehicleSystem 0 "Non-specific System" 127 "Not Available";
VAL_ 2566838526 ManufacturerCode 252 "Sensor-Technik Wiedemann GmbH" 251 "German Agricultural Society" 250 "Kuhn Group" 249 "Schaltbau GmbH" 233 "Yacht Monitoring Solutions Inc." 232 "TSD Integrated Controls" 1863 "Thomas G. Faria Co." 1862 "Sanshin" 1861 "Vector CANtech" 1860 "MMP" 1859 "Kvasar AB" 1858 "Litton" 1857 "Simrad" 1856 "Trimble" 1855 "Furuno USA" 1854 "Northstar Technologies" 1853 "Japan Radio Co." 1852 "Navionics" 1851 "Raymarine" 1850 "Teleflex" 222 "Generac Power Systems, Inc." 221 "SiE" 220 "Beede Electrical Instrument Company, Inc." 219 "Cat OEM Solutions" 218 "Gits Manufacturing Company" 217 "RM Michaelides Software & Elektronik GmbH" 216 "Paneltronics Inc." 215 "Aetna Engineering/Fireboy-Xintex" 214 "MC elettronica Srl" 213 "CNH Belgium N.V." 212 "Sure Power Industries, Inc." 211 "DNA Group" 210 "Iteris, Inc." 209 "Bell Equip. Co. SA (PTY) LTD" 208 "Drew Technologies, Inc." 207 "Otto Engineering" 206 "port GmbH" 205 "SmarTire Systems Inc" 204 "The Morey Corporation" 203 "MILtronik GmbH" 202 "Curtis Instruments, Inc." 201 "Disenos y Tecnologia S.A." 200 "MGM Brakes" 199 "Actia Corp." 198 "Mystic Valley Communications" 197 "Mechron Power Systems" 196 "LEMKEN GmbH & Co. KG" 195 "General Engine Products" 194 "TriMark Corporation" 193 "Jeppesen Marine" 192 "Floscan" 191 "XATA Corporation" 190 "Hella KGaA Hueck & Co." 189 "QUALCOMM" 188 "EMP Corp." 187 "Air-Weigh" 186 "Altronic, Inc." 185 "Beede Electrical Instrument Company" 184 "EIA Electronics" 183 "KDS Controls, Inc." 182 "Vehicle Systems Engineering B.V." 181 "Coretronics, Inc." 180 "Smart Power Systems" 179 "TeeJet Technologies Denmark" 178 "Siemens VDO Automotive AG" 177 "Diagnostic System Associates" 176 "Moritz Aerospace" 175 "Veris Technologies, Inc." 174 "AB Volvo Penta" 173 "Ryeso, Inc." 172 "Yanmar Marine USA" 171 "Wachendorff Elektronik GmbH & Co. KG" 170 "Computronics Corporation Ltd." 169 "Marlin Technologies Inc." 168 "Xantrex" 167 "JLG Industries Inc." 166 "Phoenix International" 165 "CPAC Systems AB" 164 "DaimlerChrysler Off-Highway" 163 "BRP Inc." 162 "Axiomatic Technologies" 161 "Offshore Systems (UK) Limited" 160 "Nido" 159 "NTech Industries Inc." 158 "Firestone Industrial Products Company" 157 "ISSPRO Inc." 156 "ITT Industries - Cannon" 155 "Vetronix Corporation" 154 "Westerbeke Corporation" 153 "Woodward, Industrial Controls Division" 152 "Elobau Elektrobauelemente GmbH & Co. KG" 151 "Raven Industries Inc. - Flow Controls Division" 150 "Fleetguard" 149 "Holset" 148 "Blue Water Data, Inc." 147 "Nautibus Electronic GmbH" 146 "Maxima Technologies" 145 "MurCal Controls" 144 "Mercury Marine" 143 "W. Gmeiner GmbH & Co." 142 "TRW Automotive (Commercial Steering Systems)" 141 "Thales Navigation Ltd." 140 "Lowrance Electronics, Inc." 139 "Caterpillar Trimble Control Technologies (CTCT), LLC" 138 "Georg Fritzmeier GmbH & Co. KG" 137 "Maretron" 136 "Komatsu Ltd." 135 "Airmar Technology Corporation" 134 "Iris Technology Ltd." 133 "Bucher Schoerling GmbH" 132 "Mulag-Fahrzeugwerk" 131 "ITT Industries" 130 "Nido - Universal Machines B.V." 129 "OMNEX Control Systems, Inc." 128 "Gerhard Duecker GmbH & Co. KG" 127 "Holland USA" 126 "Driver Tech" 125 "Nevada Automotive Test Center" 124 "Hydac Electronic" 123 "Basler Electric" 122 "FG Wilson (Engineering) Limited" 121 "HED (Hydro Electronic Devices, Inc.)" 120 "RDS Technology Ltd." 119 "IntegriNautics" 118 "Intron GmbH" 117 "HUSCO International" 116 "BEELINE Technologies" 115 "NACCO Materials Handling Group, Inc." 114 "EControls, Inc." 113 "Stress-Tek, Inc." 112 "MECALAC" 111 "Maschinenfabrik Bernhard Krone GmbH" 110 "EPIQ Sensor-Nite" 109 "TeeJet Technologies Denmark" 108 "WTK-Elecktronik GmbH" 107 "Grimme Landmaschinen GmbH & Co. KG" 106 "BAE Systems Controls, Inc." 105 "Kiepe Elektrik GmbH & Co. KG" 104 "Claas Selbstfahrende Erntemaschinen GmbH" 103 "Agrocom GmbH & Co. Agrarsystem KG" 102 "AGCO GmbH & Co." 101 "Sensoria" 100 "VDO Technik AG" 99 "International Transmissions Ltd (ITL)" 98 "Mueller-Elektronik GmbH & Co." 97 "Ag Leader Technology, Inc." 96 "Mech@tronic IT GmbH" 95 "Pacific Insight Electronics Corp." 94 "CNH Global N.V." 93 "Perkins Engines Company Ltd." 92 "Ag-Chem Equipment Co., Inc." 91 "BSG Bodensee Steuergeraete GmbH" 90 "Knorr-Bremse SfN GmbH" 89 "Kverneland Group, Electronics Division" 88 "Satloc Precision GPS" 87 "J.C. Bamford Excavators Ltd (JCB)" 86 "C.E. Niehoff & Company" 85 "Kohler Co." 84 "New Holland UK Limited" 83 "Eaton VORAD Technologies" 82 "Bobcat/Ingersoll-Rand" 81 "Fire Research Corp" 80 "Twin Disc, Inc." 79 "Daimler Benz AG - Engine Division (PBM)" 78 "Frank W. Murphy Manufacturing, Inc." 77 "Deere Power Systems Group" 76 "unused" 75 "Deere & Co. Agricultural Division" 74 "Eaton Axle-Brake Division" 73 "LeTourneau, Inc." 72 "Sisu Corporation" 71 "Vansco Electronics Ltd." 70 "Flex-Coil Limited" 69 "Trimble Navigation" 68 "Scania" 67 "Funk Manufacturing Company" 66 "John Deere Construction Equipment Division" 65 "MAN Nutzfahrzeuge AG" 64 "unused" 63 "ZF Industries Inc." 62 "Wabco" 61 "Volvo Truck Corp." 60 "Volvo Trucks North America Inc." 59 "VES Inc." 58 "SPX Corporation, OTC Division" 57 "Sauer-Danfoss Co." 56 "SAIC" 55 "Ryder System Inc." 54 "Meritor Wabco" 53 "Continental Automotive Systems US, Inc." 52 "Meritor Automotive, Inc." 51 "Robert Bosch GmbH" 50 "Robert Bosch Corp" 49 "RE America Inc." 48 "Pollak Alphabet" 47 "Phillips Semiconductor" 46 "Parasoft Computing Solutions" 45 "PACCAR" 44 "Nippondenso Co. Ltd." 43 "International Truck and Engine Corp. Vehicle Electronics" 42 "International Truck and Engine Corp. Engine Electronics" 41 "Motorola Inc." 40 "Motorola AIEG Inc." 39 "Microfirm Inc." 38 "Micro Processor Systems Inc." 37 "Mack Trucks Inc." 36 "Lucas Ltd." 35 "Kenworth Truck Co." 34 "Kelsey Hayes Co." 33 "John Deere" 32 "Jacobs Vehicle Systems" 31 "J Pollak Corp." 30 "Isuzu Motors Ltd." 29 "Hino Motors Ltd." 28 "Grote Ind. Inc." 27 "GMC" 26 "General Motors Corp., Service Technology Group" 25 "Daimler Trucks North America LLC" 24 "Ford Motor Co., Vehicle Controls" 23 "Ford Motor Co., Heavy Truck" 22 "Ford Motor Co., Electronic Concepts $ Systems" 21 "Echilin Inc., Midland Brake Inc." 20 "Eaton Ltd" 19 "Eaton Corp. Trucking Info Services" 18 "Eaton Corp, Transmission Division" 17 "Eaton Corp. Res & Dev" 16 "Eaton Corp." 15 "Dickey-John Corp." 14 "Detroit Diesel Corporation" 13 "Delco Electronics" 12 "Deere & Company, Precision Farming" 11 "Dearborn Group Inc." 10 "Cummins Engine Co." 9 "Chrysler Corp." 8 "Caterpillar Inc." 7 "Case Corp." 6 "Berifors Electronics AB" 5 "AMP Inc." 4 "Ametek-Dixson" 3 "Ametek, US Gauge Division" 2 "Allison Transmission, GMC" 1 "Allied Signal Inc." 0 "Reserved" 231 "Topcon Positioning Systems, Inc." 230 "Saucon Technologies" 229 "Garmin International Inc." 228 "ZF Marine Electronics" 227 "Lykketronic A/S" 226 "Monaco Coach Corporation" 225 "SKF" 224 "EMMI Network, S.L." 223 "Vaueo Retarder Co., Ltd." 263 "IMMI" 262 "HydraForce, Inc" 261 "Red Dot Corporation" 260 "Reichhardt GmbH" 259 "Jetter AG" 258 "ARAG" 257 "Honda Motor Co., Ltd" 256 "Tyco Electronics AMP" 255 "MEAS France" 254 "GE Sensing" 253 "Mobile Control Systems" 298 "Holley Performance" 297 "Zonar Systems Inc" 296 "micro dynamics GmbH" 295 "BEP Marine" 294 "Grayhill Inc." 293 "Spyder Controls Corp." 292 "IKUSI - Angel Iglesias S.A." 291 "Groeneveld Transport Efficiency BV" 290 "Kuebler GmbH" 289 "Watlow" 288 "Mitsubishi FUSO Truck & Bus Corp." 287 "NTech Industries, Inc" 286 "Coelmo srl" 285 "Sea Recovery Corp" 284 "Mobile Tech Chile" 283 "CWF Hamilton & Co Ltd" 282 "Medallion Instrumentation Systems" 281 "Precision Governors LLC" 311 "Patrick Power Products" 310 "TECNORD srl" 309 "Krauss-Maffei Wegmann GmbH & Co. KG" 308 "Cyntrx" 307 "MAS Technologies" 306 "Sleipner Motor AB" 305 "NovAtel Inc" 304 "EmpirBus AB" 303 "CTS Corporation" 302 "Nissin Kogyo Co., LTD" 301 "Parker Hannifin (UK) Ltd FDE group" 300 "Systron Donner Automotive" 299 "Rauch Landmaschinen GmbH" 280 "Leica Geosystems Pty Ltd" 279 "Geometris LP" 278 "Takata Electronics" 277 "LHP Telematics" 276 "Aqua-Hot Heating Systems" 275 "Navico Egersund AS" 274 "LTW Technology Co., LTD" 273 "Active Research Limited" 272 "Gross Mechanical Laboratories, Inc" 327 "Sonceboz SA" 326 "Akron Brass Company" 325 "ASM Automation Sensorik Messtechnik GmbH" 324 "Snap-on Diagnostics" 323 "Mobileye Vision Technologies Ltd." 322 "MICHENKA s.r.o." 321 "Ultra Electronics, Electrics" 320 "Miedema Landbouwwerktuigenfabriek B.V." 319 "Cadec Global" 318 "SAT Plan" 317 "Navtronics Bvba" 316 "ITT Flow Control" 315 "Icom Incorporated" 314 "CSM GmbH" 313 "Ilmor Engineering, Inc" 312 "Lectronix, Inc." 271 "Cole Hersee" 270 "Tennant" 269 "Saft America Inc., Space & Defense Division" 268 "Accurate Technologies" 267 "Red Lion Controls, Inc" 266 "International Thermal Research Ltd" 265 "MTS Sensor Technologie GmbH" 264 "Autolync" 248 "Cooper Standard Automotive Active Systems Group" 247 "ePULSE" 246 "Class 1, Inc" 245 "Capstan Ag Systems, Inc." 244 "Techno-Matic" 243 "eRide, Inc." 242 "Kokusandenki Co. Ltd" 241 "Schneider Automation SAS " 240 "Vanair Mfg" 239 "May & Scofield Ltd" 238 "ZF Friedrichshafen AG" 237 "Agtron Enterprises Inc" 236 "Norac Systems International Inc" 235 "SailorMade Marine Telemetry - Tetra Technology Ltd." 234 "Mondial electronic GmbH";
VAL_ 2566838526 VehicleSystem5 127 "Not Available" 0 "Ind. Process Control Stationary";
VAL_ 2566838526 VehicleSystem4 100 "Deck/Cargo/Fishing equip. sys" 90 "Environmental (HVAC) Systems" 80 "Instrumentation/General Systems" 70 "Communications Systems" 60 "Navigation Systems" 50 "Propulsion Systems" 40 "Steering Systems" 30 "Power Mgmt and lighting systems" 25 "Gateway" 20 "Safety Systems" 10 "System Tools" 127 "Not Available" 0 "Non-specific System";
VAL_ 2566838526 VehicleSystem3 8 "Grader" 7 "Four Wheel Drive Loader" 6 "Forklift" 5 "Excavator" 4 "Crawler" 3 "Backhoe" 2 "Articulated Dump Truck" 1 "Skid Steer Loader" 127 "Not Available" 0 "Non-specific System";
VAL_ 2566838526 VehicleSystem2 16 "Skidder" 15 "Earth Work" 14 "Special Crops" 13 "Powered Auxiliary Device" 12 "Farm Yard Operations" 11 "Transport/Trailer" 10 "Irrigation" 9 "Forage" 8 "Root Harvesters" 7 "Harvesters" 6 "Sprayers" 5 "Fertilizers" 4 "Planters/Seeders" 3 "Secondary Tillage" 2 "Tillage" 1 "Tractor" 127 "Not Available" 0 "Non-specific System";
VAL_ 2566838526 VehicleSystem1 2 "Trailer" 1 "Tractor" 127 "Not Available" 0 "Non-specific System";
VAL_ 2565799678 IndustryGroup 6 "Reserved for SAE" 7 "Reserved for SAE" 5 "IndustrialProcessCtrlStationary" 4 "Marine" 3 "Construction" 2 "Agricultural and Forestry" 1 "On-Highway" 0 "Global";
VAL_ 2565799678 Function 127 "Reserved" 126 "Reserved" 125 "Reserved" 124 "Reserved" 123 "Reserved" 122 "Reserved" 121 "Reserved" 120 "Reserved" 119 "Reserved" 118 "Reserved" 117 "Reserved" 116 "Reserved" 115 "Reserved" 114 "Reserved" 113 "Reserved" 112 "Reserved" 111 "Reserved" 110 "Reserved" 109 "Reserved" 108 "Reserved" 107 "Reserved" 106 "Reserved" 105 "Reserved" 104 "Reserved" 103 "Reserved" 102 "Reserved" 101 "Reserved" 42 "Water Pump Control" 41 "Lighting - Operator Controls" 40 "Seat Control" 39 "Ignition Control Module" 38 "Tire Pressure Control" 37 "Cab Controller" 36 "Pneumatic - System Controller" 35 "Suspension - System Controller" 34 "Hydraulic Pump Controller" 33 "System Monitor" 32 "Headway Controller" 31 "Propulsion Battery Charger" 30 "Management Computer" 29 "Virtual Terminal (In Cab)" 28 "Off Vehicle Gateway" 27 "Power TakeOff (Secondary or Front)" 26 "Body Controller" 25 "Network Interconnect ECU" 24 "Vehicle Security" 23 "Vehicle Navigation" 22 "Aerodynamic Control" 21 "Cab Climate Control" 20 "Trip Recorder" 19 "Instrument Cluster" 18 "Suspension - Drive Axle" 17 "Suspension - Steer Axle" 16 "Steering Controller" 15 "Fuel System" 14 "Cruise Control" 13 "Retarder - Driveline" 12 "Retarder - Engine" 11 "Brakes - Drive Axle" 10 "Brakes - Steer Axle" 9 "Brakes - System Controller" 8 "Axle - Drive" 7 "Axle - Steering" 6 "Power TakeOff - (Main or Rear)" 5 "Shift Control/Console" 4 "Battery Pack Monitor" 3 "Transmission" 2 "Electric Propulsion Control" 1 "Auxiliary Power Unit (APU)" 0 "Engine" 100 "Reserved" 99 "Reserved" 98 "Reserved" 97 "Reserved" 96 "Reserved" 95 "Reserved" 94 "Reserved" 93 "Reserved" 92 "Reserved" 91 "Reserved" 90 "Reserved" 89 "Reserved" 88 "Reserved" 87 "Reserved" 86 "Reserved" 85 "Reserved" 84 "Reserved" 83 "Reserved" 82 "Reserved" 81 "Reserved" 80 "Reserved" 79 "Reserved" 78 "Reserved" 77 "Reserved" 76 "Reserved" 75 "Reserved" 74 "Reserved" 73 "Reserved" 72 "Coolant Valve Controller" 71 "Transfer Case Control" 70 "Auxiliary Regeneration Device" 69 "Engine Emission Aftertreatement System" 68 "Aftertreatment system gas measurement" 67 "Electrical System Controller" 66 "I/O Controller" 65 "Gas Flow Measurement" 64 "Endurance Braking" 63 "Engine Valve Controller" 62 "On-Board Diagnostic Unit" 61 "File Server/Printer" 60 "Cab Display" 59 "Starter" 58 "Fan Drive Control" 57 "Steering Column Unit" 56 "Communications Unit, Radio" 55 "Communications Unit, Satellite" 54 "Communications Unit, Cellular" 53 "Alternator/Charging System" 52 "Chassis Controller" 51 "Forward-Looking Collision Warning System" 50 "Auxiliary Heater" 49 "Clutch/Converter Control" 48 "Ramp Control" 47 "Information System Controller" 46 "Oil Sensor Unit" 45 "Vehicle Dynamic Stability Control" 44 "Exhaust Emission Control" 43 "Transmission Display";
VAL_ 2565799678 ManufacturerCode 252 "Sensor-Technik Wiedemann GmbH" 251 "German Agricultural Society" 250 "Kuhn Group" 249 "Schaltbau GmbH" 233 "Yacht Monitoring Solutions Inc." 232 "TSD Integrated Controls" 1863 "Thomas G. Faria Co." 1862 "Sanshin" 1861 "Vector CANtech" 1860 "MMP" 1859 "Kvasar AB" 1858 "Litton" 1857 "Simrad" 1856 "Trimble" 1855 "Furuno USA" 1854 "Northstar Technologies" 1853 "Japan Radio Co." 1852 "Navionics" 1851 "Raymarine" 1850 "Teleflex" 222 "Generac Power Systems, Inc." 221 "SiE" 220 "Beede Electrical Instrument Company, Inc." 219 "Cat OEM Solutions" 218 "Gits Manufacturing Company" 217 "RM Michaelides Software & Elektronik GmbH" 216 "Paneltronics Inc." 215 "Aetna Engineering/Fireboy-Xintex" 214 "MC elettronica Srl" 213 "CNH Belgium N.V." 212 "Sure Power Industries, Inc." 211 "DNA Group" 210 "Iteris, Inc." 209 "Bell Equip. Co. SA (PTY) LTD" 208 "Drew Technologies, Inc." 207 "Otto Engineering" 206 "port GmbH" 205 "SmarTire Systems Inc" 204 "The Morey Corporation" 203 "MILtronik GmbH" 202 "Curtis Instruments, Inc." 201 "Disenos y Tecnologia S.A." 200 "MGM Brakes" 199 "Actia Corp." 198 "Mystic Valley Communications" 197 "Mechron Power Systems" 196 "LEMKEN GmbH & Co. KG" 195 "General Engine Products" 194 "TriMark Corporation" 193 "Jeppesen Marine" 192 "Floscan" 191 "XATA Corporation" 190 "Hella KGaA Hueck & Co." 189 "QUALCOMM" 188 "EMP Corp." 187 "Air-Weigh" 186 "Altronic, Inc." 185 "Beede Electrical Instrument Company" 184 "EIA Electronics" 183 "KDS Controls, Inc." 182 "Vehicle Systems Engineering B.V." 181 "Coretronics, Inc." 180 "Smart Power Systems" 179 "TeeJet Technologies Denmark" 178 "Siemens VDO Automotive AG" 177 "Diagnostic System Associates" 176 "Moritz Aerospace" 175 "Veris Technologies, Inc." 174 "AB Volvo Penta" 173 "Ryeso, Inc." 172 "Yanmar Marine USA" 171 "Wachendorff Elektronik GmbH & Co. KG" 170 "Computronics Corporation Ltd." 169 "Marlin Technologies Inc." 168 "Xantrex" 167 "JLG Industries Inc." 166 "Phoenix International" 165 "CPAC Systems AB" 164 "DaimlerChrysler Off-Highway" 163 "BRP Inc." 162 "Axiomatic Technologies" 161 "Offshore Systems (UK) Limited" 160 "Nido" 159 "NTech Industries Inc." 158 "Firestone Industrial Products Company" 157 "ISSPRO Inc." 156 "ITT Industries - Cannon" 155 "Vetronix Corporation" 154 "Westerbeke Corporation" 153 "Woodward, Industrial Controls Division" 152 "Elobau Elektrobauelemente GmbH & Co. KG" 151 "Raven Industries Inc. - Flow Controls Division" 150 "Fleetguard" 149 "Holset" 148 "Blue Water Data, Inc." 147 "Nautibus Electronic GmbH" 146 "Maxima Technologies" 145 "MurCal Controls" 144 "Mercury Marine" 143 "W. Gmeiner GmbH & Co." 142 "TRW Automotive (Commercial Steering Systems)" 141 "Thales Navigation Ltd." 140 "Lowrance Electronics, Inc." 139 "Caterpillar Trimble Control Technologies (CTCT), LLC" 138 "Georg Fritzmeier GmbH & Co. KG" 137 "Maretron" 136 "Komatsu Ltd." 135 "Airmar Technology Corporation" 134 "Iris Technology Ltd." 133 "Bucher Schoerling GmbH" 132 "Mulag-Fahrzeugwerk" 131 "ITT Industries" 130 "Nido - Universal Machines B.V." 129 "OMNEX Control Systems, Inc." 128 "Gerhard Duecker GmbH & Co. KG" 127 "Holland USA" 126 "Driver Tech" 125 "Nevada Automotive Test Center" 124 "Hydac Electronic" 123 "Basler Electric" 122 "FG Wilson (Engineering) Limited" 121 "HED (Hydro Electronic Devices, Inc.)" 120 "RDS Technology Ltd." 119 "IntegriNautics" 118 "Intron GmbH" 117 "HUSCO International" 116 "BEELINE Technologies" 115 "NACCO Materials Handling Group, Inc." 114 "EControls, Inc." 113 "Stress-Tek, Inc." 112 "MECALAC" 111 "Maschinenfabrik Bernhard Krone GmbH" 110 "EPIQ Sensor-Nite" 109 "TeeJet Technologies Denmark" 108 "WTK-Elecktronik GmbH" 107 "Grimme Landmaschinen GmbH & Co. KG" 106 "BAE Systems Controls, Inc." 105 "Kiepe Elektrik GmbH & Co. KG" 104 "Claas Selbstfahrende Erntemaschinen GmbH" 103 "Agrocom GmbH & Co. Agrarsystem KG" 102 "AGCO GmbH & Co." 101 "Sensoria" 100 "VDO Technik AG" 99 "International Transmissions Ltd (ITL)" 98 "Mueller-Elektronik GmbH & Co." 97 "Ag Leader Technology, Inc." 96 "Mech@tronic IT GmbH" 95 "Pacific Insight Electronics Corp." 94 "CNH Global N.V." 93 "Perkins Engines Company Ltd." 92 "Ag-Chem Equipment Co., Inc." 91 "BSG Bodensee Steuergeraete GmbH" 90 "Knorr-Bremse SfN GmbH" 89 "Kverneland Group, Electronics Division" 88 "Satloc Precision GPS" 87 "J.C. Bamford Excavators Ltd (JCB)" 86 "C.E. Niehoff & Company" 85 "Kohler Co." 84 "New Holland UK Limited" 83 "Eaton VORAD Technologies" 82 "Bobcat/Ingersoll-Rand" 81 "Fire Research Corp" 80 "Twin Disc, Inc." 79 "Daimler Benz AG - Engine Division (PBM)" 78 "Frank W. Murphy Manufacturing, Inc." 77 "Deere Power Systems Group" 76 "unused" 75 "Deere & Co. Agricultural Division" 74 "Eaton Axle-Brake Division" 73 "LeTourneau, Inc." 72 "Sisu Corporation" 71 "Vansco Electronics Ltd." 70 "Flex-Coil Limited" 69 "Trimble Navigation" 68 "Scania" 67 "Funk Manufacturing Company" 66 "John Deere Construction Equipment Division" 65 "MAN Nutzfahrzeuge AG" 64 "unused" 63 "ZF Industries Inc." 62 "Wabco" 61 "Volvo Truck Corp." 60 "Volvo Trucks North America Inc." 59 "VES Inc." 58 "SPX Corporation, OTC Division" 57 "Sauer-Danfoss Co." 56 "SAIC" 55 "Ryder System Inc." 54 "Meritor Wabco" 53 "Continental Automotive Systems US, Inc." 52 "Meritor Automotive, Inc." 51 "Robert Bosch GmbH" 50 "Robert Bosch Corp" 49 "RE America Inc." 48 "Pollak Alphabet" 47 "Phillips Semiconductor" 46 "Parasoft Computing Solutions" 45 "PACCAR" 44 "Nippondenso Co. Ltd." 43 "International Truck and Engine Corp. Vehicle Electronics" 42 "International Truck and Engine Corp. Engine Electronics" 41 "Motorola Inc." 40 "Motorola AIEG Inc." 39 "Microfirm Inc." 38 "Micro Processor Systems Inc." 37 "Mack Trucks Inc." 36 "Lucas Ltd." 35 "Kenworth Truck Co." 34 "Kelsey Hayes Co." 33 "John Deere" 32 "Jacobs Vehicle Systems" 31 "J Pollak Corp." 30 "Isuzu Motors Ltd." 29 "Hino Motors Ltd." 28 "Grote Ind. Inc." 27 "GMC" 26 "General Motors Corp., Service Technology Group" 25 "Daimler Trucks North America LLC" 24 "Ford Motor Co., Vehicle Controls" 23 "Ford Motor Co., Heavy Truck" 22 "Ford Motor Co., Electronic Concepts $ Systems" 21 "Echilin Inc., Midland Brake Inc." 20 "Eaton Ltd" 19 "Eaton Corp. Trucking Info Services" 18 "Eaton Corp, Transmission Division" 17 "Eaton Corp. Res & Dev" 16 "Eaton Corp." 15 "Dickey-John Corp." 14 "Detroit Diesel Corporation" 13 "Delco Electronics" 12 "Deere & Company, Precision Farming" 11 "Dearborn Group Inc." 10 "Cummins Engine Co." 9 "Chrysler Corp." 8 "Caterpillar Inc." 7 "Case Corp." 6 "Berifors Electronics AB" 5 "AMP Inc." 4 "Ametek-Dixson" 3 "Ametek, US Gauge Division" 2 "Allison Transmission, GMC" 1 "Allied Signal Inc." 0 "Reserved" 231 "Topcon Positioning Systems, Inc." 230 "Saucon Technologies" 229 "Garmin International Inc." 228 "ZF Marine Electronics" 227 "Lykketronic A/S" 226 "Monaco Coach Corporation" 225 "SKF" 224 "EMMI Network, S.L." 223 "Vaueo Retarder Co., Ltd." 263 "IMMI" 262 "HydraForce, Inc" 261 "Red Dot Corporation" 260 "Reichhardt GmbH" 259 "Jetter AG" 258 "ARAG" 257 "Honda Motor Co., Ltd" 256 "Tyco Electronics AMP" 255 "MEAS France" 254 "GE Sensing" 253 "Mobile Control Systems" 298 "Holley Performance" 297 "Zonar Systems Inc" 296 "micro dynamics GmbH" 295 "BEP Marine" 294 "Grayhill Inc." 293 "Spyder Controls Corp." 292 "IKUSI - Angel Iglesias S.A." 291 "Groeneveld Transport Efficiency BV" 290 "Kuebler GmbH" 289 "Watlow" 288 "Mitsubishi FUSO Truck & Bus Corp." 287 "NTech Industries, Inc" 286 "Coelmo srl" 285 "Sea Recovery Corp" 284 "Mobile Tech Chile" 283 "CWF Hamilton & Co Ltd" 282 "Medallion Instrumentation Systems" 281 "Precision Governors LLC" 311 "Patrick Power Products" 310 "TECNORD srl" 309 "Krauss-Maffei Wegmann GmbH & Co. KG" 308 "Cyntrx" 307 "MAS Technologies" 306 "Sleipner Motor AB" 305 "NovAtel Inc" 304 "EmpirBus AB" 303 "CTS Corporation" 302 "Nissin Kogyo Co., LTD" 301 "Parker Hannifin (UK) Ltd FDE group" 300 "Systron Donner Automotive" 299 "Rauch Landmaschinen GmbH" 280 "Leica Geosystems Pty Ltd" 279 "Geometris LP" 278 "Takata Electronics" 277 "LHP Telematics" 276 "Aqua-Hot Heating Systems" 275 "Navico Egersund AS" 274 "LTW Technology Co., LTD" 273 "Active Research Limited" 272 "Gross Mechanical Laboratories, Inc" 327 "Sonceboz SA" 326 "Akron Brass Company" 325 "ASM Automation Sensorik Messtechnik GmbH" 324 "Snap-on Diagnostics" 323 "Mobileye Vision Technologies Ltd." 322 "MICHENKA s.r.o." 321 "Ultra Electronics, Electrics" 320 "Miedema Landbouwwerktuigenfabriek B.V." 319 "Cadec Global" 318 "SAT Plan" 317 "Navtronics Bvba" 316 "ITT Flow Control" 315 "Icom Incorporated" 314 "CSM GmbH" 313 "Ilmor Engineering, Inc" 312 "Lectronix, Inc." 271 "Cole Hersee" 270 "Tennant" 269 "Saft America Inc., Space & Defense Division" 268 "Accurate Technologies" 267 "Red Lion Controls, Inc" 266 "International Thermal Research Ltd" 265 "MTS Sensor Technologie GmbH" 264 "Autolync" 248 "Cooper Standard Automotive Active Systems Group" 247 "ePULSE" 246 "Class 1, Inc" 245 "Capstan Ag Systems, Inc." 244 "Techno-Matic" 243 "eRide, Inc." 242 "Kokusandenki Co. Ltd" 241 "Schneider Automation SAS " 240 "Vanair Mfg" 239 "May & Scofield Ltd" 238 "ZF Friedrichshafen AG" 237 "Agtron Enterprises Inc" 236 "Norac Systems International Inc" 235 "SailorMade Marine Telemetry - Tetra Technology Ltd." 234 "Mondial electronic GmbH";
VAL_ 2565799678 VehicleSystem 0 "Non-specific System" 127 "Not Available";
VAL_ 2565799678 VehicleSystem5 127 "Not Available" 0 "Ind. Process Control Stationary";
VAL_ 2565799678 VehicleSystem4 100 "Deck/Cargo/Fishing equip. sys" 90 "Environmental (HVAC) Systems" 80 "Instrumentation/General Systems" 70 "Communications Systems" 60 "Navigation Systems" 50 "Propulsion Systems" 40 "Steering Systems" 30 "Power Mgmt and lighting systems" 25 "Gateway" 20 "Safety Systems" 10 "System Tools" 127 "Not Available" 0 "Non-specific System";
VAL_ 2565799678 VehicleSystem3 8 "Grader" 7 "Four Wheel Drive Loader" 6 "Forklift" 5 "Excavator" 4 "Crawler" 3 "Backhoe" 2 "Articulated Dump Truck" 1 "Skid Steer Loader" 127 "Not Available" 0 "Non-specific System";
VAL_ 2565799678 VehicleSystem2 16 "Skidder" 15 "Earth Work" 14 "Special Crops" 13 "Powered Auxiliary Device" 12 "Farm Yard Operations" 11 "Transport/Trailer" 10 "Irrigation" 9 "Forage" 8 "Root Harvesters" 7 "Harvesters" 6 "Sprayers" 5 "Fertilizers" 4 "Planters/Seeders" 3 "Secondary Tillage" 2 "Tillage" 1 "Tractor" 127 "Not Available" 0 "Non-specific System";
VAL_ 2565799678 VehicleSystem1 2 "Trailer" 1 "Tractor" 127 "Not Available" 0 "Non-specific System";
VAL_ 2632777470 PGNumber 255 "NotAvailable";
VAL_ 2632777470 ControlByte 24 "EAbort" 23 "EEoMACK" 22 "EDPO" 21 "ECTS" 20 "ERTS" 255 "Abort" 32 "BAM" 19 "EoMA" 17 "CTS" 16 "RTS";
VAL_ 2563374846 UseTransferMode 3 "NA" 2 "Undefined" 1 "Yes" 0 "No";
VAL_ 2499635966 AxleGroupLocation 3 "TrailerFAxleGroup" 2 "TrailerEAxleGroup" 1 "SteerAxleGroup" 0 "Reserved";
VAL_ 2633853438 AxleGroupLocation 3 "TrailerFAxleGroup" 2 "TrailerEAxleGroup" 1 "SteerAxleGroup" 0 "Reserved";
VAL_ 2432520702 AftrcoolerCoolantThermostatMode 3 "DontCare_Reserved" 2 "Reserved" 1 "PosCtrlMode" 0 "TempCtrlMode";
VAL_ 2566745086 AddtnlTrlrAxlGrpWeightAvailable 3 "NotAvailable_NotApplicable" 2 "Reserved" 1 "AddtonalTrailerAxleGroupPresent" 0 "AddtnlTrilerAxleGroupNotPresent";
VAL_ 2566745086 TrilerHAxleGroupWeightAvailable 3 "NotAvailable_NotApplicable" 2 "Reserved" 1 "TrailerHAxleGroupPresent" 0 "TrailerHAxleGroupNotPresent";
VAL_ 2566745086 TrilerGAxleGroupWeightAvailable 3 "NotAvailable_NotApplicable" 2 "Reserved" 1 "TrailerGAxleGroupPresent" 0 "TrailerGAxleGroupNotPresent";
VAL_ 2566745086 TrilerFAxleGroupWeightAvailable 3 "NotAvailable_NotApplicable" 2 "Reserved" 1 "TrailerFAxleGroupPresent" 0 "TrailerFAxleGroupNotPresent";
VAL_ 2566745086 TrilerEAxleGroupWeightAvailable 3 "NotAvailable_NotApplicable" 2 "Reserved" 1 "TrailerEAxleGroupPresent" 0 "TrailerEAxleGroupNotPresent";
VAL_ 2566745086 TrilerDAxleGroupWeightAvailable 3 "NotAvailable_NotApplicable" 2 "Reserved" 1 "TrailerDAxleGroupPresent" 0 "TrailerDAxleGroupNotPresent";
VAL_ 2566745086 TrilerCAxleGroupWeightAvailable 3 "NotAvailable_NotApplicable" 2 "Reserved" 1 "TrailerCAxleGroupPresent" 0 "TrailerCAxleGroupNotPresent";
VAL_ 2566745086 TrilerBAxleGroupWeightAvailable 3 "NotAvailable_NotApplicable" 2 "Reserved" 1 "TrailerBAxleGroupPresent" 0 "TrailerBAxleGroupNotPresent";
VAL_ 2566745086 TrilerAAxleGroupWeightAvailable 3 "NotAvailable_NotApplicable" 2 "Reserved" 1 "TrailerAAxleGroupPresent" 0 "TrailerAAxleGroupNotPresent";
VAL_ 2566745086 AddtnlTrctrAxlGrpWightAvailable 3 "NotAvailable_NotApplicable" 2 "Reserved" 1 "AddtonalTractorAxleGroupPresent" 0 "AddtnlTrctorAxleGroupNotPresent";
VAL_ 2566745086 TagAxleGroupWeightAvailable 3 "NotAvailable_NotApplicable" 2 "Reserved" 1 "TagAxleGroupPresent" 0 "TagAxleGroupNotPresent";
VAL_ 2566745086 DriveAxleGroupWeightAvailable 3 "NotAvailable_NotApplicable" 2 "Reserved" 1 "DriveAxleGroupPresent" 0 "DriveAxleGroupNotPresent";
VAL_ 2566745086 LiftAxleGroupWeightAvailable 3 "NotAvailable_NotApplicable" 2 "Reserved" 1 "LiftAxleGroupPresent" 0 "LiftAxleGroupNotPresent";
VAL_ 2566745086 SteerAxleGroupWeightAvailable 3 "NotAvailable_NotApplicable" 2 "Reserved" 1 "SteerAxleGroupPresent" 0 "SteerAxleGroupNotPresent";
VAL_ 2566739198 FlashRedStopLamp 3 "Unavailable / Do Not Flash" 2 "Reserved" 1 "Fast Flash" 0 "Slow Flash";
VAL_ 2566739198 FlashProtectLamp 3 "Unavailable / Do Not Flash" 2 "Reserved" 1 "Fast Flash" 0 "Slow Flash";
VAL_ 2566739198 FlashMalfuncIndicatorLamp 3 "Unavailable / Do Not Flash" 2 "Reserved" 1 "Fast Flash" 0 "Slow Flash";
VAL_ 2566739198 FlashAmberWarningLamp 3 "Unavailable / Do Not Flash" 2 "Reserved" 1 "Fast Flash" 0 "Slow Flash";
VAL_ 2566739198 MalfunctionIndicatorLampStatus 3 "Not available" 2 "Reserved" 1 "Lamp on" 0 "Lamp off";
VAL_ 2566739198 AmberWarningLampStatus 3 "Not available" 2 "Reserved" 1 "Lamp on" 0 "Lamp off";
VAL_ 2566739198 RedStopLampState 3 "Not available" 2 "Reserved" 1 "Lamp on" 0 "Lamp off";
VAL_ 2566739198 ProtectLampStatus 3 "Not available" 2 "Reserved" 1 "Lamp on" 0 "Lamp off";
VAL_ 2566739454 FlashRedStopLamp 3 "Unavailable / Do Not Flash" 2 "Reserved" 1 "Fast Flash" 0 "Slow Flash";
VAL_ 2566739454 FlashProtectLamp 3 "Unavailable / Do Not Flash" 2 "Reserved" 1 "Fast Flash" 0 "Slow Flash";
VAL_ 2566739454 FlashMalfuncIndicatorLamp 3 "Unavailable / Do Not Flash" 2 "Reserved" 1 "Fast Flash" 0 "Slow Flash";
VAL_ 2566739454 FlashAmberWarningLamp 3 "Unavailable / Do Not Flash" 2 "Reserved" 1 "Fast Flash" 0 "Slow Flash";
VAL_ 2566739454 MalfunctionIndicatorLampStatus 3 "Not available" 2 "Reserved" 1 "Lamp on" 0 "Lamp off";
VAL_ 2566739454 AmberWarningLampStatus 3 "Not available" 2 "Reserved" 1 "Lamp on" 0 "Lamp off";
VAL_ 2566739454 RedStopLampState 3 "Not available" 2 "Reserved" 1 "Lamp on" 0 "Lamp off";
VAL_ 2566739454 ProtectLampStatus 3 "Not available" 2 "Reserved" 1 "Lamp on" 0 "Lamp off";
VAL_ 2566739710 FlashRedStopLamp 3 "Unavailable / Do Not Flash" 2 "Reserved" 1 "Fast Flash" 0 "Slow Flash";
VAL_ 2566739710 FlashProtectLamp 3 "Unavailable / Do Not Flash" 2 "Reserved" 1 "Fast Flash" 0 "Slow Flash";
VAL_ 2566739710 FlashMalfuncIndicatorLamp 3 "Unavailable / Do Not Flash" 2 "Reserved" 1 "Fast Flash" 0 "Slow Flash";
VAL_ 2566739710 FlashAmberWarningLamp 3 "Unavailable / Do Not Flash" 2 "Reserved" 1 "Fast Flash" 0 "Slow Flash";
VAL_ 2566739710 MalfunctionIndicatorLampStatus 3 "Not available" 2 "Reserved" 1 "Lamp on" 0 "Lamp off";
VAL_ 2566739710 AmberWarningLampStatus 3 "Not available" 2 "Reserved" 1 "Lamp on" 0 "Lamp off";
VAL_ 2566739710 RedStopLampState 3 "Not available" 2 "Reserved" 1 "Lamp on" 0 "Lamp off";
VAL_ 2566739710 ProtectLampStatus 3 "Not available" 2 "Reserved" 1 "Lamp on" 0 "Lamp off";
VAL_ 2566739966 FlashRedStopLamp 3 "Unavailable / Do Not Flash" 2 "Reserved" 1 "Fast Flash" 0 "Slow Flash";
VAL_ 2566739966 FlashProtectLamp 3 "Unavailable / Do Not Flash" 2 "Reserved" 1 "Fast Flash" 0 "Slow Flash";
VAL_ 2566739966 FlashMalfuncIndicatorLamp 3 "Unavailable / Do Not Flash" 2 "Reserved" 1 "Fast Flash" 0 "Slow Flash";
VAL_ 2566739966 FlashAmberWarningLamp 3 "Unavailable / Do Not Flash" 2 "Reserved" 1 "Fast Flash" 0 "Slow Flash";
VAL_ 2566739966 MalfunctionIndicatorLampStatus 3 "Not available" 2 "Reserved" 1 "Lamp on" 0 "Lamp off";
VAL_ 2566739966 AmberWarningLampStatus 3 "Not available" 2 "Reserved" 1 "Lamp on" 0 "Lamp off";
VAL_ 2566739966 RedStopLampState 3 "Not available" 2 "Reserved" 1 "Lamp on" 0 "Lamp off";
VAL_ 2566739966 ProtectLampStatus 3 "Not available" 2 "Reserved" 1 "Lamp on" 0 "Lamp off";
VAL_ 2566740222 FlashRedStopLamp 3 "Unavailable / Do Not Flash" 2 "Reserved" 1 "Fast Flash" 0 "Slow Flash";
VAL_ 2566740222 FlashProtectLamp 3 "Unavailable / Do Not Flash" 2 "Reserved" 1 "Fast Flash" 0 "Slow Flash";
VAL_ 2566740222 FlashMalfuncIndicatorLamp 3 "Unavailable / Do Not Flash" 2 "Reserved" 1 "Fast Flash" 0 "Slow Flash";
VAL_ 2566740222 FlashAmberWarningLamp 3 "Unavailable / Do Not Flash" 2 "Reserved" 1 "Fast Flash" 0 "Slow Flash";
VAL_ 2566740222 MalfunctionIndicatorLampStatus 3 "Not available" 2 "Reserved" 1 "Lamp on" 0 "Lamp off";
VAL_ 2566740222 AmberWarningLampStatus 3 "Not available" 2 "Reserved" 1 "Lamp on" 0 "Lamp off";
VAL_ 2566740222 RedStopLampState 3 "Not available" 2 "Reserved" 1 "Lamp on" 0 "Lamp off";
VAL_ 2566740222 ProtectLampStatus 3 "Not available" 2 "Reserved" 1 "Lamp on" 0 "Lamp off";
VAL_ 2566740478 FlashRedStopLamp 3 "Unavailable / Do Not Flash" 2 "Reserved" 1 "Fast Flash" 0 "Slow Flash";
VAL_ 2566740478 FlashProtectLamp 3 "Unavailable / Do Not Flash" 2 "Reserved" 1 "Fast Flash" 0 "Slow Flash";
VAL_ 2566740478 FlashMalfuncIndicatorLamp 3 "Unavailable / Do Not Flash" 2 "Reserved" 1 "Fast Flash" 0 "Slow Flash";
VAL_ 2566740478 FlashAmberWarningLamp 3 "Unavailable / Do Not Flash" 2 "Reserved" 1 "Fast Flash" 0 "Slow Flash";
VAL_ 2566740478 MalfunctionIndicatorLampStatus 3 "Not available" 2 "Reserved" 1 "Lamp on" 0 "Lamp off";
VAL_ 2566740478 AmberWarningLampStatus 3 "Not available" 2 "Reserved" 1 "Lamp on" 0 "Lamp off";
VAL_ 2566740478 RedStopLampState 3 "Not available" 2 "Reserved" 1 "Lamp on" 0 "Lamp off";
VAL_ 2566740478 ProtectLampStatus 3 "Not available" 2 "Reserved" 1 "Lamp on" 0 "Lamp off";
VAL_ 2566740734 FlashRedStopLamp 3 "Unavailable / Do Not Flash" 2 "Reserved" 1 "Fast Flash" 0 "Slow Flash";
VAL_ 2566740734 FlashProtectLamp 3 "Unavailable / Do Not Flash" 2 "Reserved" 1 "Fast Flash" 0 "Slow Flash";
VAL_ 2566740734 FlashMalfuncIndicatorLamp 3 "Unavailable / Do Not Flash" 2 "Reserved" 1 "Fast Flash" 0 "Slow Flash";
VAL_ 2566740734 FlashAmberWarningLamp 3 "Unavailable / Do Not Flash" 2 "Reserved" 1 "Fast Flash" 0 "Slow Flash";
VAL_ 2566740734 MalfunctionIndicatorLampStatus 3 "Not available" 2 "Reserved" 1 "Lamp on" 0 "Lamp off";
VAL_ 2566740734 AmberWarningLampStatus 3 "Not available" 2 "Reserved" 1 "Lamp on" 0 "Lamp off";
VAL_ 2566740734 RedStopLampState 3 "Not available" 2 "Reserved" 1 "Lamp on" 0 "Lamp off";
VAL_ 2566740734 ProtectLampStatus 3 "Not available" 2 "Reserved" 1 "Lamp on" 0 "Lamp off";
VAL_ 2566740990 FlashRedStopLamp 3 "Unavailable / Do Not Flash" 2 "Reserved" 1 "Fast Flash" 0 "Slow Flash";
VAL_ 2566740990 FlashProtectLamp 3 "Unavailable / Do Not Flash" 2 "Reserved" 1 "Fast Flash" 0 "Slow Flash";
VAL_ 2566740990 FlashMalfuncIndicatorLamp 3 "Unavailable / Do Not Flash" 2 "Reserved" 1 "Fast Flash" 0 "Slow Flash";
VAL_ 2566740990 FlashAmberWarningLamp 3 "Unavailable / Do Not Flash" 2 "Reserved" 1 "Fast Flash" 0 "Slow Flash";
VAL_ 2566740990 MalfunctionIndicatorLampStatus 3 "Not available" 2 "Reserved" 1 "Lamp on" 0 "Lamp off";
VAL_ 2566740990 AmberWarningLampStatus 3 "Not available" 2 "Reserved" 1 "Lamp on" 0 "Lamp off";
VAL_ 2566740990 RedStopLampState 3 "Not available" 2 "Reserved" 1 "Lamp on" 0 "Lamp off";
VAL_ 2566740990 ProtectLampStatus 3 "Not available" 2 "Reserved" 1 "Lamp on" 0 "Lamp off";
VAL_ 2566741246 FlashRedStopLamp 3 "Unavailable / Do Not Flash" 2 "Reserved" 1 "Fast Flash" 0 "Slow Flash";
VAL_ 2566741246 FlashProtectLamp 3 "Unavailable / Do Not Flash" 2 "Reserved" 1 "Fast Flash" 0 "Slow Flash";
VAL_ 2566741246 FlashMalfuncIndicatorLamp 3 "Unavailable / Do Not Flash" 2 "Reserved" 1 "Fast Flash" 0 "Slow Flash";
VAL_ 2566741246 FlashAmberWarningLamp 3 "Unavailable / Do Not Flash" 2 "Reserved" 1 "Fast Flash" 0 "Slow Flash";
VAL_ 2566741246 MalfunctionIndicatorLampStatus 3 "Not available" 2 "Reserved" 1 "Lamp on" 0 "Lamp off";
VAL_ 2566741246 AmberWarningLampStatus 3 "Not available" 2 "Reserved" 1 "Lamp on" 0 "Lamp off";
VAL_ 2566741246 RedStopLampState 3 "Not available" 2 "Reserved" 1 "Lamp on" 0 "Lamp off";
VAL_ 2566741246 ProtectLampStatus 3 "Not available" 2 "Reserved" 1 "Lamp on" 0 "Lamp off";
VAL_ 2566741502 FlashRedStopLamp 3 "Unavailable / Do Not Flash" 2 "Reserved" 1 "Fast Flash" 0 "Slow Flash";
VAL_ 2566741502 FlashProtectLamp 3 "Unavailable / Do Not Flash" 2 "Reserved" 1 "Fast Flash" 0 "Slow Flash";
VAL_ 2566741502 FlashMalfuncIndicatorLamp 3 "Unavailable / Do Not Flash" 2 "Reserved" 1 "Fast Flash" 0 "Slow Flash";
VAL_ 2566741502 FlashAmberWarningLamp 3 "Unavailable / Do Not Flash" 2 "Reserved" 1 "Fast Flash" 0 "Slow Flash";
VAL_ 2566741502 MalfunctionIndicatorLampStatus 3 "Not available" 2 "Reserved" 1 "Lamp on" 0 "Lamp off";
VAL_ 2566741502 AmberWarningLampStatus 3 "Not available" 2 "Reserved" 1 "Lamp on" 0 "Lamp off";
VAL_ 2566741502 RedStopLampState 3 "Not available" 2 "Reserved" 1 "Lamp on" 0 "Lamp off";
VAL_ 2566741502 ProtectLampStatus 3 "Not available" 2 "Reserved" 1 "Lamp on" 0 "Lamp off";
VAL_ 2566741758 FlashRedStopLamp 3 "Unavailable / Do Not Flash" 2 "Reserved" 1 "Fast Flash" 0 "Slow Flash";
VAL_ 2566741758 FlashProtectLamp 3 "Unavailable / Do Not Flash" 2 "Reserved" 1 "Fast Flash" 0 "Slow Flash";
VAL_ 2566741758 FlashMalfuncIndicatorLamp 3 "Unavailable / Do Not Flash" 2 "Reserved" 1 "Fast Flash" 0 "Slow Flash";
VAL_ 2566741758 FlashAmberWarningLamp 3 "Unavailable / Do Not Flash" 2 "Reserved" 1 "Fast Flash" 0 "Slow Flash";
VAL_ 2566741758 MalfunctionIndicatorLampStatus 3 "Not available" 2 "Reserved" 1 "Lamp on" 0 "Lamp off";
VAL_ 2566741758 AmberWarningLampStatus 3 "Not available" 2 "Reserved" 1 "Lamp on" 0 "Lamp off";
VAL_ 2566741758 RedStopLampState 3 "Not available" 2 "Reserved" 1 "Lamp on" 0 "Lamp off";
VAL_ 2566741758 ProtectLampStatus 3 "Not available" 2 "Reserved" 1 "Lamp on" 0 "Lamp off";
VAL_ 2566742014 FlashRedStopLamp 3 "Unavailable / Do Not Flash" 2 "Reserved" 1 "Fast Flash" 0 "Slow Flash";
VAL_ 2566742014 FlashProtectLamp 3 "Unavailable / Do Not Flash" 2 "Reserved" 1 "Fast Flash" 0 "Slow Flash";
VAL_ 2566742014 FlashMalfuncIndicatorLamp 3 "Unavailable / Do Not Flash" 2 "Reserved" 1 "Fast Flash" 0 "Slow Flash";
VAL_ 2566742014 FlashAmberWarningLamp 3 "Unavailable / Do Not Flash" 2 "Reserved" 1 "Fast Flash" 0 "Slow Flash";
VAL_ 2566742014 MalfunctionIndicatorLampStatus 3 "Not available" 2 "Reserved" 1 "Lamp on" 0 "Lamp off";
VAL_ 2566742014 AmberWarningLampStatus 3 "Not available" 2 "Reserved" 1 "Lamp on" 0 "Lamp off";
VAL_ 2566742014 RedStopLampState 3 "Not available" 2 "Reserved" 1 "Lamp on" 0 "Lamp off";
VAL_ 2566742014 ProtectLampStatus 3 "Not available" 2 "Reserved" 1 "Lamp on" 0 "Lamp off";
VAL_ 2560622334 FlashRedStopLamp 3 "Unavailable / Do Not Flash" 2 "Reserved" 1 "Fast Flash" 0 "Slow Flash";
VAL_ 2560622334 FlashProtectLamp 3 "Unavailable / Do Not Flash" 2 "Reserved" 1 "Fast Flash" 0 "Slow Flash";
VAL_ 2560622334 FlashMalfuncIndicatorLamp 3 "Unavailable / Do Not Flash" 2 "Reserved" 1 "Fast Flash" 0 "Slow Flash";
VAL_ 2560622334 FlashAmberWarningLamp 3 "Unavailable / Do Not Flash" 2 "Reserved" 1 "Fast Flash" 0 "Slow Flash";
VAL_ 2560622334 MalfunctionIndicatorLampStatus 3 "Not available" 2 "Reserved" 1 "Lamp on" 0 "Lamp off";
VAL_ 2560622334 AmberWarningLampStatus 3 "Not available" 2 "Reserved" 1 "Lamp on" 0 "Lamp off";
VAL_ 2560622334 RedStopLampState 3 "Not available" 2 "Reserved" 1 "Lamp on" 0 "Lamp off";
VAL_ 2560622334 ProtectLampStatus 3 "Not available" 2 "Reserved" 1 "Lamp on" 0 "Lamp off";
VAL_ 2566744062 ZeroNetVehicleWeightChange 3 "NotAvailable_NotApplicable" 2 "Reserved" 1 "ZeroNetVehicleWeightChange" 0 "NChangeToNetVehicleWeightChange";
VAL_ 2566750462 FlashRedStopLamp 3 "Unavailable / Do Not Flash" 2 "Reserved" 1 "Fast Flash" 0 "Slow Flash";
VAL_ 2566750462 FlashProtectLamp 3 "Unavailable / Do Not Flash" 2 "Reserved" 1 "Fast Flash" 0 "Slow Flash";
VAL_ 2566750462 FlashMalfuncIndicatorLamp 3 "Unavailable / Do Not Flash" 2 "Reserved" 1 "Fast Flash" 0 "Slow Flash";
VAL_ 2566750462 FlashAmberWarningLamp 3 "Unavailable / Do Not Flash" 2 "Reserved" 1 "Fast Flash" 0 "Slow Flash";
VAL_ 2566750462 MalfunctionIndicatorLampStatus 3 "Not available" 2 "Reserved" 1 "Lamp on" 0 "Lamp off";
VAL_ 2566750462 AmberWarningLampStatus 3 "Not available" 2 "Reserved" 1 "Lamp on" 0 "Lamp off";
VAL_ 2566750462 RedStopLampState 3 "Not available" 2 "Reserved" 1 "Lamp on" 0 "Lamp off";
VAL_ 2566750462 ProtectLampStatus 3 "Not available" 2 "Reserved" 1 "Lamp on" 0 "Lamp off";
VAL_ 2566750974 FlashRedStopLamp 3 "Unavailable / Do Not Flash" 2 "Reserved" 1 "Fast Flash" 0 "Slow Flash";
VAL_ 2566750974 FlashProtectLamp 3 "Unavailable / Do Not Flash" 2 "Reserved" 1 "Fast Flash" 0 "Slow Flash";
VAL_ 2566750974 FlashMalfuncIndicatorLamp 3 "Unavailable / Do Not Flash" 2 "Reserved" 1 "Fast Flash" 0 "Slow Flash";
VAL_ 2566750974 FlashAmberWarningLamp 3 "Unavailable / Do Not Flash" 2 "Reserved" 1 "Fast Flash" 0 "Slow Flash";
VAL_ 2566750974 MalfunctionIndicatorLampStatus 3 "Not available" 2 "Reserved" 1 "Lamp on" 0 "Lamp off";
VAL_ 2566750974 AmberWarningLampStatus 3 "Not available" 2 "Reserved" 1 "Lamp on" 0 "Lamp off";
VAL_ 2566750974 RedStopLampState 3 "Not available" 2 "Reserved" 1 "Lamp on" 0 "Lamp off";
VAL_ 2566750974 ProtectLampStatus 3 "Not available" 2 "Reserved" 1 "Lamp on" 0 "Lamp off";
VAL_ 2566754558 AETCDataCollectionStandard 15 "NotAvailable" 1 "1101NotDefined" 0 "SAEJ1995";
VAL_ 2566749950 RightHeadlampLightDistribution 15 "NotAvailable" 8 "1110Reserved" 7 "DffrntLghtDstrbtnsNtAvlblNAFSDs" 6 "LghtDstrbtnFlrMdlIsDmgdCrrntPsM" 5 "LghtDstrbtnFlSfPsMdlIsDmgdCrrnt" 4 "LghtDstrbtnAdvrsWthrAdvrsWthrLg" 3 "LghtDstrbtnHghBmHghBmDstrbtnOfT" 2 "LghtDstrbtnMtrwyTskOfMtrwyLghtI" 1 "LghtDstrbtnCntryCntryLghtIsMstl" 0 "LghtDstrbtnTwnBscLghtDstrbtnFrT";
VAL_ 2566749950 LeftHeadlampLightDistribution 15 "NotAvailable" 8 "1110Reserved" 7 "DffrntLghtDstrbtnsNtAvlblNAFSDs" 6 "LghtDstrbtnFlrMdlIsDmgdCrrntPsM" 5 "LghtDstrbtnFlSfPsMdlIsDmgdCrrnt" 4 "LghtDstrbtnAdvrsWthrAdvrsWthrLg" 3 "LghtDstrbtnHghBmHghBmDstrbtnOfT" 2 "LghtDstrbtnMtrwyTskOfMtrwyLghtI" 1 "LghtDstrbtnCntryCntryLghtIsMstl" 0 "LghtDstrbtnTwnBscLghtDstrbtnFrT";
VAL_ 2566749950 RghtHeadlampDynamicBendingLight 7 "NotAvailable" 4 "110Reserved" 3 "DynmcBndngLghtFlrBndngLghtDsNtW" 2 "DynmcBndngLghtFlSfPsBndngLghtIs" 1 "DynmcBndngLghtIsWrkngPrprlyNrml" 0 "DynmcBndngLghtDctvtdThrIsNPrblm";
VAL_ 2566749950 LeftHeadlampDynamicBendingLight 7 "NotAvailable" 4 "110Reserved" 3 "DynmcBndngLghtFlrBndngLghtDsNtW" 2 "DynmcBndngLghtFlSfPsBndngLghtIs" 1 "DynmcBndngLghtIsWrkngPrprlyNrml" 0 "DynmcBndngLghtDctvtdThrIsNPrblm";
VAL_ 2566838782 AuxI_O16 3 "NotAvailable" 2 "Error" 1 "AuxChannelOn" 0 "AuxChannelOff";
VAL_ 2566838782 AuxI_O15 3 "NotAvailable" 2 "Error" 1 "AuxChannelOn" 0 "AuxChannelOff";
VAL_ 2566838782 AuxI_O14 3 "NotAvailable" 2 "Error" 1 "AuxChannelOn" 0 "AuxChannelOff";
VAL_ 2566838782 AuxI_O13 3 "NotAvailable" 2 "Error" 1 "AuxChannelOn" 0 "AuxChannelOff";
VAL_ 2566838782 AuxI_O12 3 "NotAvailable" 2 "Error" 1 "AuxChannelOn" 0 "AuxChannelOff";
VAL_ 2566838782 AuxI_O11 3 "NotAvailable" 2 "Error" 1 "AuxChannelOn" 0 "AuxChannelOff";
VAL_ 2566838782 AuxI_O10 3 "NotAvailable" 2 "Error" 1 "AuxChannelOn" 0 "AuxChannelOff";
VAL_ 2566838782 AuxI_O09 3 "NotAvailable" 2 "Error" 1 "AuxChannelOn" 0 "AuxChannelOff";
VAL_ 2566838782 AuxI_O08 3 "NotAvailable" 2 "Error" 1 "AuxChannelOn" 0 "AuxChannelOff";
VAL_ 2566838782 AuxI_O07 3 "NotAvailable" 2 "Error" 1 "AuxChannelOn" 0 "AuxChannelOff";
VAL_ 2566838782 AuxI_O06 3 "NotAvailable" 2 "Error" 1 "AuxChannelOn" 0 "AuxChannelOff";
VAL_ 2566838782 AuxI_O05 3 "NotAvailable" 2 "Error" 1 "AuxChannelOn" 0 "AuxChannelOff";
VAL_ 2566838782 AuxI_O04 3 "NotAvailable" 2 "Error" 1 "AuxChannelOn" 0 "AuxChannelOff";
VAL_ 2566838782 AuxI_O03 3 "NotAvailable" 2 "Error" 1 "AuxChannelOn" 0 "AuxChannelOff";
VAL_ 2566838782 AuxI_O02 3 "NotAvailable" 2 "Error" 1 "AuxChannelOn" 0 "AuxChannelOff";
VAL_ 2566838782 AuxI_O01 3 "NotAvailable" 2 "Error" 1 "AuxChannelOn" 0 "AuxChannelOff";
VAL_ 2561146622 AuxI_O45 3 "NtAvlblTkNoActionDependingOnApp" 2 "ErrrIndctrNotUsedDependingOnApp" 1 "AuxChannelOn" 0 "AuxChannelOff";
VAL_ 2561146622 AuxI_O46 3 "NtAvlblTkNoActionDependingOnApp" 2 "ErrrIndctrNotUsedDependingOnApp" 1 "AuxChannelOn" 0 "AuxChannelOff";
VAL_ 2561146622 AuxI_O47 3 "NtAvlblTkNoActionDependingOnApp" 2 "ErrrIndctrNotUsedDependingOnApp" 1 "AuxChannelOn" 0 "AuxChannelOff";
VAL_ 2561146622 AuxI_O48 3 "NtAvlblTkNoActionDependingOnApp" 2 "ErrrIndctrNotUsedDependingOnApp" 1 "AuxChannelOn" 0 "AuxChannelOff";
VAL_ 2561146622 AuxI_O41 3 "NtAvlblTkNoActionDependingOnApp" 2 "ErrrIndctrNotUsedDependingOnApp" 1 "AuxChannelOn" 0 "AuxChannelOff";
VAL_ 2561146622 AuxI_O42 3 "NtAvlblTkNoActionDependingOnApp" 2 "ErrrIndctrNotUsedDependingOnApp" 1 "AuxChannelOn" 0 "AuxChannelOff";
VAL_ 2561146622 AuxI_O43 3 "NtAvlblTkNoActionDependingOnApp" 2 "ErrrIndctrNotUsedDependingOnApp" 1 "AuxChannelOn" 0 "AuxChannelOff";
VAL_ 2561146622 AuxI_O44 3 "NtAvlblTkNoActionDependingOnApp" 2 "ErrrIndctrNotUsedDependingOnApp" 1 "AuxChannelOn" 0 "AuxChannelOff";
VAL_ 2561146622 AuxI_O37 3 "NtAvlblTkNoActionDependingOnApp" 2 "ErrrIndctrNotUsedDependingOnApp" 1 "AuxChannelOn" 0 "AuxChannelOff";
VAL_ 2561146622 AuxI_O38 3 "NtAvlblTkNoActionDependingOnApp" 2 "ErrrIndctrNotUsedDependingOnApp" 1 "AuxChannelOn" 0 "AuxChannelOff";
VAL_ 2561146622 AuxI_O39 3 "NtAvlblTkNoActionDependingOnApp" 2 "ErrrIndctrNotUsedDependingOnApp" 1 "AuxChannelOn" 0 "AuxChannelOff";
VAL_ 2561146622 AuxI_O40 3 "NtAvlblTkNoActionDependingOnApp" 2 "ErrrIndctrNotUsedDependingOnApp" 1 "AuxChannelOn" 0 "AuxChannelOff";
VAL_ 2561146622 AuxI_O33 3 "NtAvlblTkNoActionDependingOnApp" 2 "ErrrIndctrNotUsedDependingOnApp" 1 "AuxChannelOn" 0 "AuxChannelOff";
VAL_ 2561146622 AuxI_O34 3 "NtAvlblTkNoActionDependingOnApp" 2 "ErrrIndctrNotUsedDependingOnApp" 1 "AuxChannelOn" 0 "AuxChannelOff";
VAL_ 2561146622 AuxI_O35 3 "NtAvlblTkNoActionDependingOnApp" 2 "ErrrIndctrNotUsedDependingOnApp" 1 "AuxChannelOn" 0 "AuxChannelOff";
VAL_ 2561146622 AuxI_O36 3 "NtAvlblTkNoActionDependingOnApp" 2 "ErrrIndctrNotUsedDependingOnApp" 1 "AuxChannelOn" 0 "AuxChannelOff";
VAL_ 2561146622 AuxI_O29 3 "NtAvlblTkNoActionDependingOnApp" 2 "ErrrIndctrNotUsedDependingOnApp" 1 "AuxChannelOn" 0 "AuxChannelOff";
VAL_ 2561146622 AuxI_O30 3 "NtAvlblTkNoActionDependingOnApp" 2 "ErrrIndctrNotUsedDependingOnApp" 1 "AuxChannelOn" 0 "AuxChannelOff";
VAL_ 2561146622 AuxI_O31 3 "NtAvlblTkNoActionDependingOnApp" 2 "ErrrIndctrNotUsedDependingOnApp" 1 "AuxChannelOn" 0 "AuxChannelOff";
VAL_ 2561146622 AuxI_O32 3 "NtAvlblTkNoActionDependingOnApp" 2 "ErrrIndctrNotUsedDependingOnApp" 1 "AuxChannelOn" 0 "AuxChannelOff";
VAL_ 2561146622 AuxI_O25 3 "NtAvlblTkNoActionDependingOnApp" 2 "ErrrIndctrNotUsedDependingOnApp" 1 "AuxChannelOn" 0 "AuxChannelOff";
VAL_ 2561146622 AuxI_O26 3 "NtAvlblTkNoActionDependingOnApp" 2 "ErrrIndctrNotUsedDependingOnApp" 1 "AuxChannelOn" 0 "AuxChannelOff";
VAL_ 2561146622 AuxI_O27 3 "NtAvlblTkNoActionDependingOnApp" 2 "ErrrIndctrNotUsedDependingOnApp" 1 "AuxChannelOn" 0 "AuxChannelOff";
VAL_ 2561146622 AuxI_O28 3 "NtAvlblTkNoActionDependingOnApp" 2 "ErrrIndctrNotUsedDependingOnApp" 1 "AuxChannelOn" 0 "AuxChannelOff";
VAL_ 2561146622 AuxI_O21 3 "NtAvlblTkNoActionDependingOnApp" 2 "ErrrIndctrNotUsedDependingOnApp" 1 "AuxChannelOn" 0 "AuxChannelOff";
VAL_ 2561146622 AuxI_O22 3 "NtAvlblTkNoActionDependingOnApp" 2 "ErrrIndctrNotUsedDependingOnApp" 1 "AuxChannelOn" 0 "AuxChannelOff";
VAL_ 2561146622 AuxI_O23 3 "NtAvlblTkNoActionDependingOnApp" 2 "ErrrIndctrNotUsedDependingOnApp" 1 "AuxChannelOn" 0 "AuxChannelOff";
VAL_ 2561146622 AuxI_O24 3 "NtAvlblTkNoActionDependingOnApp" 2 "ErrrIndctrNotUsedDependingOnApp" 1 "AuxChannelOn" 0 "AuxChannelOff";
VAL_ 2561146622 AuxI_O17 3 "NtAvlblTkNoActionDependingOnApp" 2 "ErrrIndctrNotUsedDependingOnApp" 1 "AuxChannelOn" 0 "AuxChannelOff";
VAL_ 2561146622 AuxI_O18 3 "NtAvlblTkNoActionDependingOnApp" 2 "ErrrIndctrNotUsedDependingOnApp" 1 "AuxChannelOn" 0 "AuxChannelOff";
VAL_ 2561146622 AuxI_O19 3 "NtAvlblTkNoActionDependingOnApp" 2 "ErrrIndctrNotUsedDependingOnApp" 1 "AuxChannelOn" 0 "AuxChannelOff";
VAL_ 2561146622 AuxI_O20 3 "NtAvlblTkNoActionDependingOnApp" 2 "ErrrIndctrNotUsedDependingOnApp" 1 "AuxChannelOn" 0 "AuxChannelOff";
VAL_ 2561081086 AuxI_O77 3 "NtAvlblTkNoActionDependingOnApp" 2 "ErrrIndctrNotUsedDependingOnApp" 1 "AuxChannelOn" 0 "AuxChannelOff";
VAL_ 2561081086 AuxI_O78 3 "NtAvlblTkNoActionDependingOnApp" 2 "ErrrIndctrNotUsedDependingOnApp" 1 "AuxChannelOn" 0 "AuxChannelOff";
VAL_ 2561081086 AuxI_O79 3 "NtAvlblTkNoActionDependingOnApp" 2 "ErrrIndctrNotUsedDependingOnApp" 1 "AuxChannelOn" 0 "AuxChannelOff";
VAL_ 2561081086 AuxI_O80 3 "NtAvlblTkNoActionDependingOnApp" 2 "ErrrIndctrNotUsedDependingOnApp" 1 "AuxChannelOn" 0 "AuxChannelOff";
VAL_ 2561081086 AuxI_O73 3 "NtAvlblTkNoActionDependingOnApp" 2 "ErrrIndctrNotUsedDependingOnApp" 1 "AuxChannelOn" 0 "AuxChannelOff";
VAL_ 2561081086 AuxI_O74 3 "NtAvlblTkNoActionDependingOnApp" 2 "ErrrIndctrNotUsedDependingOnApp" 1 "AuxChannelOn" 0 "AuxChannelOff";
VAL_ 2561081086 AuxI_O75 3 "NtAvlblTkNoActionDependingOnApp" 2 "ErrrIndctrNotUsedDependingOnApp" 1 "AuxChannelOn" 0 "AuxChannelOff";
VAL_ 2561081086 AuxI_O76 3 "NtAvlblTkNoActionDependingOnApp" 2 "ErrrIndctrNotUsedDependingOnApp" 1 "AuxChannelOn" 0 "AuxChannelOff";
VAL_ 2561081086 AuxI_O69 3 "NtAvlblTkNoActionDependingOnApp" 2 "ErrrIndctrNotUsedDependingOnApp" 1 "AuxChannelOn" 0 "AuxChannelOff";
VAL_ 2561081086 AuxI_O70 3 "NtAvlblTkNoActionDependingOnApp" 2 "ErrrIndctrNotUsedDependingOnApp" 1 "AuxChannelOn" 0 "AuxChannelOff";
VAL_ 2561081086 AuxI_O71 3 "NtAvlblTkNoActionDependingOnApp" 2 "ErrrIndctrNotUsedDependingOnApp" 1 "AuxChannelOn" 0 "AuxChannelOff";
VAL_ 2561081086 AuxI_O72 3 "NtAvlblTkNoActionDependingOnApp" 2 "ErrrIndctrNotUsedDependingOnApp" 1 "AuxChannelOn" 0 "AuxChannelOff";
VAL_ 2561081086 AuxI_O65 3 "NtAvlblTkNoActionDependingOnApp" 2 "ErrrIndctrNotUsedDependingOnApp" 1 "AuxChannelOn" 0 "AuxChannelOff";
VAL_ 2561081086 AuxI_O66 3 "NtAvlblTkNoActionDependingOnApp" 2 "ErrrIndctrNotUsedDependingOnApp" 1 "AuxChannelOn" 0 "AuxChannelOff";
VAL_ 2561081086 AuxI_O67 3 "NtAvlblTkNoActionDependingOnApp" 2 "ErrrIndctrNotUsedDependingOnApp" 1 "AuxChannelOn" 0 "AuxChannelOff";
VAL_ 2561081086 AuxI_O68 3 "NtAvlblTkNoActionDependingOnApp" 2 "ErrrIndctrNotUsedDependingOnApp" 1 "AuxChannelOn" 0 "AuxChannelOff";
VAL_ 2561081086 AuxI_O61 3 "NtAvlblTkNoActionDependingOnApp" 2 "ErrrIndctrNotUsedDependingOnApp" 1 "AuxChannelOn" 0 "AuxChannelOff";
VAL_ 2561081086 AuxI_O62 3 "NtAvlblTkNoActionDependingOnApp" 2 "ErrrIndctrNotUsedDependingOnApp" 1 "AuxChannelOn" 0 "AuxChannelOff";
VAL_ 2561081086 AuxI_O63 3 "NtAvlblTkNoActionDependingOnApp" 2 "ErrrIndctrNotUsedDependingOnApp" 1 "AuxChannelOn" 0 "AuxChannelOff";
VAL_ 2561081086 AuxI_O64 3 "NtAvlblTkNoActionDependingOnApp" 2 "ErrrIndctrNotUsedDependingOnApp" 1 "AuxChannelOn" 0 "AuxChannelOff";
VAL_ 2561081086 AuxI_O57 3 "NtAvlblTkNoActionDependingOnApp" 2 "ErrrIndctrNotUsedDependingOnApp" 1 "AuxChannelOn" 0 "AuxChannelOff";
VAL_ 2561081086 AuxI_O58 3 "NtAvlblTkNoActionDependingOnApp" 2 "ErrrIndctrNotUsedDependingOnApp" 1 "AuxChannelOn" 0 "AuxChannelOff";
VAL_ 2561081086 AuxI_O59 3 "NtAvlblTkNoActionDependingOnApp" 2 "ErrrIndctrNotUsedDependingOnApp" 1 "AuxChannelOn" 0 "AuxChannelOff";
VAL_ 2561081086 AuxI_O60 3 "NtAvlblTkNoActionDependingOnApp" 2 "ErrrIndctrNotUsedDependingOnApp" 1 "AuxChannelOn" 0 "AuxChannelOff";
VAL_ 2561081086 AuxI_O53 3 "NtAvlblTkNoActionDependingOnApp" 2 "ErrrIndctrNotUsedDependingOnApp" 1 "AuxChannelOn" 0 "AuxChannelOff";
VAL_ 2561081086 AuxI_O54 3 "NtAvlblTkNoActionDependingOnApp" 2 "ErrrIndctrNotUsedDependingOnApp" 1 "AuxChannelOn" 0 "AuxChannelOff";
VAL_ 2561081086 AuxI_O55 3 "NtAvlblTkNoActionDependingOnApp" 2 "ErrrIndctrNotUsedDependingOnApp" 1 "AuxChannelOn" 0 "AuxChannelOff";
VAL_ 2561081086 AuxI_O56 3 "NtAvlblTkNoActionDependingOnApp" 2 "ErrrIndctrNotUsedDependingOnApp" 1 "AuxChannelOn" 0 "AuxChannelOff";
VAL_ 2561081086 AuxI_O49 3 "NtAvlblTkNoActionDependingOnApp" 2 "ErrrIndctrNotUsedDependingOnApp" 1 "AuxChannelOn" 0 "AuxChannelOff";
VAL_ 2561081086 AuxI_O50 3 "NtAvlblTkNoActionDependingOnApp" 2 "ErrrIndctrNotUsedDependingOnApp" 1 "AuxChannelOn" 0 "AuxChannelOff";
VAL_ 2561081086 AuxI_O51 3 "NtAvlblTkNoActionDependingOnApp" 2 "ErrrIndctrNotUsedDependingOnApp" 1 "AuxChannelOn" 0 "AuxChannelOff";
VAL_ 2561081086 AuxI_O52 3 "NtAvlblTkNoActionDependingOnApp" 2 "ErrrIndctrNotUsedDependingOnApp" 1 "AuxChannelOn" 0 "AuxChannelOff";
VAL_ 2561015550 AuxI_O92 3 "NtAvlblTkNoActionDependingOnApp" 2 "ErrrIndctrNotUsedDependingOnApp" 1 "AuxChannelOn" 0 "AuxChannelOff";
VAL_ 2561015550 AuxI_O85 3 "NtAvlblTkNoActionDependingOnApp" 2 "ErrrIndctrNotUsedDependingOnApp" 1 "AuxChannelOn" 0 "AuxChannelOff";
VAL_ 2561015550 AuxI_O86 3 "NtAvlblTkNoActionDependingOnApp" 2 "ErrrIndctrNotUsedDependingOnApp" 1 "AuxChannelOn" 0 "AuxChannelOff";
VAL_ 2561015550 AuxI_O87 3 "NtAvlblTkNoActionDependingOnApp" 2 "ErrrIndctrNotUsedDependingOnApp" 1 "AuxChannelOn" 0 "AuxChannelOff";
VAL_ 2561015550 AuxI_O88 3 "NtAvlblTkNoActionDependingOnApp" 2 "ErrrIndctrNotUsedDependingOnApp" 1 "AuxChannelOn" 0 "AuxChannelOff";
VAL_ 2561015550 AuxI_O81 3 "NtAvlblTkNoActionDependingOnApp" 2 "ErrrIndctrNotUsedDependingOnApp" 1 "AuxChannelOn" 0 "AuxChannelOff";
VAL_ 2561015550 AuxI_O82 3 "NtAvlblTkNoActionDependingOnApp" 2 "ErrrIndctrNotUsedDependingOnApp" 1 "AuxChannelOn" 0 "AuxChannelOff";
VAL_ 2561015550 AuxI_O83 3 "NtAvlblTkNoActionDependingOnApp" 2 "ErrrIndctrNotUsedDependingOnApp" 1 "AuxChannelOn" 0 "AuxChannelOff";
VAL_ 2561015550 AuxI_O84 3 "NtAvlblTkNoActionDependingOnApp" 2 "ErrrIndctrNotUsedDependingOnApp" 1 "AuxChannelOn" 0 "AuxChannelOff";
VAL_ 2561015550 AuxI_O109 3 "NtAvlblTkNoActionDependingOnApp" 2 "ErrrIndctrNotUsedDependingOnApp" 1 "AuxChannelOn" 0 "AuxChannelOff";
VAL_ 2561015550 AuxI_O110 3 "NtAvlblTkNoActionDependingOnApp" 2 "ErrrIndctrNotUsedDependingOnApp" 1 "AuxChannelOn" 0 "AuxChannelOff";
VAL_ 2561015550 AuxI_O111 3 "NtAvlblTkNoActionDependingOnApp" 2 "ErrrIndctrNotUsedDependingOnApp" 1 "AuxChannelOn" 0 "AuxChannelOff";
VAL_ 2561015550 AuxI_O112 3 "NtAvlblTkNoActionDependingOnApp" 2 "ErrrIndctrNotUsedDependingOnApp" 1 "AuxChannelOn" 0 "AuxChannelOff";
VAL_ 2561015550 AuxI_O105 3 "NtAvlblTkNoActionDependingOnApp" 2 "ErrrIndctrNotUsedDependingOnApp" 1 "AuxChannelOn" 0 "AuxChannelOff";
VAL_ 2561015550 AuxI_O106 3 "NtAvlblTkNoActionDependingOnApp" 2 "ErrrIndctrNotUsedDependingOnApp" 1 "AuxChannelOn" 0 "AuxChannelOff";
VAL_ 2561015550 AuxI_O107 3 "NtAvlblTkNoActionDependingOnApp" 2 "ErrrIndctrNotUsedDependingOnApp" 1 "AuxChannelOn" 0 "AuxChannelOff";
VAL_ 2561015550 AuxI_O108 3 "NtAvlblTkNoActionDependingOnApp" 2 "ErrrIndctrNotUsedDependingOnApp" 1 "AuxChannelOn" 0 "AuxChannelOff";
VAL_ 2561015550 AuxI_O101 2 "ErrrIndctrNotUsedDependingOnApp" 1 "AuxChannelOn" 0 "AuxChannelOff" 3 "NtAvlblTkNoActionDependingOnApp";
VAL_ 2561015550 AuxI_O102 3 "NtAvlblTkNoActionDependingOnApp" 2 "ErrrIndctrNotUsedDependingOnApp" 1 "AuxChannelOn" 0 "AuxChannelOff";
VAL_ 2561015550 AuxI_O103 3 "NtAvlblTkNoActionDependingOnApp" 2 "ErrrIndctrNotUsedDependingOnApp" 1 "AuxChannelOn" 0 "AuxChannelOff";
VAL_ 2561015550 AuxI_O104 3 "NtAvlblTkNoActionDependingOnApp" 2 "ErrrIndctrNotUsedDependingOnApp" 1 "AuxChannelOn" 0 "AuxChannelOff";
VAL_ 2561015550 AuxI_O97 3 "NtAvlblTkNoActionDependingOnApp" 2 "ErrrIndctrNotUsedDependingOnApp" 1 "AuxChannelOn" 0 "AuxChannelOff";
VAL_ 2561015550 AuxI_O98 3 "NtAvlblTkNoActionDependingOnApp" 2 "ErrrIndctrNotUsedDependingOnApp" 1 "AuxChannelOn" 0 "AuxChannelOff";
VAL_ 2561015550 AuxI_O99 3 "NtAvlblTkNoActionDependingOnApp" 2 "ErrrIndctrNotUsedDependingOnApp" 1 "AuxChannelOn" 0 "AuxChannelOff";
VAL_ 2561015550 AuxI_O100 3 "NtAvlblTkNoActionDependingOnApp" 2 "ErrrIndctrNotUsedDependingOnApp" 1 "AuxChannelOn" 0 "AuxChannelOff";
VAL_ 2561015550 AuxI_O93 3 "NtAvlblTkNoActionDependingOnApp" 2 "ErrrIndctrNotUsedDependingOnApp" 1 "AuxChannelOn" 0 "AuxChannelOff";
VAL_ 2561015550 AuxI_O94 3 "NtAvlblTkNoActionDependingOnApp" 2 "ErrrIndctrNotUsedDependingOnApp" 1 "AuxChannelOn" 0 "AuxChannelOff";
VAL_ 2561015550 AuxI_O95 3 "NtAvlblTkNoActionDependingOnApp" 2 "ErrrIndctrNotUsedDependingOnApp" 1 "AuxChannelOn" 0 "AuxChannelOff";
VAL_ 2561015550 AuxI_O96 3 "NtAvlblTkNoActionDependingOnApp" 2 "ErrrIndctrNotUsedDependingOnApp" 1 "AuxChannelOn" 0 "AuxChannelOff";
VAL_ 2561015550 AuxI_O89 3 "NtAvlblTkNoActionDependingOnApp" 2 "ErrrIndctrNotUsedDependingOnApp" 1 "AuxChannelOn" 0 "AuxChannelOff";
VAL_ 2561015550 AuxI_O90 3 "NtAvlblTkNoActionDependingOnApp" 2 "ErrrIndctrNotUsedDependingOnApp" 1 "AuxChannelOn" 0 "AuxChannelOff";
VAL_ 2561015550 AuxI_O91 3 "NtAvlblTkNoActionDependingOnApp" 2 "ErrrIndctrNotUsedDependingOnApp" 1 "AuxChannelOn" 0 "AuxChannelOff";
VAL_ 2566746622 TrailerBrakeStrokeAxle5Right 7 "NotAvailable" 6 "SensorError" 5 "Reserved" 3 "DraggingBrake" 2 "Overstroke" 1 "Nonfunctioning" 0 "OK";
VAL_ 2566746622 TrailerBrakeStrokeAxle5Left 7 "NotAvailable" 6 "SensorError" 5 "Reserved" 3 "DraggingBrake" 2 "Overstroke" 1 "Nonfunctioning" 0 "OK";
VAL_ 2566746622 TrailerBrakeStrokeAxle4Right 7 "NotAvailable" 6 "SensorError" 5 "Reserved" 3 "DraggingBrake" 2 "Overstroke" 1 "Nonfunctioning" 0 "OK";
VAL_ 2566746622 TrailerBrakeStrokeAxle4Left 7 "NotAvailable" 6 "SensorError" 5 "Reserved" 3 "DraggingBrake" 2 "Overstroke" 1 "Nonfunctioning" 0 "OK";
VAL_ 2566746622 TrailerBrakeStrokeAxle3Right 7 "NotAvailable" 6 "SensorError" 5 "Reserved" 3 "DraggingBrake" 2 "Overstroke" 1 "Nonfunctioning" 0 "OK";
VAL_ 2566746622 TrailerBrakeStrokeAxle3Left 7 "NotAvailable" 6 "SensorError" 5 "Reserved" 3 "DraggingBrake" 2 "Overstroke" 1 "Nonfunctioning" 0 "OK";
VAL_ 2566746622 TrailerBrakeStrokeAxle2Right 7 "NotAvailable" 6 "SensorError" 5 "Reserved" 3 "DraggingBrake" 2 "Overstroke" 1 "Nonfunctioning" 0 "OK";
VAL_ 2566746622 TrailerBrakeStrokeAxle2Left 7 "NotAvailable" 6 "SensorError" 5 "Reserved" 3 "DraggingBrake" 2 "Overstroke" 1 "Nonfunctioning" 0 "OK";
VAL_ 2566746622 TrailerBrakeStrokeAxle1Right 7 "NotAvailable" 6 "SensorError" 5 "Reserved" 3 "DraggingBrake" 2 "Overstroke" 1 "Nonfunctioning" 0 "OK";
VAL_ 2566746622 TrailerBrakeStrokeAxle1Left 7 "NotAvailable" 6 "SensorError" 5 "Reserved" 3 "DraggingBrake" 2 "Overstroke" 1 "Nonfunctioning" 0 "OK";
VAL_ 2566746622 TractorBrakeStrokeAxle5Right 7 "NotAvailable" 6 "SensorError" 5 "Reserved" 3 "DraggingBrake" 2 "Overstroke" 1 "Nonfunctioning" 0 "OK";
VAL_ 2566746622 TractorBrakeStrokeAxle5Left 7 "NotAvailable" 6 "SensorError" 5 "Reserved" 3 "DraggingBrake" 2 "Overstroke" 1 "Nonfunctioning" 0 "OK";
VAL_ 2566746622 TractorBrakeStrokeAxle4Right 7 "NotAvailable" 6 "SensorError" 5 "Reserved" 3 "DraggingBrake" 2 "Overstroke" 1 "Nonfunctioning" 0 "OK";
VAL_ 2566746622 TractorBrakeStrokeAxle4Left 7 "NotAvailable" 6 "SensorError" 5 "Reserved" 3 "DraggingBrake" 2 "Overstroke" 1 "Nonfunctioning" 0 "OK";
VAL_ 2566746622 TractorBrakeStrokeAxle3Right 7 "NotAvailable" 6 "SensorError" 5 "Reserved" 3 "DraggingBrake" 2 "Overstroke" 1 "Nonfunctioning" 0 "OK";
VAL_ 2566746622 TractorBrakeStrokeAxle3Left 7 "NotAvailable" 6 "SensorError" 5 "Reserved" 3 "DraggingBrake" 2 "Overstroke" 1 "Nonfunctioning" 0 "OK";
VAL_ 2566746622 TractorBrakeStrokeAxle2Right 7 "NotAvailable" 6 "SensorError" 5 "Reserved" 3 "DraggingBrake" 2 "Overstroke" 1 "Nonfunctioning" 0 "OK";
VAL_ 2566746622 TractorBrakeStrokeAxle2Left 7 "NotAvailable" 6 "SensorError" 5 "Reserved" 3 "DraggingBrake" 2 "Overstroke" 1 "Nonfunctioning" 0 "OK";
VAL_ 2566746622 TractorBrakeStrokeAxle1Right 7 "NotAvailable" 6 "SensorError" 5 "Reserved" 3 "DraggingBrake" 2 "Overstroke" 1 "Nonfunctioning" 0 "OK";
VAL_ 2566746622 TractorBrakeStrokeAxle1Left 7 "NotAvailable" 6 "SensorError" 5 "Reserved" 3 "DraggingBrake" 2 "Overstroke" 1 "Nonfunctioning" 0 "OK";
VAL_ 2566827774 AirCompressorStatus 3 "NotAvailable" 2 "ErrorIndicator" 1 "CompressorActive" 0 "CompressorNotActive";
VAL_ 2566803966 ACCUsageDemand 3 "dontCare" 2 "reserved" 1 "drvrDmndFrUsngACCDstncKpingCtrl" 0 "drvrDmndFrNtUsngACCDstncKpngCtr";
VAL_ 2566803966 RqedACCDistanceMode 7 "notAvailable" 6 "errorCondition" 5 "notDefined" 4 "RqedACCDistanceMode5" 3 "RqedACCDistanceMode4" 2 "RqedACCDistanceMode3" 1 "RqedACCDistanceMode2" 0 "RqedACCDistanceMode1";
VAL_ 2432593918 ForwardCollisionWarning 3 "notAvailable" 2 "ErrorIndicator" 1 "CollisionIsImminent" 0 "NoWarning";
VAL_ 2432593918 ACCDistanceAlertSignal 3 "TakeNoAction" 2 "Reserved" 1 "ACCDASActive" 0 "ACCDASNotActive";
VAL_ 2432593918 ACCSystemShutoffWarning 3 "TakeNoAction" 2 "Reserved" 1 "ACCSSOWActive" 0 "ACCSSOWNotActive";
VAL_ 2432593918 ACCTargetDetected 3 "TakeNoAction" 2 "Reserved" 1 "TargetDetected" 0 "NoTargetsDetected";
VAL_ 2432593918 AdptveCruiseCtrlSetDistanceMode 7 "NotAvailable_NotValid" 6 "ErrorCondition" 5 "ConventionalCruiseCtrlMode" 4 "ACCDistanceMode5" 3 "ACCDistanceMode4" 2 "ACCDistanceMode3" 1 "ACCDistanceMode2" 0 "ACCDistanceMode1";
VAL_ 2432593918 AdaptiveCruiseCtrlMode 7 "NotAvailable_NotValid" 6 "DsbldErrrCndtnUsdTIndctThtACCIs" 5 "FinishMode" 4 "HldMdUsdTIndctThtACCHsLstThPrvs" 3 "OvertakeMode" 2 "DstncCtrlActvUsdTIndctThtACCIsO" 1 "SpeedCtrlActive" 0 "OffUsdTIndctACCIsEnbldInClbCnfg";
VAL_ 2565406462 ControlByte 3 "CannotRespond" 2 "AccessDenied" 1 "NACK" 0 "ACK";
VAL_ 2566803198 Status2OfDoors 3 "notAvailable" 2 "error" 1 "atLeast1BusDoorEnabled" 0 "allBusDoorsAreDisabled";
VAL_ 2566803198 Ramp_WheelChairLiftPos 3 "NotAvailable" 2 "Error" 1 "OutsideBus" 0 "InsideBus";
VAL_ 2566803198 PosOfDoors 15 "NotAvailable" 14 "Error" 3 "1101NotDefined" 2 "AllDoorsClosed" 1 "ClosingLastDoor" 0 "AtLeast1DoorIsOpen";
VAL_ 2565870334 FifthWheelRollWarningIndicator 3 "NotAvailable" 2 "error" 1 "LimitExceeded" 0 "LimitNotExceeded";
VAL_ 2566762238 FifthWheelSliderLockIndicator 3 "NotAvailable" 2 "Error" 1 "Locked" 0 "NotLocked";
VAL_ 2566762238 FfthWhlLckCoupleStatusIndicator 3 "NotAvailable" 2 "Error" 1 "SuccessfulCoupleDetected" 0 "IncmpltBdCplTrckShuldNotBeMoved";
VAL_ 2566762238 FfthWhlLckRadyToCoupleIndicator 3 "NotAvailable" 2 "Error" 1 "LockOpenReadyToCouple" 0 "LockNotOpenNotReadyToCouple";
VAL_ 2566762238 FifthWheelErrorStatus 15 "NotAvailable" 9 "Kingpin_LockOpen" 8 "KingpinMissingMoreThan5Seconds" 7 "CouplingTimingError" 6 "CouplingSequenceError_Kingpin" 5 "CouplingSequenceError" 14 "NotUsed" 2 "Kingpin_LocksOpenAtStartup" 1 "LocksClosed_NoKingpinAtStartup" 0 "ImproperCouple";
VAL_ 2364543998 PitchAndRollCompensated 1 "NotAvailable" 0 "CompensationOn" 3 "NotAvailable" 2 "Error";
VAL_ 2364543998 PitchRateFigureOfMerit 1 "NotAvailable" 0 "PtchRtDgrddDtIsSspctDTEnvrnmntl" 3 "NotAvailable" 2 "Error";
VAL_ 2364543998 RollAngleFigureOfMerit 1 "RollAngleDegraded" 0 "RollAngleFullyFunctional" 3 "NotAvailable" 2 "Error";
VAL_ 2364543998 PitchAngleFigureOfMerit 1 "NotAvailable" 0 "PtchAnglDgrddDtIsSspctDTEnvrnmn" 3 "NotAvailable" 2 "Error";
VAL_ 2566846718 TransOilLevelMeasurementStatus 15 "NotAvailable" 14 "Error" 13 "ConditionsNotValidOther" 12 "NotDefined" 9 "CnditionsNotValidNoRqForReading" 8 "CndtionsNotValidEngSpeedTooHigh" 7 "CnditionsNotValidEngSpeedTooLow" 6 "CndtionsNotValidVehicleNotLevel" 5 "CndtnsNtVldVhclMvngOtptShftSpdT" 4 "CndtnsNtVldTrnsFluidTempTooHigh" 3 "CndtnsNtVldTransFluidTempTooLow" 2 "ConditionsNotValidTransInGear" 1 "CndtnsNtVldSttlngTmrStllCntngDw" 0 "CndtnsVldFrTrnsOlLvlMeasurement";
VAL_ 2566846718 TransOilLevelCountdownTimer 15 "NotAvailable" 14 "Error" 13 "ThirteenMinutes" 12 "TwelveMinutes" 11 "ElevenMinutes" 10 "TenMinutes" 9 "NineMinutes" 8 "EightMinutes" 7 "SevenMinutes" 6 "SixMinutes" 5 "FiveMinutes" 4 "FourMinutes" 3 "ThreeMinutes" 2 "TwoMinutes" 1 "OneMinute" 0 "lessThan1Minute";
VAL_ 2566846718 TransOilLevelHigh_Low 251 "CondNotAcceptableForValidMeasure";
VAL_ 2566760702 WrlessCommunicationNetworkType2 1 "CellularNetwork2" 0 "CellularNetwork1";
VAL_ 2566760702 NetworkAntennaStatus2 1 "On" 0 "Off";
VAL_ 2566760702 NetworkServiceStatus2 1 "RoamingService" 0 "LocalService";
VAL_ 2566760702 NetworkTransceiverStatus2 1 "On" 0 "Off";
VAL_ 2566760958 WrlessCommunicationNetworkType1 1 "CellularNetwork2" 0 "CellularNetwork1";
VAL_ 2566760958 NetworkAntennaStatus1 1 "On" 0 "Off";
VAL_ 2566760958 NetworkServiceStatus1 1 "RoamingService" 0 "LocalService";
VAL_ 2566760958 NetworkTransceiverStatus1 1 "On" 0 "Off";
VAL_ 2633869310 VoltageRegulatorEnabled 3 "NotAvailable" 2 "Error" 1 "RegulatingVoltage" 0 "NtRegulatingVoltageUnitDisabled";
VAL_ 2633869310 VoltageRegulatorSoftStartState 3 "NotAvailable" 2 "Error" 1 "SoftStartIsActive" 0 "SoftStartIsInactive";
VAL_ 2633869310 VltgRgltrUndrfrqncyCmpnstnEnbld 3 "NotAvailable" 2 "Error" 1 "UndrfrquencyCompensationEnabled" 0 "UndrfrqencyCompensationDisabled";
VAL_ 2633869310 VltgRgltrVAr_PwrFctrOprtingMode 7 "NotAvailable" 6 "Error" 5 "Reserved" 2 "VArRegulationEnabled" 1 "PowerFactorRegulationEnabled" 0 "VAr_PwrFactorRegulationDisabled";
VAL_ 2633869310 VltgRglatorLoadCompensationMode 7 "NotAvailable" 6 "Error" 5 "Reserved" 2 "IRLineDropCompensationEnabled" 1 "VoltageDroopCompensationEnabled" 0 "LoadCompensationDisabled";
